VERSION ""

NS_ :

BS_:

BU_: MCTM_LS TIM_LS EOCM2cp_K2_LS EOCM2cp_K1_LS ADIMa_LS BCM_LS SAM_SR_LS SAM_SL_LS SAM_PR_LS SAM_PL_LS CGM3a_LS Dummy_LS VICM_LS ECC_LS PEPS_LS AOS_LS SDM_PR_LS AOS2_LS DLM_LS SCCM_2_LS SCCM_1_LS UPA_LS ADIMb_LS

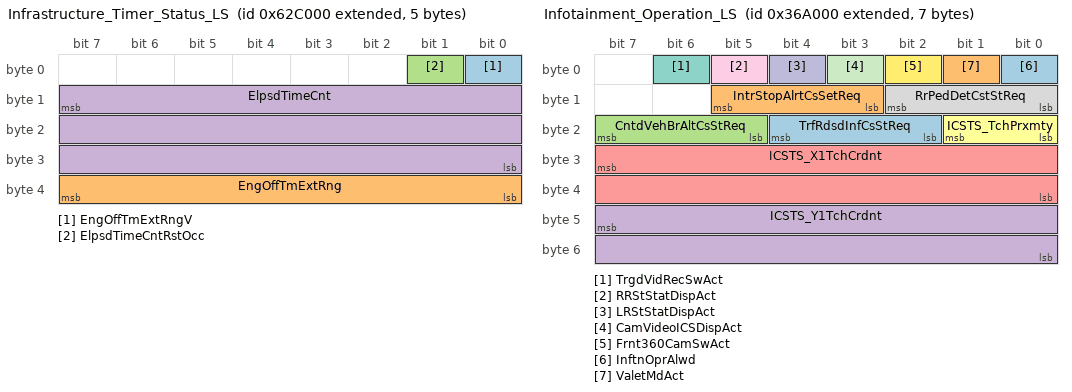
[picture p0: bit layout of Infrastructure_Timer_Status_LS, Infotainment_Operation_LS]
BO_ 2153955328 Infrastructure_Timer_Status_LS: 5 BCM_LS
 SG_ EngOffTmExtRngV : 0|1@0+ (1,0) [0|1] ""  CGM3a_LS,ECC_LS
 SG_ EngOffTmExtRng : 39|8@0+ (4,0) [0|1020] "min"  CGM3a_LS,ECC_LS
 SG_ ElpsdTimeCntRstOcc : 1|1@0+ (1,0) [0|1] ""  CGM3a_LS
 SG_ ElpsdTimeCnt : 15|24@0+ (1,0) [0|16777215] "min"  CGM3a_LS

BO_ 2151063552 Infotainment_Operation_LS: 7 CGM3a_LS
 SG_ TrfRdsdInfCsStReq : 20|3@0+ (1,0) [0|7] "" Vector__XXX
 SG_ IntrStopAlrtCsSetReq : 13|3@0+ (1,0) [0|7] "" Vector__XXX
 SG_ CntdVehBrAltCsStReq : 23|3@0+ (1,0) [0|7] "" Vector__XXX
 SG_ ICSTS_Y1TchCrdnt : 47|16@0+ (0.001526,0) [0|100] "" Vector__XXX
 SG_ ICSTS_X1TchCrdnt : 31|16@0+ (0.001526,0) [0|100] "" Vector__XXX
 SG_ ICSTS_TchPrxmty : 17|2@0+ (1,0) [0|3] "" Vector__XXX
 SG_ TrgdVidRecSwAct : 6|1@0+ (1,0) [0|1] "" Vector__XXX
 SG_ RrPedDetCstStReq : 10|3@0+ (1,0) [0|7] "" Vector__XXX
 SG_ RRStStatDispAct : 5|1@0+ (1,0) [0|1] "" Vector__XXX
 SG_ LRStStatDispAct : 4|1@0+ (1,0) [0|1] "" Vector__XXX
 SG_ CamVideoICSDispAct : 3|1@0+ (1,0) [0|1] "" Vector__XXX
 SG_ Frnt360CamSwAct : 2|1@0+ (1,0) [0|1] "" Vector__XXX
 SG_ InftnOprAlwd : 0|1@0+ (1,0) [0|1] ""  BCM_LS,MCTM_LS
 SG_ ValetMdAct : 1|1@0+ (1,0) [0|1] ""  BCM_LS

BO_ 2157985792 Fob_Programming_Request_LS: 1 CGM3a_LS
 SG_ FobProgEvntRqd : 0|1@0+ (1,0) [0|1] ""  BCM_LS

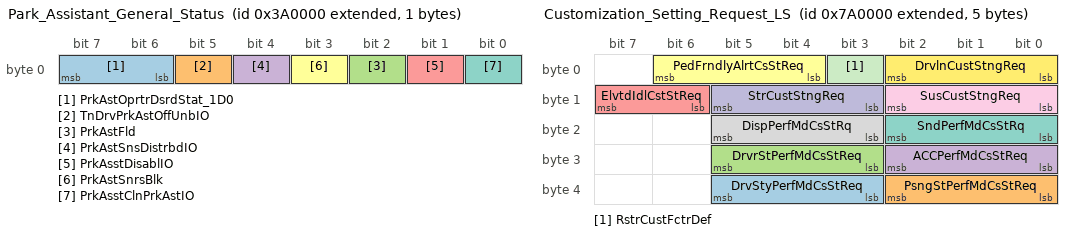
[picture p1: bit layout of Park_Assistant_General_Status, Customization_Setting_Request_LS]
BO_ 2151284736 Park_Assistant_General_Status: 1 UPA_LS
 SG_ PrkAstOprtrDsrdStat_1D0 : 7|2@0+ (1,0) [0|3] ""  CGM3a_LS
 SG_ TnDrvPrkAstOffUnbIO : 5|1@0+ (1,0) [0|1] ""  CGM3a_LS
 SG_ PrkAstFld : 2|1@0+ (1,0) [0|1] ""  CGM3a_LS
 SG_ PrkAstSnsDistrbdIO : 4|1@0+ (1,0) [0|1] ""  CGM3a_LS
 SG_ PrkAsstDisablIO : 1|1@0+ (1,0) [0|1] ""  CGM3a_LS
 SG_ PrkAstSnrsBlk : 3|1@0+ (1,0) [0|1] ""  CGM3a_LS
 SG_ PrkAsstClnPrkAstIO : 0|1@0+ (1,0) [0|1] ""  CGM3a_LS

BO_ 2151718912 Chime_Active: 1 CGM3a_LS
 SG_ ChmVolSt : 2|2@0+ (1,0) [0|3] ""  SAM_SR_LS,SAM_SL_LS,SAM_PR_LS,SAM_PL_LS,EOCM2cp_K2_LS
 SG_ ChmAct : 0|1@0+ (1,0) [0|1] ""  SAM_SR_LS,SAM_SL_LS,SAM_PR_LS,SAM_PL_LS,EOCM2cp_K2_LS,VICM_LS,UPA_LS,TIM_LS,SDM_PR_LS,MCTM_LS,BCM_LS

BO_ 2155479040 Customization_Setting_Request_LS: 5 CGM3a_LS
 SG_ DrvStyPerfMdCsStReq : 37|3@0+ (1,0) [0|7] ""  BCM_LS
 SG_ PsngStPerfMdCsStReq : 34|3@0+ (1,0) [0|7] ""  BCM_LS
 SG_ DrvrStPerfMdCsStReq : 29|3@0+ (1,0) [0|7] ""  BCM_LS
 SG_ ACCPerfMdCsStReq : 26|3@0+ (1,0) [0|7] ""  BCM_LS
 SG_ ElvtdIdlCstStReq : 15|2@0+ (1,0) [0|3] ""  BCM_LS
 SG_ PedFrndlyAlrtCsStReq : 6|3@0+ (1,0) [0|7] ""  BCM_LS
 SG_ SndPerfMdCsStRq : 18|3@0+ (1,0) [0|7] ""  BCM_LS
 SG_ DispPerfMdCsStRq : 21|3@0+ (1,0) [0|7] ""  BCM_LS
 SG_ SusCustStngReq : 10|3@0+ (1,0) [0|7] ""  BCM_LS
 SG_ StrCustStngReq : 13|3@0+ (1,0) [0|7] ""  BCM_LS
 SG_ RstrCustFctrDef : 3|1@0+ (1,0) [0|1] ""  VICM_LS,BCM_LS
 SG_ DrvlnCustStngReq : 2|3@0+ (1,0) [0|7] ""  BCM_LS

BO_ 2151383040 Reset_TP_request_LS: 1 CGM3a_LS
 SG_ TreInfMonSysRstReq : 0|1@0+ (1,0) [0|1] ""  BCM_LS

BO_ 1355 UUDT_Resp_From_EOCM2cp_K2_LS: 8 EOCM2cp_K2_LS
 SG_ DgnInf_LS54B : 7|64@0+ (1,0) [0|1.84467440737096E+019] ""  CGM3a_LS

BO_ 1611 USDT_Resp_From_EOCM2cp_K2_LS: 8 EOCM2cp_K2_LS
 SG_ DgnInf : 7|64@0+ (1,0) [0|1.84467440737096E+019] ""  CGM3a_LS

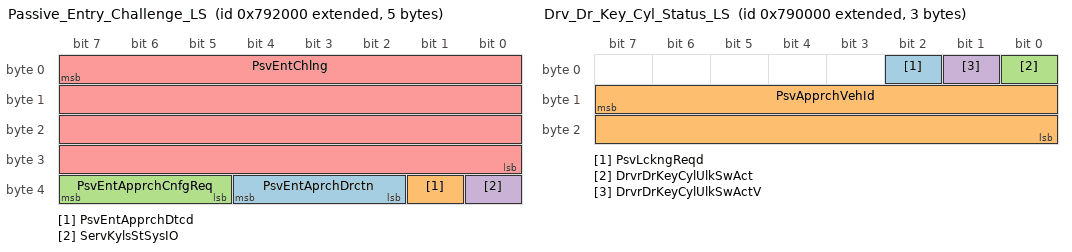
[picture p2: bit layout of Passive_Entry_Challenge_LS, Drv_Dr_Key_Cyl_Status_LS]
BO_ 2155421696 Passive_Entry_Challenge_LS: 5 PEPS_LS
 SG_ PsvEntAprchDrctn : 36|3@0+ (1,0) [0|7] ""  CGM3a_LS,BCM_LS
 SG_ PsvEntApprchDtcd : 33|1@0+ (1,0) [0|1] ""  CGM3a_LS,BCM_LS
 SG_ PsvEntApprchCnfgReq : 39|3@0+ (1,0) [0|7] ""  CGM3a_LS,BCM_LS
 SG_ ServKylsStSysIO : 32|1@0+ (1,0) [0|1] ""  CGM3a_LS
 SG_ PsvEntChlng : 7|32@0+ (1,0) [0|4294967295] "passwrd"  CGM3a_LS,BCM_LS

BO_ 2155413504 Drv_Dr_Key_Cyl_Status_LS: 3 BCM_LS
 SG_ PsvLckngReqd : 2|1@0+ (1,0) [0|1] ""  PEPS_LS,CGM3a_LS
 SG_ PsvApprchVehId : 15|16@0+ (1,0) [0|65535] ""  CGM3a_LS,PEPS_LS
 SG_ DrvrDrKeyCylUlkSwAct : 0|1@0+ (1,0) [0|1] ""  CGM3a_LS,PEPS_LS
 SG_ DrvrDrKeyCylUlkSwActV : 1|1@0+ (1,0) [0|1] ""  CGM3a_LS,PEPS_LS

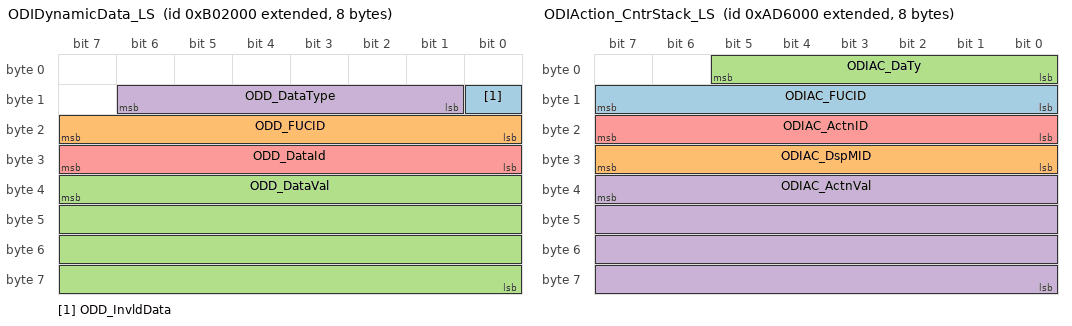
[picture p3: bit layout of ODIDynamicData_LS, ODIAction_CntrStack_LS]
BO_ 2159026176 ODIDynamicData_LS: 8 ECC_LS
 SG_ ODD_InvldData : 8|1@0+ (1,0) [0|1] ""  CGM3a_LS,MCTM_LS
 SG_ ODD_FUCID : 23|8@0+ (1,0) [0|255] ""  CGM3a_LS,MCTM_LS
 SG_ ODD_DataVal : 39|32@0+ (1,0) [0|4294967295] ""  CGM3a_LS,MCTM_LS
 SG_ ODD_DataType : 14|6@0+ (1,0) [0|63] ""  CGM3a_LS,MCTM_LS
 SG_ ODD_DataId : 31|8@0+ (1,0) [0|255] ""  CGM3a_LS,MCTM_LS

BO_ 2158936064 ODIEnumDynamicData_LS: 8 ECC_LS
 SG_ ODIEDD_Data18Value : 50|3@0+ (1,0) [0|7] ""  CGM3a_LS,MCTM_LS
 SG_ ODIEDD_Data17Value : 53|3@0+ (1,0) [0|7] ""  CGM3a_LS,MCTM_LS
 SG_ ODIEDD_Data16Value : 40|3@0+ (1,0) [0|7] ""  CGM3a_LS,MCTM_LS
 SG_ ODIEDD_Data15Value : 43|3@0+ (1,0) [0|7] ""  CGM3a_LS,MCTM_LS
 SG_ ODIEDD_Data14Value : 46|3@0+ (1,0) [0|7] ""  CGM3a_LS,MCTM_LS
 SG_ ODIEDD_Data13Value : 33|3@0+ (1,0) [0|7] ""  CGM3a_LS,MCTM_LS
 SG_ ODIEDD_Data12Value : 36|3@0+ (1,0) [0|7] ""  CGM3a_LS,MCTM_LS
 SG_ ODIEDD_Data11Value : 39|3@0+ (1,0) [0|7] ""  CGM3a_LS,MCTM_LS
 SG_ ODIEDD_Data10Value : 26|3@0+ (1,0) [0|7] ""  CGM3a_LS,MCTM_LS
 SG_ ODIEDD_Data9Value : 29|3@0+ (1,0) [0|7] ""  CGM3a_LS,MCTM_LS
 SG_ ODIEDD_Data8Value : 16|3@0+ (1,0) [0|7] ""  CGM3a_LS,MCTM_LS
 SG_ ODIEDD_Data7Value : 19|3@0+ (1,0) [0|7] ""  CGM3a_LS,MCTM_LS
 SG_ ODIEDD_Data6Value : 22|3@0+ (1,0) [0|7] ""  CGM3a_LS,MCTM_LS
 SG_ ODIEDD_Data5Value : 9|3@0+ (1,0) [0|7] ""  CGM3a_LS,MCTM_LS
 SG_ ODIEDD_Data4Value : 12|3@0+ (1,0) [0|7] ""  CGM3a_LS,MCTM_LS
 SG_ ODIEDD_Data3Value : 15|3@0+ (1,0) [0|7] ""  CGM3a_LS,MCTM_LS
 SG_ ODIEDD_Data2Value : 2|3@0+ (1,0) [0|7] ""  CGM3a_LS,MCTM_LS
 SG_ ODIEDD_Data1Value : 5|3@0+ (1,0) [0|7] ""  CGM3a_LS,MCTM_LS
 SG_ ODIEDD_FUCID : 63|8@0+ (1,0) [0|255] ""  CGM3a_LS,MCTM_LS

BO_ 2158845952 ODIAction_CntrStack_LS: 8 MCTM_LS
 SG_ ODIAC_FUCID : 15|8@0+ (1,0) [0|255] ""  CGM3a_LS,EOCM2cp_K2_LS,UPA_LS,BCM_LS,ECC_LS
 SG_ ODIAC_DspMID : 31|8@0+ (1,0) [0|255] ""  CGM3a_LS,EOCM2cp_K2_LS,UPA_LS,BCM_LS,ECC_LS
 SG_ ODIAC_DaTy : 5|6@0+ (1,0) [0|63] ""  CGM3a_LS,EOCM2cp_K2_LS,UPA_LS,BCM_LS,ECC_LS
 SG_ ODIAC_ActnVal : 39|32@0+ (1,0) [0|4294967295] ""  CGM3a_LS,EOCM2cp_K2_LS,UPA_LS,BCM_LS,ECC_LS
 SG_ ODIAC_ActnID : 23|8@0+ (1,0) [0|255] ""  CGM3a_LS,EOCM2cp_K2_LS,UPA_LS,BCM_LS,ECC_LS

BO_ 1596 VNMF_LS_63C: 8 CGM3a_LS
 SG_ VectraSpcNWMgtD : 7|64@0+ (1,0) [0|1.84467440737096E+019] ""  SAM_PL_LS,SAM_SL_LS,SAM_SR_LS,SAM_PR_LS,AOS2_LS,SCCM_2_LS,SCCM_1_LS,DLM_LS,TIM_LS,BCM_LS,AOS_LS,UPA_LS,VICM_LS,MCTM_LS,ADIMb_LS,CGM3a_LS,SDM_PR_LS,PEPS_LS,ECC_LS,EOCM2cp_K2_LS,ADIMa_LS

BO_ 2151366656 Man_Prk_Brk_LS: 1 BCM_LS
 SG_ PrkBrkSwAtv : 2|1@0+ (1,0) [0|1] ""  CGM3a_LS,UPA_LS

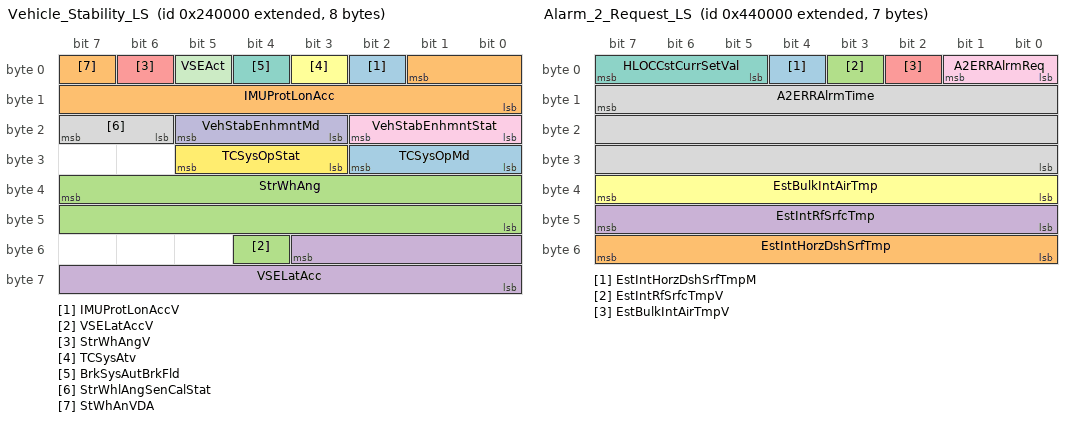
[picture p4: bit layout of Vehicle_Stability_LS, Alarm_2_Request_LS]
BO_ 2149842944 Vehicle_Stability_LS: 8 BCM_LS
 SG_ IMUProtLonAccV : 2|1@0+ (1,0) [0|1] ""  SAM_SR_LS,SAM_SL_LS,SAM_PR_LS,SAM_PL_LS,UPA_LS,CGM3a_LS
 SG_ IMUProtLonAcc : 1|10@0- (0.03,0) [-15.36|15.33] "m/s^2"  SAM_SR_LS,SAM_SL_LS,SAM_PR_LS,SAM_PL_LS,UPA_LS,CGM3a_LS
 SG_ VSELatAccV : 52|1@0+ (1,0) [0|1] ""  SAM_SR_LS,SAM_SL_LS,SAM_PR_LS,SAM_PL_LS,CGM3a_LS
 SG_ VSELatAcc : 51|12@0- (0.015625,0) [-32|31.984375] "m/s^2"  SAM_SR_LS,SAM_SL_LS,SAM_PR_LS,SAM_PL_LS,CGM3a_LS
 SG_ StrWhAngV : 6|1@0+ (1,0) [0|1] ""  SAM_SR_LS,SAM_SL_LS,SAM_PR_LS,SAM_PL_LS,SDM_PR_LS,CGM3a_LS,UPA_LS
 SG_ TCSysAtv : 3|1@0+ (1,0) [0|1] ""  SAM_SR_LS,SAM_SL_LS,SAM_PR_LS,SAM_PL_LS,CGM3a_LS
 SG_ BrkSysAutBrkFld : 4|1@0+ (1,0) [0|1] ""  SAM_SR_LS,SAM_SL_LS,SAM_PR_LS,SAM_PL_LS,CGM3a_LS
 SG_ StrWhlAngSenCalStat : 23|2@0+ (1,0) [0|3] ""  SAM_SR_LS,SAM_SL_LS,SAM_PR_LS,SAM_PL_LS,CGM3a_LS,UPA_LS
 SG_ VehStabEnhmntStat : 18|3@0+ (1,0) [0|7] ""  SAM_SR_LS,SAM_SL_LS,SAM_PR_LS,SAM_PL_LS,SDM_PR_LS,CGM3a_LS
 SG_ VehStabEnhmntMd : 21|3@0+ (1,0) [0|7] ""  SAM_SR_LS,SAM_SL_LS,SAM_PR_LS,SAM_PL_LS,CGM3a_LS
 SG_ VSEAct : 5|1@0+ (1,0) [0|1] ""  SAM_SR_LS,SAM_SL_LS,SAM_PR_LS,SAM_PL_LS,CGM3a_LS
 SG_ TCSysOpStat : 29|3@0+ (1,0) [0|7] ""  SAM_SR_LS,SAM_SL_LS,SAM_PR_LS,SAM_PL_LS,CGM3a_LS
 SG_ TCSysOpMd : 26|3@0+ (1,0) [0|7] ""  SAM_SR_LS,SAM_SL_LS,SAM_PR_LS,SAM_PL_LS,CGM3a_LS
 SG_ StWhAnVDA : 7|1@0+ (1,0) [0|1] ""  SAM_SR_LS,SAM_SL_LS,SAM_PR_LS,SAM_PL_LS,SDM_PR_LS,CGM3a_LS,UPA_LS
 SG_ StrWhAng : 39|16@0- (0.0625,0) [-2048|2047.9375] "deg"  SAM_SR_LS,SAM_SL_LS,SAM_PR_LS,SAM_PL_LS,SDM_PR_LS,CGM3a_LS,UPA_LS

BO_ 2151940096 Alarm_2_Request_LS: 7 ECC_LS
 SG_ EstIntHorzDshSrfTmpM : 4|1@0+ (1,0) [0|1] ""  CGM3a_LS,BCM_LS
 SG_ EstIntHorzDshSrfTmp : 55|8@0+ (1,-40) [-40|215] "deg C"  CGM3a_LS,BCM_LS
 SG_ EstIntRfSrfcTmpV : 3|1@0+ (1,0) [0|1] ""  CGM3a_LS
 SG_ EstIntRfSrfcTmp : 47|8@0+ (0.5,-40) [-40|87.5] "deg C"  CGM3a_LS
 SG_ EstBulkIntAirTmpV : 2|1@0+ (1,0) [0|1] ""  CGM3a_LS
 SG_ EstBulkIntAirTmp : 39|8@0+ (0.5,-40) [-40|87.5] "deg C"  CGM3a_LS
 SG_ HLOCCstCurrSetVal : 7|3@0+ (1,0) [0|7] "" Vector__XXX
 SG_ A2ERRAlrmTime : 15|24@0+ (1,0) [0|16777215] "min"  CGM3a_LS,BCM_LS
 SG_ A2ERRAlrmReq : 1|2@0+ (1,0) [0|3] ""  CGM3a_LS,BCM_LS

BO_ 2150645760 Environment_Id_Resp_1_LS: 3 SDM_PR_LS
 SG_ EnvIdRspSt1 : 17|2@0+ (1,0) [0|3] ""  CGM3a_LS,BCM_LS
 SG_ EnvIdRsp1 : 7|16@0+ (1,0) [0|65535] ""  CGM3a_LS,BCM_LS

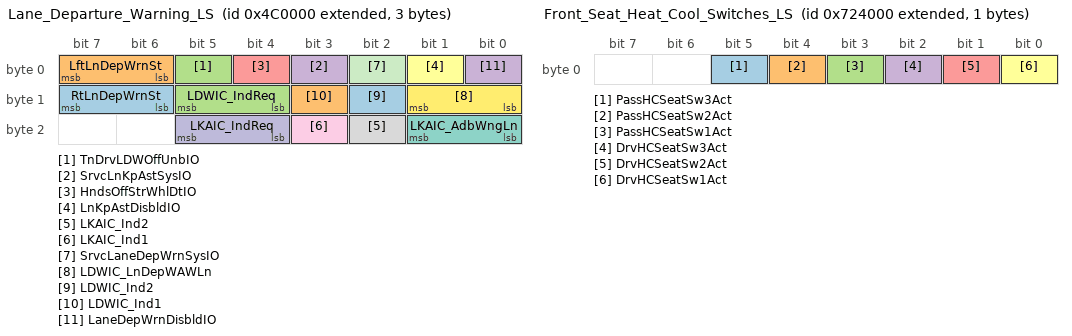
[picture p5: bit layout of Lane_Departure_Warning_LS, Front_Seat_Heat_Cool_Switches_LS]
BO_ 2152464384 Lane_Departure_Warning_LS: 3 EOCM2cp_K2_LS
 SG_ RtLnDepWrnSt : 15|2@0+ (1,0) [0|3] ""  CGM3a_LS
 SG_ LftLnDepWrnSt : 7|2@0+ (1,0) [0|3] ""  CGM3a_LS
 SG_ TnDrvLDWOffUnbIO : 5|1@0+ (1,0) [0|1] ""  CGM3a_LS
 SG_ SrvcLnKpAstSysIO : 3|1@0+ (1,0) [0|1] ""  CGM3a_LS,BCM_LS
 SG_ HndsOffStrWhlDtIO : 4|1@0+ (1,0) [0|1] ""  CGM3a_LS
 SG_ LnKpAstDisbldIO : 1|1@0+ (1,0) [0|1] ""  CGM3a_LS
 SG_ LKAIC_AdbWngLn : 17|2@0+ (1,0) [0|3] ""  CGM3a_LS,BCM_LS
 SG_ LKAIC_Ind2 : 18|1@0+ (1,0) [0|1] ""  CGM3a_LS,BCM_LS
 SG_ LKAIC_Ind1 : 19|1@0+ (1,0) [0|1] ""  CGM3a_LS,BCM_LS
 SG_ LKAIC_IndReq : 21|2@0+ (1,0) [0|3] ""  CGM3a_LS,BCM_LS
 SG_ SrvcLaneDepWrnSysIO : 2|1@0+ (1,0) [0|1] ""  CGM3a_LS,BCM_LS
 SG_ LDWIC_LnDepWAWLn : 9|2@0+ (1,0) [0|3] ""  CGM3a_LS,BCM_LS
 SG_ LDWIC_Ind2 : 10|1@0+ (1,0) [0|1] ""  CGM3a_LS,BCM_LS
 SG_ LDWIC_Ind1 : 11|1@0+ (1,0) [0|1] ""  CGM3a_LS,BCM_LS
 SG_ LDWIC_IndReq : 13|2@0+ (1,0) [0|3] ""  CGM3a_LS,BCM_LS
 SG_ LaneDepWrnDisbldIO : 0|1@0+ (1,0) [0|1] ""  CGM3a_LS

BO_ 2154971136 Front_Seat_Heat_Cool_Switches_LS: 1 ECC_LS
 SG_ PassHCSeatSw3Act : 5|1@0+ (1,0) [0|1] ""  CGM3a_LS,BCM_LS
 SG_ PassHCSeatSw2Act : 4|1@0+ (1,0) [0|1] ""  CGM3a_LS,BCM_LS
 SG_ PassHCSeatSw1Act : 3|1@0+ (1,0) [0|1] ""  CGM3a_LS,BCM_LS
 SG_ DrvHCSeatSw3Act : 2|1@0+ (1,0) [0|1] ""  CGM3a_LS,BCM_LS
 SG_ DrvHCSeatSw2Act : 1|1@0+ (1,0) [0|1] ""  CGM3a_LS,BCM_LS
 SG_ DrvHCSeatSw1Act : 0|1@0+ (1,0) [0|1] ""  CGM3a_LS,BCM_LS

BO_ 2154962944 Front_Seat_Heat_Cool_Control_LS: 4 BCM_LS
 SG_ PassHCSMInd3 : 8|1@0+ (1,0) [0|1] ""  CGM3a_LS,ECC_LS
 SG_ PassHCSMInd2 : 9|1@0+ (1,0) [0|1] ""  CGM3a_LS,ECC_LS
 SG_ PassHCSMInd1 : 10|1@0+ (1,0) [0|1] ""  CGM3a_LS,ECC_LS
 SG_ PassHCSMIndReq : 12|2@0+ (1,0) [0|3] ""  CGM3a_LS,ECC_LS
 SG_ PassHCSLSeatLev5 : 24|1@0+ (1,0) [0|1] ""  CGM3a_LS,ECC_LS
 SG_ PassHCSLSeatLev4 : 25|1@0+ (1,0) [0|1] ""  CGM3a_LS,ECC_LS
 SG_ PassHCSLSeatLev3 : 26|1@0+ (1,0) [0|1] ""  CGM3a_LS,ECC_LS
 SG_ PassHCSLSeatLev2 : 27|1@0+ (1,0) [0|1] ""  CGM3a_LS,ECC_LS
 SG_ PassHCSLSeatLev1 : 28|1@0+ (1,0) [0|1] ""  CGM3a_LS,ECC_LS
 SG_ PassHCSLIndReq : 30|2@0+ (1,0) [0|3] ""  CGM3a_LS,ECC_LS
 SG_ DrvHCSMInd1 : 2|1@0+ (1,0) [0|1] ""  CGM3a_LS,ECC_LS
 SG_ DrvHCSMIndReq : 4|2@0+ (1,0) [0|3] ""  CGM3a_LS,ECC_LS
 SG_ DrvHCSMInd3 : 0|1@0+ (1,0) [0|1] ""  CGM3a_LS,ECC_LS
 SG_ DrvHCSMInd2 : 1|1@0+ (1,0) [0|1] ""  CGM3a_LS,ECC_LS
 SG_ DrvHCSLSeatLev5 : 16|1@0+ (1,0) [0|1] ""  CGM3a_LS,ECC_LS
 SG_ DrvHCSLSeatLev4 : 17|1@0+ (1,0) [0|1] ""  CGM3a_LS,ECC_LS
 SG_ DrvHCSLSeatLev3 : 18|1@0+ (1,0) [0|1] ""  CGM3a_LS,ECC_LS
 SG_ DrvHCSLSeatLev2 : 19|1@0+ (1,0) [0|1] ""  CGM3a_LS,ECC_LS
 SG_ DrvHCSLSeatLev1 : 20|1@0+ (1,0) [0|1] ""  CGM3a_LS,ECC_LS
 SG_ DrvHCSLIndReq : 22|2@0+ (1,0) [0|3] ""  CGM3a_LS,ECC_LS

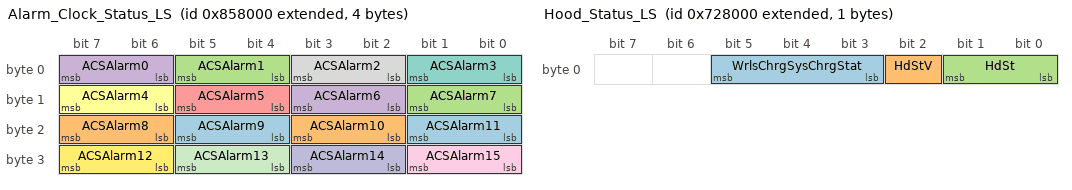
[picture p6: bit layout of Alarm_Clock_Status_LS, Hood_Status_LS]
BO_ 2156232704 Alarm_Clock_Status_LS: 4 BCM_LS
 SG_ ACSAlarm9 : 21|2@0+ (1,0) [0|3] ""  CGM3a_LS,ECC_LS
 SG_ ACSAlarm8 : 23|2@0+ (1,0) [0|3] ""  CGM3a_LS,ECC_LS
 SG_ ACSAlarm7 : 9|2@0+ (1,0) [0|3] ""  CGM3a_LS,ECC_LS
 SG_ ACSAlarm6 : 11|2@0+ (1,0) [0|3] ""  CGM3a_LS,ECC_LS
 SG_ ACSAlarm5 : 13|2@0+ (1,0) [0|3] ""  CGM3a_LS,ECC_LS
 SG_ ACSAlarm4 : 15|2@0+ (1,0) [0|3] ""  CGM3a_LS,ECC_LS
 SG_ ACSAlarm3 : 1|2@0+ (1,0) [0|3] ""  CGM3a_LS,ECC_LS
 SG_ ACSAlarm2 : 3|2@0+ (1,0) [0|3] ""  CGM3a_LS,ECC_LS
 SG_ ACSAlarm15 : 25|2@0+ (1,0) [0|3] ""  CGM3a_LS,ECC_LS
 SG_ ACSAlarm14 : 27|2@0+ (1,0) [0|3] ""  CGM3a_LS,ECC_LS
 SG_ ACSAlarm13 : 29|2@0+ (1,0) [0|3] ""  CGM3a_LS,ECC_LS
 SG_ ACSAlarm12 : 31|2@0+ (1,0) [0|3] ""  CGM3a_LS,ECC_LS
 SG_ ACSAlarm11 : 17|2@0+ (1,0) [0|3] ""  CGM3a_LS,ECC_LS
 SG_ ACSAlarm10 : 19|2@0+ (1,0) [0|3] ""  CGM3a_LS,ECC_LS
 SG_ ACSAlarm1 : 5|2@0+ (1,0) [0|3] ""  CGM3a_LS,ECC_LS
 SG_ ACSAlarm0 : 7|2@0+ (1,0) [0|3] ""  CGM3a_LS,ECC_LS

BO_ 2154987520 Hood_Status_LS: 1 BCM_LS
 SG_ WrlsChrgSysChrgStat : 5|3@0+ (1,0) [0|7] ""  ADIMa_LS,ADIMb_LS,CGM3a_LS
 SG_ HdStV : 2|1@0+ (1,0) [0|1] ""  ADIMa_LS,ADIMb_LS,CGM3a_LS
 SG_ HdSt : 1|2@0+ (1,0) [0|3] ""  ADIMa_LS,ADIMb_LS,CGM3a_LS

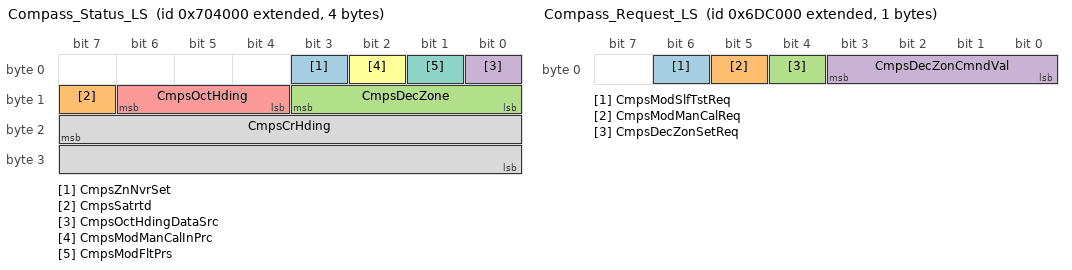
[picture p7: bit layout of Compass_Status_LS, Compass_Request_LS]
BO_ 2154840064 Compass_Status_LS: 4 BCM_LS
 SG_ CmpsZnNvrSet : 3|1@0+ (1,0) [0|1] ""  CGM3a_LS
 SG_ CmpsSatrtd : 15|1@0+ (1,0) [0|1] ""  CGM3a_LS
 SG_ CmpsDecZone : 11|4@0+ (1,0) [0|15] ""  CGM3a_LS
 SG_ CmpsOctHdingDataSrc : 0|1@0+ (1,0) [0|1] ""  CGM3a_LS
 SG_ CmpsOctHding : 14|3@0+ (1,0) [0|7] ""  CGM3a_LS
 SG_ CmpsModManCalInPrc : 2|1@0+ (1,0) [0|1] ""  CGM3a_LS
 SG_ CmpsModFltPrs : 1|1@0+ (1,0) [0|1] ""  CGM3a_LS
 SG_ CmpsCrHding : 23|16@0+ (0.0054932,0) [0|359.996862] "deg"  CGM3a_LS

BO_ 2154676224 Compass_Request_LS: 1 CGM3a_LS
 SG_ CmpsModSlfTstReq : 6|1@0+ (1,0) [0|1] ""  BCM_LS
 SG_ CmpsModManCalReq : 5|1@0+ (1,0) [0|1] ""  BCM_LS
 SG_ CmpsDecZonSetReq : 4|1@0+ (1,0) [0|1] ""  BCM_LS
 SG_ CmpsDecZonCmndVal : 3|4@0+ (1,0) [0|15] ""  BCM_LS

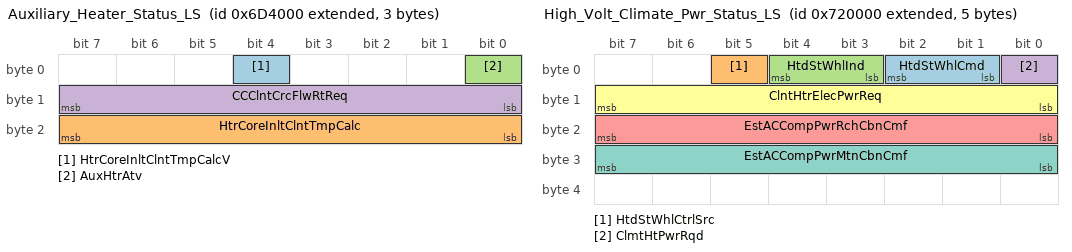
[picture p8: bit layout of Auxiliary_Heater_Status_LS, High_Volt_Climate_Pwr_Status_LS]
BO_ 2154643456 Auxiliary_Heater_Status_LS: 3 ECC_LS
 SG_ HtrCoreInltClntTmpCalcV : 4|1@0+ (1,0) [0|1] ""  CGM3a_LS,VICM_LS
 SG_ HtrCoreInltClntTmpCalc : 23|8@0+ (1,-40) [-40|215] "deg C"  CGM3a_LS,VICM_LS
 SG_ AuxHtrAtv : 0|1@0+ (1,0) [0|1] ""  CGM3a_LS,BCM_LS,ECC_LS
 SG_ CCClntCrcFlwRtReq : 15|8@0+ (0.392157,0) [0|100.000035] "%"  CGM3a_LS,VICM_LS,BCM_LS

BO_ 2154905600 Driver_Identifier_LS: 1 BCM_LS
 SG_ DrvSeatPrsMemID : 5|3@0+ (1,0) [0|7] ""  CGM3a_LS,EOCM2cp_K2_LS
 SG_ DrId : 2|3@0+ (1,0) [0|7] ""  CGM3a_LS,EOCM2cp_K2_LS,ECC_LS

BO_ 2154954752 High_Volt_Climate_Pwr_Status_LS: 5 ECC_LS
 SG_ HtdStWhlCmd : 2|2@0+ (1,0) [0|3] ""  CGM3a_LS,EOCM2cp_K2_LS
 SG_ HtdStWhlCtrlSrc : 5|1@0+ (1,0) [0|1] ""  CGM3a_LS,EOCM2cp_K2_LS
 SG_ HtdStWhlInd : 4|2@0+ (1,0) [0|3] ""  CGM3a_LS,EOCM2cp_K2_LS
 SG_ ClmtHtPwrRqd : 0|1@0+ (1,0) [0|1] ""  CGM3a_LS,VICM_LS
 SG_ EstACCompPwrRchCbnCmf : 23|8@0+ (0.04,0) [0|10.2] "kw"  CGM3a_LS,VICM_LS
 SG_ ClntHtrElecPwrReq : 15|8@0+ (0.04,0) [0|10.2] "kW"  CGM3a_LS
 SG_ EstACCompPwrMtnCbnCmf : 31|8@0+ (0.04,0) [0|10.2] "kW"  CGM3a_LS,VICM_LS

BO_ 2149752832 Chassis_Information_LS: 8 BCM_LS
 SG_ HlStrAssActIO : 41|1@0+ (1,0) [0|1] ""  CGM3a_LS
 SG_ GNCustSetngAvlbl : 44|1@0+ (1,0) [0|1] ""  CGM3a_LS
 SG_ GNCustCrntStngVal : 47|3@0+ (1,0) [0|7] ""  CGM3a_LS
 SG_ ColPrSysStngAvl : 42|1@0+ (1,0) [0|1] ""  CGM3a_LS
 SG_ ColPrSysCrntStng : 52|3@0+ (1,0) [0|7] ""  CGM3a_LS
 SG_ ElecPrkBrkStat : 39|2@0+ (1,0) [0|3] ""  CGM3a_LS,UPA_LS
 SG_ EBDFailed : 31|1@0+ (1,0) [0|1] ""  CGM3a_LS
 SG_ ABSAtv : 5|1@0+ (1,0) [0|1] ""  CGM3a_LS,SDM_PR_LS,UPA_LS
 SG_ PowStVDA : 13|1@0+ (1,0) [0|1] ""  CGM3a_LS
 SG_ RrDrCntVDA : 14|1@0+ (1,0) [0|1] ""  CGM3a_LS
 SG_ SprTireSt : 18|3@0+ (1,0) [0|7] ""  CGM3a_LS,UPA_LS
 SG_ BrkSysVDA : 15|1@0+ (1,0) [0|1] ""  CGM3a_LS,SDM_PR_LS,UPA_LS
 SG_ IntBrkAssPreFilReq : 1|1@0+ (1,0) [0|1] "N/A"  CGM3a_LS
 SG_ EPBSysDspMsgReq : 23|3@0+ (1,0) [0|7] ""  CGM3a_LS
 SG_ EPBSysAudWarnReq : 20|2@0+ (1,0) [0|3] ""  CGM3a_LS
 SG_ BksOvht : 2|1@0+ (1,0) [0|1] ""  CGM3a_LS
 SG_ BrkSysRedBrkTlltlReq : 4|1@0+ (1,0) [0|1] ""  CGM3a_LS
 SG_ HalfSysFail : 3|1@0+ (1,0) [0|1] ""  CGM3a_LS
 SG_ PrkBrkVDA : 12|1@0+ (1,0) [0|1] ""  CGM3a_LS,UPA_LS

BO_ 2151514112 Reset_OilLife_Request_LS: 1 CGM3a_LS
 SG_ EngOilLfRstRq : 0|1@0+ (1,0) [0|1] ""  BCM_LS

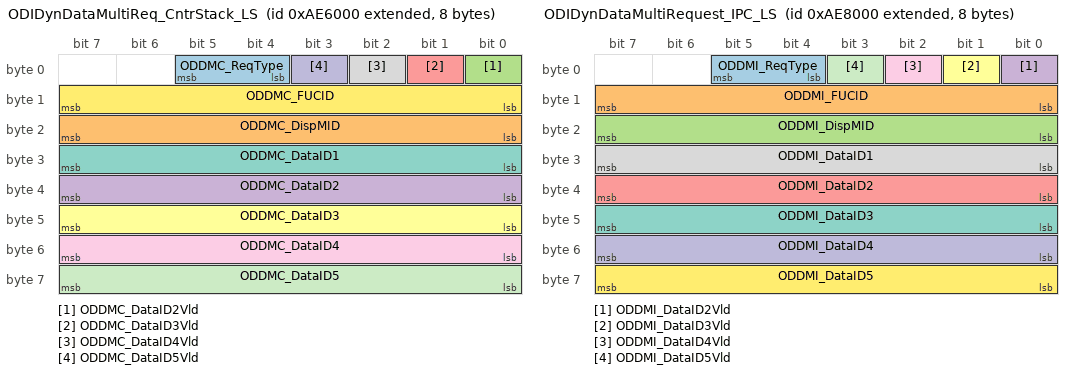
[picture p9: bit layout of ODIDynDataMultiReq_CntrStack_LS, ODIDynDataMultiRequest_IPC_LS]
BO_ 2158911488 ODIDynDataMultiReq_CntrStack_LS: 8 MCTM_LS
 SG_ ODDMC_ReqType : 5|2@0+ (1,0) [0|3] ""  CGM3a_LS,EOCM2cp_K2_LS,UPA_LS,BCM_LS,ECC_LS
 SG_ ODDMC_DispMID : 23|8@0+ (1,0) [0|255] ""  CGM3a_LS,EOCM2cp_K2_LS,UPA_LS,BCM_LS,ECC_LS
 SG_ ODDMC_DataID2Vld : 0|1@0+ (1,0) [0|1] ""  CGM3a_LS,EOCM2cp_K2_LS,UPA_LS,BCM_LS,ECC_LS
 SG_ ODDMC_DataID2 : 39|8@0+ (1,0) [0|255] ""  CGM3a_LS,EOCM2cp_K2_LS,UPA_LS,BCM_LS,ECC_LS
 SG_ ODDMC_DataID3Vld : 1|1@0+ (1,0) [0|1] ""  CGM3a_LS,EOCM2cp_K2_LS,UPA_LS,BCM_LS,ECC_LS
 SG_ ODDMC_DataID3 : 47|8@0+ (1,0) [0|255] ""  CGM3a_LS,EOCM2cp_K2_LS,UPA_LS,BCM_LS,ECC_LS
 SG_ ODDMC_DataID1 : 31|8@0+ (1,0) [0|255] ""  CGM3a_LS,EOCM2cp_K2_LS,UPA_LS,BCM_LS,ECC_LS
 SG_ ODDMC_DataID4Vld : 2|1@0+ (1,0) [0|1] ""  CGM3a_LS,EOCM2cp_K2_LS,UPA_LS,BCM_LS,ECC_LS
 SG_ ODDMC_DataID4 : 55|8@0+ (1,0) [0|255] ""  CGM3a_LS,EOCM2cp_K2_LS,UPA_LS,BCM_LS,ECC_LS
 SG_ ODDMC_DataID5Vld : 3|1@0+ (1,0) [0|1] ""  CGM3a_LS,EOCM2cp_K2_LS,UPA_LS,BCM_LS,ECC_LS
 SG_ ODDMC_DataID5 : 63|8@0+ (1,0) [0|255] ""  CGM3a_LS,EOCM2cp_K2_LS,UPA_LS,BCM_LS,ECC_LS
 SG_ ODDMC_FUCID : 15|8@0+ (1,0) [0|255] ""  CGM3a_LS,EOCM2cp_K2_LS,UPA_LS,BCM_LS,ECC_LS

BO_ 2158919680 ODIDynDataMultiRequest_IPC_LS: 8 CGM3a_LS
 SG_ ODDMI_ReqType : 5|2@0+ (1,0) [0|3] ""  EOCM2cp_K2_LS,UPA_LS,BCM_LS,ECC_LS
 SG_ ODDMI_FUCID : 15|8@0+ (1,0) [0|255] ""  EOCM2cp_K2_LS,UPA_LS,BCM_LS,ECC_LS
 SG_ ODDMI_DispMID : 23|8@0+ (1,0) [0|255] ""  EOCM2cp_K2_LS,UPA_LS,BCM_LS,ECC_LS
 SG_ ODDMI_DataID2Vld : 0|1@0+ (1,0) [0|1] ""  EOCM2cp_K2_LS,UPA_LS,BCM_LS,ECC_LS
 SG_ ODDMI_DataID2 : 39|8@0+ (1,0) [0|255] ""  EOCM2cp_K2_LS,UPA_LS,BCM_LS,ECC_LS
 SG_ ODDMI_DataID3Vld : 1|1@0+ (1,0) [0|1] ""  EOCM2cp_K2_LS,UPA_LS,BCM_LS,ECC_LS
 SG_ ODDMI_DataID3 : 47|8@0+ (1,0) [0|255] ""  EOCM2cp_K2_LS,UPA_LS,BCM_LS,ECC_LS
 SG_ ODDMI_DataID1 : 31|8@0+ (1,0) [0|255] ""  EOCM2cp_K2_LS,UPA_LS,BCM_LS,ECC_LS
 SG_ ODDMI_DataID4Vld : 2|1@0+ (1,0) [0|1] ""  EOCM2cp_K2_LS,UPA_LS,BCM_LS,ECC_LS
 SG_ ODDMI_DataID4 : 55|8@0+ (1,0) [0|255] ""  EOCM2cp_K2_LS,UPA_LS,BCM_LS,ECC_LS
 SG_ ODDMI_DataID5Vld : 3|1@0+ (1,0) [0|1] ""  EOCM2cp_K2_LS,UPA_LS,BCM_LS,ECC_LS
 SG_ ODDMI_DataID5 : 63|8@0+ (1,0) [0|255] ""  EOCM2cp_K2_LS,UPA_LS,BCM_LS,ECC_LS

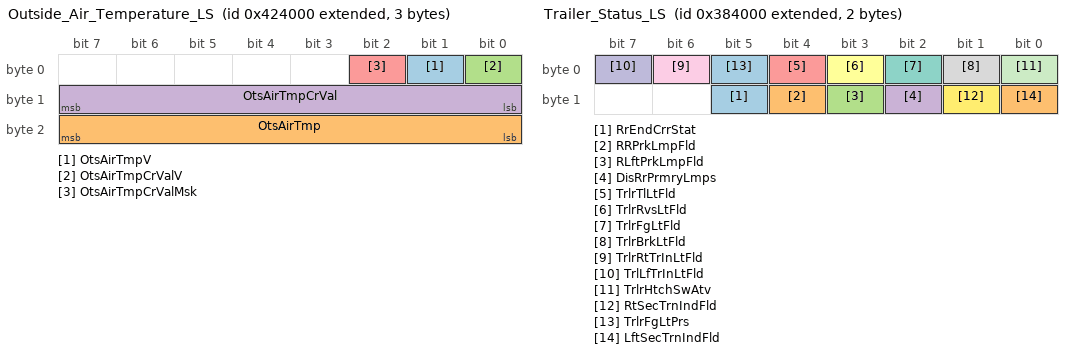
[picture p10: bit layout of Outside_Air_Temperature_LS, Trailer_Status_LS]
BO_ 2151825408 Outside_Air_Temperature_LS: 3 CGM3a_LS
 SG_ OtsAirTmpV : 1|1@0+ (1,0) [0|1] ""  SAM_SR_LS,SAM_SL_LS,SAM_PR_LS,SAM_PL_LS,EOCM2cp_K2_LS,CGM3a_LS,EOCM2cp_K1_LS,UPA_LS,BCM_LS,ECC_LS
 SG_ OtsAirTmp : 23|8@0+ (0.5,-40) [-40|87.5] "deg C"  SAM_SR_LS,SAM_SL_LS,SAM_PR_LS,SAM_PL_LS,MCTM_LS,CGM3a_LS,EOCM2cp_K2_LS,EOCM2cp_K1_LS,UPA_LS,BCM_LS,ECC_LS
 SG_ OtsAirTmpCrValV : 0|1@0+ (1,0) [0|1] ""  SAM_SR_LS,SAM_SL_LS,SAM_PR_LS,SAM_PL_LS,MCTM_LS,EOCM2cp_K2_LS,CGM3a_LS,EOCM2cp_K1_LS,SDM_PR_LS,UPA_LS,BCM_LS,ECC_LS
 SG_ OtsAirTmpCrVal : 15|8@0+ (0.5,-40) [-40|87.5] "deg C"  SAM_SR_LS,SAM_SL_LS,SAM_PR_LS,SAM_PL_LS,MCTM_LS,CGM3a_LS,EOCM2cp_K2_LS,EOCM2cp_K1_LS,SDM_PR_LS,BCM_LS,UPA_LS,ECC_LS
 SG_ OtsAirTmpCrValMsk : 2|1@0+ (1,0) [0|1] ""  SAM_SR_LS,SAM_SL_LS,SAM_PR_LS,SAM_PL_LS,MCTM_LS,CGM3a_LS,EOCM2cp_K2_LS,EOCM2cp_K1_LS,SDM_PR_LS,UPA_LS,BCM_LS,ECC_LS

BO_ 2151153664 Rear_Window_Defog_Status_LS: 1 ECC_LS
 SG_ RrWndDfgOn : 0|1@0+ (1,0) [0|1] ""  CGM3a_LS,BCM_LS

BO_ 2151170048 Trailer_Status_LS: 2 TIM_LS
 SG_ RrEndCrrStat : 13|1@0+ (1,0) [0|1] ""  CGM3a_LS,UPA_LS,BCM_LS
 SG_ RRPrkLmpFld : 12|1@0+ (1,0) [0|1] ""  CGM3a_LS
 SG_ RLftPrkLmpFld : 11|1@0+ (1,0) [0|1] ""  CGM3a_LS
 SG_ DisRrPrmryLmps : 10|1@0+ (1,0) [0|1] ""  CGM3a_LS,BCM_LS
 SG_ TrlrTlLtFld : 4|1@0+ (1,0) [0|1] ""  CGM3a_LS
 SG_ TrlrRvsLtFld : 3|1@0+ (1,0) [0|1] ""  CGM3a_LS
 SG_ TrlrFgLtFld : 2|1@0+ (1,0) [0|1] ""  CGM3a_LS
 SG_ TrlrBrkLtFld : 1|1@0+ (1,0) [0|1] ""  CGM3a_LS
 SG_ TrlrRtTrInLtFld : 6|1@0+ (1,0) [0|1] ""  CGM3a_LS,BCM_LS
 SG_ TrlLfTrInLtFld : 7|1@0+ (1,0) [0|1] ""  CGM3a_LS,BCM_LS
 SG_ TrlrHtchSwAtv : 0|1@0+ (1,0) [0|1] ""  CGM3a_LS,UPA_LS,BCM_LS
 SG_ RtSecTrnIndFld : 9|1@0+ (1,0) [0|1] ""  CGM3a_LS,BCM_LS
 SG_ TrlrFgLtPrs : 5|1@0+ (1,0) [0|1] ""  CGM3a_LS,BCM_LS
 SG_ LftSecTrnIndFld : 8|1@0+ (1,0) [0|1] ""  CGM3a_LS,BCM_LS

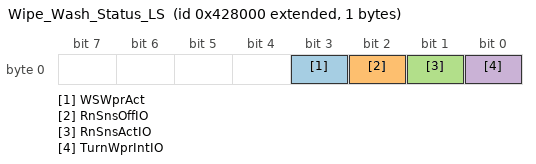
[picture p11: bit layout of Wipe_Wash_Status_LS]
BO_ 2151841792 Wipe_Wash_Status_LS: 1 BCM_LS
 SG_ WSWprAct : 3|1@0+ (1,0) [0|1] ""  CGM3a_LS,EOCM2cp_K2_LS
 SG_ RnSnsOffIO : 2|1@0+ (1,0) [0|1] ""  CGM3a_LS,EOCM2cp_K2_LS
 SG_ RnSnsActIO : 1|1@0+ (1,0) [0|1] ""  CGM3a_LS,EOCM2cp_K2_LS
 SG_ TurnWprIntIO : 0|1@0+ (1,0) [0|1] ""  CGM3a_LS,EOCM2cp_K2_LS

BO_ 2154995712 Air_Conditioning_Comp_Type_LS: 1 ECC_LS
 SG_ HVHtrFldIO : 4|1@0+ (1,0) [0|1] ""  CGM3a_LS
 SG_ HVHtrOvrTmpIndOn : 3|1@0+ (1,0) [0|1] ""  CGM3a_LS

BO_ 2154094592 Adjustable_Pedal_Motion_Inh_LS: 8 BCM_LS
 SG_ IntDimSeldClrTypStVal : 12|5@0+ (1,0) [0|31] ""  CGM3a_LS
 SG_ IntDimSeldAnmTypStVal : 4|4@0+ (1,0) [0|15] ""  CGM3a_LS
 SG_ IDCTA_ClrTyp30Avl : 56|1@0+ (1,0) [0|1] ""  CGM3a_LS
 SG_ IDCTA_ClrTyp29Avl : 57|1@0+ (1,0) [0|1] ""  CGM3a_LS
 SG_ IDCTA_ClrTyp28Avl : 58|1@0+ (1,0) [0|1] ""  CGM3a_LS
 SG_ IDCTA_ClrTyp27Avl : 59|1@0+ (1,0) [0|1] ""  CGM3a_LS
 SG_ IDCTA_ClrTyp26Avl : 60|1@0+ (1,0) [0|1] ""  CGM3a_LS
 SG_ IDCTA_ClrTyp25Avl : 61|1@0+ (1,0) [0|1] ""  CGM3a_LS
 SG_ IDCTA_ClrTyp24Avl : 62|1@0+ (1,0) [0|1] ""  CGM3a_LS
 SG_ IDCTA_ClrTyp23Avl : 63|1@0+ (1,0) [0|1] ""  CGM3a_LS
 SG_ IDCTA_ClrTyp22Avl : 48|1@0+ (1,0) [0|1] ""  CGM3a_LS
 SG_ IDCTA_ClrTyp21Avl : 49|1@0+ (1,0) [0|1] ""  CGM3a_LS
 SG_ IDCTA_ClrTyp20Avl : 50|1@0+ (1,0) [0|1] ""  CGM3a_LS
 SG_ IDCTA_ClrTyp19Avl : 51|1@0+ (1,0) [0|1] ""  CGM3a_LS
 SG_ IDCTA_ClrTyp18Avl : 52|1@0+ (1,0) [0|1] ""  CGM3a_LS
 SG_ IDCTA_ClrTyp17Avl : 53|1@0+ (1,0) [0|1] ""  CGM3a_LS
 SG_ IDCTA_ClrTyp16Avl : 54|1@0+ (1,0) [0|1] ""  CGM3a_LS
 SG_ IDCTA_ClrTyp15Avl : 55|1@0+ (1,0) [0|1] ""  CGM3a_LS
 SG_ IDCTA_ClrTyp14Avl : 40|1@0+ (1,0) [0|1] ""  CGM3a_LS
 SG_ IDCTA_ClrTyp13Avl : 41|1@0+ (1,0) [0|1] ""  CGM3a_LS
 SG_ IDCTA_ClrTyp12Avl : 42|1@0+ (1,0) [0|1] ""  CGM3a_LS
 SG_ IDCTA_ClrTyp11Avl : 43|1@0+ (1,0) [0|1] ""  CGM3a_LS
 SG_ IDCTA_ClrTyp10Avl : 44|1@0+ (1,0) [0|1] ""  CGM3a_LS
 SG_ IDCTA_ClrTyp9Avl : 45|1@0+ (1,0) [0|1] ""  CGM3a_LS
 SG_ IDCTA_ClrTyp8Avl : 46|1@0+ (1,0) [0|1] ""  CGM3a_LS
 SG_ IDCTA_ClrTyp7Avl : 47|1@0+ (1,0) [0|1] ""  CGM3a_LS
 SG_ IDCTA_ClrTyp6Avl : 32|1@0+ (1,0) [0|1] ""  CGM3a_LS
 SG_ IDCTA_ClrTyp5Avl : 33|1@0+ (1,0) [0|1] ""  CGM3a_LS
 SG_ IDCTA_ClrTyp4Avl : 34|1@0+ (1,0) [0|1] ""  CGM3a_LS
 SG_ IDCTA_ClrTyp3Avl : 35|1@0+ (1,0) [0|1] ""  CGM3a_LS
 SG_ IDCTA_ClrTyp2Avl : 36|1@0+ (1,0) [0|1] ""  CGM3a_LS
 SG_ IDCTA_ClrTyp1Avl : 37|1@0+ (1,0) [0|1] ""  CGM3a_LS
 SG_ IDCTA_OffAvl : 38|1@0+ (1,0) [0|1] ""  CGM3a_LS
 SG_ IDATA_AnmTyp14Avl : 24|1@0+ (1,0) [0|1] ""  CGM3a_LS
 SG_ IDATA_AnmTyp13Avl : 25|1@0+ (1,0) [0|1] ""  CGM3a_LS
 SG_ IDATA_AnmTyp12Avl : 26|1@0+ (1,0) [0|1] ""  CGM3a_LS
 SG_ IDATA_AnmTyp11Avl : 27|1@0+ (1,0) [0|1] ""  CGM3a_LS
 SG_ IDATA_AnmTyp10Avl : 28|1@0+ (1,0) [0|1] ""  CGM3a_LS
 SG_ IDATA_AnmTyp9Avl : 29|1@0+ (1,0) [0|1] ""  CGM3a_LS
 SG_ IDATA_AnmTyp8Avl : 30|1@0+ (1,0) [0|1] ""  CGM3a_LS
 SG_ IDATA_AnmTyp7Avl : 31|1@0+ (1,0) [0|1] ""  CGM3a_LS
 SG_ IDATA_AnmTyp6Avl : 16|1@0+ (1,0) [0|1] ""  CGM3a_LS
 SG_ IDATA_AnmTyp5Avl : 17|1@0+ (1,0) [0|1] ""  CGM3a_LS
 SG_ IDATA_AnmTyp4Avl : 18|1@0+ (1,0) [0|1] ""  CGM3a_LS
 SG_ IDATA_AnmTyp3Avl : 19|1@0+ (1,0) [0|1] ""  CGM3a_LS
 SG_ IDATA_AnmTyp2Avl : 20|1@0+ (1,0) [0|1] ""  CGM3a_LS
 SG_ IDATA_AnmTyp1Avl : 21|1@0+ (1,0) [0|1] ""  CGM3a_LS
 SG_ IDATA_OffAvl : 22|1@0+ (1,0) [0|1] ""  CGM3a_LS
 SG_ AdjPdlMotInhbtd : 0|1@0+ (1,0) [0|1] ""  CGM3a_LS

BO_TX_BU_ 2151284736 : EOCM2cp_K2_LS,UPA_LS;
BO_TX_BU_ 2159026176 : BCM_LS,CGM3a_LS,ECC_LS;
BO_TX_BU_ 2158936064 : EOCM2cp_K2_LS,UPA_LS,BCM_LS,ECC_LS;
BO_TX_BU_ 2158845952 : CGM3a_LS,MCTM_LS;
BO_TX_BU_ 2154840064 : CGM3a_LS,BCM_LS;
BO_TX_BU_ 2158911488 : MCTM_LS,CGM3a_LS;
BO_TX_BU_ 2151825408 : BCM_LS,CGM3a_LS;
CM_ SG_ 2151284736 PrkAstSnsDistrbdIO "This signal turns on a warning that tells the driver that the Parking Assist is receiving ultrasonic input that essentially makes it blind.  The system is still enabled, there is no failure in the system, but it can't perform the function.";
CM_ SG_ 2159026176 ODD_InvldData "ODI";
CM_ SG_ 2159026176 ODD_FUCID "ODI - Primary ID of Functional Unit in FU Database";
CM_ SG_ 2159026176 ODD_DataVal "ODI";
CM_ SG_ 2159026176 ODD_DataType "ODI";
CM_ SG_ 2159026176 ODD_DataId "ODI-Data Id for the dynamic list";
CM_ SG_ 2158936064 ODIEDD_Data18Value "ODI";
CM_ SG_ 2158936064 ODIEDD_Data17Value "ODI";
CM_ SG_ 2158936064 ODIEDD_Data16Value "ODI";
CM_ SG_ 2158936064 ODIEDD_Data15Value "ODI";
CM_ SG_ 2158936064 ODIEDD_Data14Value "ODI";
CM_ SG_ 2158936064 ODIEDD_Data13Value "ODI";
CM_ SG_ 2158936064 ODIEDD_Data12Value "ODI";
CM_ SG_ 2158936064 ODIEDD_Data11Value "ODI";
CM_ SG_ 2158936064 ODIEDD_Data10Value "ODI";
CM_ SG_ 2158936064 ODIEDD_Data9Value "ODI";
CM_ SG_ 2158936064 ODIEDD_Data8Value "ODI";
CM_ SG_ 2158936064 ODIEDD_Data7Value "ODI";
CM_ SG_ 2158936064 ODIEDD_Data6Value "ODI";
CM_ SG_ 2158936064 ODIEDD_Data5Value "ODI";
CM_ SG_ 2158936064 ODIEDD_Data4Value "ODI";
CM_ SG_ 2158936064 ODIEDD_Data3Value "ODI";
CM_ SG_ 2158936064 ODIEDD_Data2Value "ODI";
CM_ SG_ 2158936064 ODIEDD_Data1Value "ODI";
CM_ SG_ 2158936064 ODIEDD_FUCID "ODI - Primary ID of Functional Unit in FU Database";
CM_ SG_ 2158845952 ODIAC_FUCID "ODI - Primary ID of Functional Unit in FU Database";
CM_ SG_ 2158845952 ODIAC_DspMID "ODI - ID that identifies the display requesting the data.  See detailed requirements in ODI GMLAN Protocol.";
CM_ SG_ 2158845952 ODIAC_ActnVal "ODI-Integer value for Actions with values.
FUDatabase definition of Action includes ActionDataType that defines whether or not Action has a value. 
For Actions without a value, this field is always sent as 0.";
CM_ SG_ 2158845952 ODIAC_ActnID "ODI-ActionId within the FUClass";
CM_ SG_ 2149842944 BrkSysAutBrkFld "BrakeSystemAutomaticBrakingFailed";
CM_ BO_ 2154987520 "LAP: Är det rätt Tx??? passar i frame0x130??";
CM_ SG_ 2154840064 CmpsCrHding "i.e., adjusted for declination zone, hysterisis, and filtering)";
CM_ SG_ 2154643456 AuxHtrAtv "Auxiliary Heater shall be used to denote a heater function that uses some kind of power, electrical or mechanical,  that was generated by the engine.";
CM_ SG_ 2154905600 DrId "Driver 8 changed to Unknown on 3/30/99";
CM_ SG_ 2149752832 IntBrkAssPreFilReq "IntelligentBrakeAssistPreFillRequest";
CM_ SG_ 2149752832 BrkSysRedBrkTlltlReq "Added acc to Björn 0410";
CM_ SG_ 2158911488 ODDMC_ReqType "ODI - Type of Request";
CM_ SG_ 2158911488 ODDMC_DispMID "ODI - ID that identifies the display requesting the data.  See detailed requirements in ODI GMLAN Protocol.";
CM_ SG_ 2158911488 ODDMC_DataID2Vld "ODI -DataIDTwo is being requested as a valid ID.";
CM_ SG_ 2158911488 ODDMC_DataID2 "ODI - ID for the second requested data parameter as defined in the FUDatabase";
CM_ SG_ 2158911488 ODDMC_DataID3Vld "ODI -DataIDThree is being requested as a valid ID.";
CM_ SG_ 2158911488 ODDMC_DataID3 "ODI - ID for the third requested data parameter as defined in the FUDatabase";
CM_ SG_ 2158911488 ODDMC_DataID1 "ODI - ID for the first requested data parameter as defined in the FUDatabase";
CM_ SG_ 2158911488 ODDMC_DataID4Vld "ODI -DataIDFour is being requested as a valid ID.";
CM_ SG_ 2158911488 ODDMC_DataID4 "ODI - ID for the fourth requested data parameter as defined in the FUDatabase";
CM_ SG_ 2158911488 ODDMC_DataID5Vld "ODI -DataIDFive is being requested as a valid ID.";
CM_ SG_ 2158911488 ODDMC_DataID5 "ODI - ID for the fifth requested data parameter as defined in the FUDatabase";
CM_ SG_ 2158911488 ODDMC_FUCID "ODI - Primary ID of Functional Unit in FU Database";
CM_ SG_ 2158919680 ODDMI_ReqType "ODI - Type of Request";
CM_ SG_ 2158919680 ODDMI_FUCID "ODI - Primary ID of Functional Unit in FU Database";
CM_ SG_ 2158919680 ODDMI_DispMID "ODI - ID that identifies the display requesting the data.  See detailed requirements in ODI GMLAN Protocol.";
CM_ SG_ 2158919680 ODDMI_DataID2Vld "ODI -DataIDTwo is being requested as a valid ID.";
CM_ SG_ 2158919680 ODDMI_DataID2 "ODI - ID for the second requested data parameter as defined in the FUDatabase";
CM_ SG_ 2158919680 ODDMI_DataID3Vld "ODI -DataIDThree is being requested as a valid ID.";
CM_ SG_ 2158919680 ODDMI_DataID3 "ODI - ID for the third requested data parameter as defined in the FUDatabase";
CM_ SG_ 2158919680 ODDMI_DataID1 "ODI - ID for the first requested data parameter as defined in the FUDatabase";
CM_ SG_ 2158919680 ODDMI_DataID4Vld "ODI -DataIDFour is being requested as a valid ID.";
CM_ SG_ 2158919680 ODDMI_DataID4 "ODI - ID for the fourth requested data parameter as defined in the FUDatabase";
CM_ SG_ 2158919680 ODDMI_DataID5Vld "ODI -DataIDFive is being requested as a valid ID.";
CM_ SG_ 2158919680 ODDMI_DataID5 "ODI - ID for the fifth requested data parameter as defined in the FUDatabase";
BA_DEF_ SG_  "VNSigPrimaryTriggering" ENUM  "No","Yes";
BA_DEF_ SG_  "VNSigRemoteDiagnostics" ENUM  "No","Yes";
BA_DEF_ SG_  "VNSigInfotainment" ENUM  "No","Yes";
BA_DEF_ SG_  "VNSigParkedVehicle" ENUM  "No","Yes";
BA_DEF_ SG_  "VNSigIntermediate" ENUM  "No","Yes";
BA_DEF_ SG_  "VNSigUnused_4" ENUM  "No","Yes";
BA_DEF_ SG_  "SignalType" STRING ;
BA_DEF_ SG_  "PacketOrder" INT 0 65535;
BA_DEF_ SG_  "SignalLongName" STRING ;
BA_DEF_ SG_  "GenSigStartValue" INT 0 65535;
BA_DEF_ SG_  "VNSigDiagnostic" ENUM  "No","Yes";
BA_DEF_ SG_  "VNSigAllNodes" ENUM  "No","Yes";
BA_DEF_ SG_  "GenSigDeltaValue" INT 0 0;
BA_DEF_ SG_  "GenSigSendType" ENUM  "not used","not used","not used","not used","not used","not used","not used","NoSigSendType","not used","not used","OnAnyChange","OnChangeIfActive","OnDelta";
BA_DEF_ SG_  "GenSigSendOnInit" ENUM  "Not Initialized","Application","Handler";
BA_DEF_ BO_  "AppGenMsgCycleTime" INT 0 0;
BA_DEF_ BO_  "TpTxIndex" INT 0 99;
BA_DEF_ BO_  "GenMsgILSupport" ENUM  "No","Yes";
BA_DEF_ BO_  "TpApplType" STRING ;
BA_DEF_ BO_  "Prio" INT 0 7;
BA_DEF_ BO_  "MessageSubnet" ENUM  "LS","HS","CE","PE","HV","FO","LE","HE2","PHS","PCE","DLCLS","DLCHS","DLCCE","DLCFO";
BA_DEF_ BO_  "GenMsgMandatoryToSupervision" ENUM  "No","Yes";
BA_DEF_ BO_  "DiagState" ENUM  "No","Yes";
BA_DEF_ BO_  "GenMsgStartDelayTime" INT 0 100000;
BA_DEF_ BO_  "GenMsgDelayTime" INT 0 100000;
BA_DEF_ BO_  "GenMsgCycleTime" INT 0 100000;
BA_DEF_ BO_  "GenMsgCycleTimeFast" INT 0 100000;
BA_DEF_ BO_  "GenMsgSendType" ENUM  "cyclicX","spontanX","cyclicIfActiveX","spontanWithDelay","cyclicAndSpontanX","cyclicAndSpontanWithDelay","spontanWithRepitition","cyclicIfActiveAndSpontanWD";
BA_DEF_ BO_  "DiagResponse" ENUM  "No","Yes";
BA_DEF_ BO_  "DiagRequest" ENUM  "No","Yes";
BA_DEF_ BO_  "NmMessage" ENUM  "No","Yes";
BA_DEF_REL_ BU_SG_REL_  "GenSigSuprvRespComment" STRING ;
BA_DEF_REL_ BU_SG_REL_  "GenSigVBitResp" ENUM  "No","Yes";
BA_DEF_REL_ BU_SG_REL_  "GenSigVBitRespComment" STRING ;
BA_DEF_REL_ BU_SG_REL_  "GenSigVDAFailComment" STRING ;
BA_DEF_REL_ BU_SG_REL_  "GenSigVDAFailResp" ENUM  "No","Yes";
BA_DEF_REL_ BU_SG_REL_  "GenSigRxStartValue" STRING ;
BA_DEF_REL_ BU_SG_REL_  "GenSigSuprvRespSubValue" INT 0 65535;
BA_DEF_REL_ BU_SG_REL_  "GenSigSuprvResp" ENUM  "None","Notify App","Substitute Default";
BA_DEF_REL_ BU_SG_REL_  "GenSigTimeoutMsg" HEX 0 268435455;
BA_DEF_REL_ BU_SG_REL_  "GenSigTimeoutTime" INT 0 15000;
BA_DEF_DEF_  "VNSigPrimaryTriggering" "No";
BA_DEF_DEF_  "VNSigRemoteDiagnostics" "No";
BA_DEF_DEF_  "VNSigInfotainment" "No";
BA_DEF_DEF_  "VNSigParkedVehicle" "No";
BA_DEF_DEF_  "VNSigIntermediate" "No";
BA_DEF_DEF_  "VNSigUnused_4" "No";
BA_DEF_DEF_  "SignalType" "";
BA_DEF_DEF_  "PacketOrder" 0;
BA_DEF_DEF_  "SignalLongName" "";
BA_DEF_DEF_  "GenSigStartValue" 0;
BA_DEF_DEF_  "VNSigDiagnostic" "No";
BA_DEF_DEF_  "VNSigAllNodes" "No";
BA_DEF_DEF_  "GenSigDeltaValue" 0;
BA_DEF_DEF_  "GenSigSendType" "NoSigSendType";
BA_DEF_DEF_  "GenSigSendOnInit" "Not Initialized";
BA_DEF_DEF_  "AppGenMsgCycleTime" 0;
BA_DEF_DEF_  "TpTxIndex" 0;
BA_DEF_DEF_  "GenMsgILSupport" "Yes";
BA_DEF_DEF_  "TpApplType" "";
BA_DEF_DEF_  "Prio" 4;
BA_DEF_DEF_  "MessageSubnet" "LS";
BA_DEF_DEF_  "GenMsgMandatoryToSupervision" "No";
BA_DEF_DEF_  "DiagState" "No";
BA_DEF_DEF_  "GenMsgStartDelayTime" 0;
BA_DEF_DEF_  "GenMsgDelayTime" 0;
BA_DEF_DEF_  "GenMsgCycleTime" 0;
BA_DEF_DEF_  "GenMsgCycleTimeFast" 0;
BA_DEF_DEF_  "GenMsgSendType" "spontanX";
BA_DEF_DEF_  "DiagResponse" "No";
BA_DEF_DEF_  "DiagRequest" "No";
BA_DEF_DEF_  "NmMessage" "No";
BA_DEF_DEF_REL_ "GenSigSuprvRespComment" "";
BA_DEF_DEF_REL_ "GenSigVBitResp" "No";
BA_DEF_DEF_REL_ "GenSigVBitRespComment" "";
BA_DEF_DEF_REL_ "GenSigVDAFailComment" "";
BA_DEF_DEF_REL_ "GenSigVDAFailResp" "No";
BA_DEF_DEF_REL_ "GenSigRxStartValue" "";
BA_DEF_DEF_REL_ "GenSigSuprvRespSubValue" 0;
BA_DEF_DEF_REL_ "GenSigSuprvResp" "None";
BA_DEF_DEF_REL_ "GenSigTimeoutMsg" 0;
BA_DEF_DEF_REL_ "GenSigTimeoutTime" 0;
BA_ "GenMsgDelayTime" BO_ 2153955328 100;
BA_ "GenMsgDelayTime" BO_ 2151063552 100;
BA_ "GenMsgDelayTime" BO_ 2157985792 100;
BA_ "GenMsgDelayTime" BO_ 2151284736 100;
BA_ "GenMsgDelayTime" BO_ 2151718912 10;
BA_ "GenMsgDelayTime" BO_ 2155479040 100;
BA_ "GenMsgDelayTime" BO_ 2151383040 100;
BA_ "GenMsgILSupport" BO_ 1355 0;
BA_ "TpApplType" BO_ 1355 "DiagUUDTResponse";
BA_ "Prio" BO_ 1355 0;
BA_ "GenMsgILSupport" BO_ 1611 0;
BA_ "Prio" BO_ 1611 0;
BA_ "DiagResponse" BO_ 1611 1;
BA_ "Prio" BO_ 2155421696 3;
BA_ "GenMsgDelayTime" BO_ 2155421696 100;
BA_ "GenMsgDelayTime" BO_ 2155413504 100;
BA_ "GenMsgDelayTime" BO_ 2159026176 10;
BA_ "GenMsgDelayTime" BO_ 2158936064 100;
BA_ "GenMsgDelayTime" BO_ 2158845952 20;
BA_ "Prio" BO_ 1596 0;
BA_ "GenMsgCycleTime" BO_ 1596 3000;
BA_ "GenMsgSendType" BO_ 1596 0;
BA_ "NmMessage" BO_ 1596 1;
BA_ "GenMsgDelayTime" BO_ 2151366656 100;
BA_ "GenMsgStartDelayTime" BO_ 2149842944 160;
BA_ "GenMsgCycleTime" BO_ 2149842944 100;
BA_ "GenMsgSendType" BO_ 2149842944 0;
BA_ "GenMsgDelayTime" BO_ 2151940096 100;
BA_ "GenMsgDelayTime" BO_ 2150645760 100;
BA_ "GenMsgDelayTime" BO_ 2152464384 100;
BA_ "GenMsgDelayTime" BO_ 2154971136 100;
BA_ "GenMsgDelayTime" BO_ 2154962944 100;
BA_ "GenMsgDelayTime" BO_ 2156232704 100;
BA_ "GenMsgDelayTime" BO_ 2154987520 100;
BA_ "GenMsgDelayTime" BO_ 2154840064 100;
BA_ "GenMsgDelayTime" BO_ 2154676224 100;
BA_ "GenMsgDelayTime" BO_ 2154643456 100;
BA_ "Prio" BO_ 2154905600 3;
BA_ "GenMsgDelayTime" BO_ 2154905600 100;
BA_ "GenMsgDelayTime" BO_ 2154954752 100;
BA_ "GenMsgStartDelayTime" BO_ 2149752832 110;
BA_ "GenMsgCycleTime" BO_ 2149752832 250;
BA_ "GenMsgSendType" BO_ 2149752832 0;
BA_ "GenMsgDelayTime" BO_ 2151514112 100;
BA_ "GenMsgDelayTime" BO_ 2158911488 20;
BA_ "GenMsgDelayTime" BO_ 2158919680 20;
BA_ "GenMsgDelayTime" BO_ 2151825408 100;
BA_ "GenMsgDelayTime" BO_ 2151153664 100;
BA_ "GenMsgDelayTime" BO_ 2151170048 100;
BA_ "GenMsgDelayTime" BO_ 2151841792 100;
BA_ "GenMsgDelayTime" BO_ 2154995712 100;
BA_ "GenMsgDelayTime" BO_ 2154094592 100;
BA_ "GenSigSendType" SG_ 2153955328 EngOffTmExtRngV 10;
BA_ "VNSigInfotainment" SG_ 2153955328 EngOffTmExtRngV 1;
BA_ "SignalType" SG_ 2153955328 EngOffTmExtRngV "ENM";
BA_ "SignalLongName" SG_ 2153955328 EngOffTmExtRngV "Engine Off Time Extended Range Validity";
BA_ "VNSigAllNodes" SG_ 2153955328 EngOffTmExtRngV 1;
BA_ "GenSigDeltaValue" SG_ 2153955328 EngOffTmExtRng 1;
BA_ "GenSigSendType" SG_ 2153955328 EngOffTmExtRng 12;
BA_ "GenSigSendOnInit" SG_ 2153955328 EngOffTmExtRng 2;
BA_ "VNSigInfotainment" SG_ 2153955328 EngOffTmExtRng 1;
BA_ "SignalType" SG_ 2153955328 EngOffTmExtRng "UNM";
BA_ "SignalLongName" SG_ 2153955328 EngOffTmExtRng "Engine Off Time Extended Range";
BA_ "VNSigAllNodes" SG_ 2153955328 EngOffTmExtRng 1;
BA_ "GenSigSendType" SG_ 2153955328 ElpsdTimeCntRstOcc 10;
BA_ "SignalType" SG_ 2153955328 ElpsdTimeCntRstOcc "BLN";
BA_ "SignalLongName" SG_ 2153955328 ElpsdTimeCntRstOcc "Elapsed Time Count Reset Occurred";
BA_ "VNSigAllNodes" SG_ 2153955328 ElpsdTimeCntRstOcc 1;
BA_ "GenSigDeltaValue" SG_ 2153955328 ElpsdTimeCnt 1;
BA_ "GenSigSendType" SG_ 2153955328 ElpsdTimeCnt 12;
BA_ "SignalType" SG_ 2153955328 ElpsdTimeCnt "UNM";
BA_ "SignalLongName" SG_ 2153955328 ElpsdTimeCnt "Elapsed Time Count";
BA_ "VNSigAllNodes" SG_ 2153955328 ElpsdTimeCnt 1;
BA_ "GenSigSendType" SG_ 2151063552 TrfRdsdInfCsStReq 10;
BA_ "SignalType" SG_ 2151063552 TrfRdsdInfCsStReq "ENM";
BA_ "SignalLongName" SG_ 2151063552 TrfRdsdInfCsStReq "Traffic and Roadside Information Customization Setting Request";
BA_ "VNSigAllNodes" SG_ 2151063552 TrfRdsdInfCsStReq 1;
BA_ "GenSigSendType" SG_ 2151063552 IntrStopAlrtCsSetReq 10;
BA_ "SignalType" SG_ 2151063552 IntrStopAlrtCsSetReq "ENM";
BA_ "SignalLongName" SG_ 2151063552 IntrStopAlrtCsSetReq "Intersection Stop Alert Customization Setting Request";
BA_ "VNSigAllNodes" SG_ 2151063552 IntrStopAlrtCsSetReq 1;
BA_ "GenSigSendType" SG_ 2151063552 CntdVehBrAltCsStReq 10;
BA_ "SignalType" SG_ 2151063552 CntdVehBrAltCsStReq "ENM";
BA_ "SignalLongName" SG_ 2151063552 CntdVehBrAltCsStReq "Connected Vehicle Braking Alerts Customization Setting Request";
BA_ "VNSigAllNodes" SG_ 2151063552 CntdVehBrAltCsStReq 1;
BA_ "GenSigDeltaValue" SG_ 2151063552 ICSTS_Y1TchCrdnt 1;
BA_ "GenSigSendType" SG_ 2151063552 ICSTS_Y1TchCrdnt 12;
BA_ "PacketOrder" SG_ 2151063552 ICSTS_Y1TchCrdnt 3;
BA_ "SignalType" SG_ 2151063552 ICSTS_Y1TchCrdnt "UNM";
BA_ "SignalLongName" SG_ 2151063552 ICSTS_Y1TchCrdnt "Integrated Center Stack Touch Status : Y1 Touch Coordinate";
BA_ "VNSigAllNodes" SG_ 2151063552 ICSTS_Y1TchCrdnt 1;
BA_ "GenSigDeltaValue" SG_ 2151063552 ICSTS_X1TchCrdnt 1;
BA_ "GenSigSendType" SG_ 2151063552 ICSTS_X1TchCrdnt 12;
BA_ "PacketOrder" SG_ 2151063552 ICSTS_X1TchCrdnt 2;
BA_ "SignalType" SG_ 2151063552 ICSTS_X1TchCrdnt "UNM";
BA_ "SignalLongName" SG_ 2151063552 ICSTS_X1TchCrdnt "Integrated Center Stack Touch Status : X1 Touch Coordinate";
BA_ "VNSigAllNodes" SG_ 2151063552 ICSTS_X1TchCrdnt 1;
BA_ "GenSigSendType" SG_ 2151063552 ICSTS_TchPrxmty 10;
BA_ "PacketOrder" SG_ 2151063552 ICSTS_TchPrxmty 1;
BA_ "SignalType" SG_ 2151063552 ICSTS_TchPrxmty "ENM";
BA_ "SignalLongName" SG_ 2151063552 ICSTS_TchPrxmty "Integrated Center Stack Touch Status : Touch Proximity";
BA_ "VNSigAllNodes" SG_ 2151063552 ICSTS_TchPrxmty 1;
BA_ "GenSigSendType" SG_ 2151063552 TrgdVidRecSwAct 10;
BA_ "SignalType" SG_ 2151063552 TrgdVidRecSwAct "BLN";
BA_ "SignalLongName" SG_ 2151063552 TrgdVidRecSwAct "Triggered Video Recorder Switch Active";
BA_ "VNSigAllNodes" SG_ 2151063552 TrgdVidRecSwAct 1;
BA_ "GenSigSendType" SG_ 2151063552 RrPedDetCstStReq 10;
BA_ "SignalType" SG_ 2151063552 RrPedDetCstStReq "ENM";
BA_ "SignalLongName" SG_ 2151063552 RrPedDetCstStReq "Rear Pedestrian Detection Customization Setting Request";
BA_ "VNSigAllNodes" SG_ 2151063552 RrPedDetCstStReq 1;
BA_ "GenSigSendType" SG_ 2151063552 RRStStatDispAct 10;
BA_ "GenSigSendOnInit" SG_ 2151063552 RRStStatDispAct 2;
BA_ "SignalType" SG_ 2151063552 RRStStatDispAct "BLN";
BA_ "SignalLongName" SG_ 2151063552 RRStStatDispAct "Right Rear Seat Status Display Active";
BA_ "VNSigAllNodes" SG_ 2151063552 RRStStatDispAct 1;
BA_ "GenSigSendType" SG_ 2151063552 LRStStatDispAct 10;
BA_ "GenSigSendOnInit" SG_ 2151063552 LRStStatDispAct 2;
BA_ "SignalType" SG_ 2151063552 LRStStatDispAct "BLN";
BA_ "SignalLongName" SG_ 2151063552 LRStStatDispAct "Left Rear Seat Status Display Active";
BA_ "VNSigAllNodes" SG_ 2151063552 LRStStatDispAct 1;
BA_ "GenSigSendType" SG_ 2151063552 CamVideoICSDispAct 10;
BA_ "SignalType" SG_ 2151063552 CamVideoICSDispAct "BLN";
BA_ "SignalLongName" SG_ 2151063552 CamVideoICSDispAct "Camera Video ICS Display Active";
BA_ "VNSigAllNodes" SG_ 2151063552 CamVideoICSDispAct 1;
BA_ "GenSigSendType" SG_ 2151063552 Frnt360CamSwAct 10;
BA_ "SignalType" SG_ 2151063552 Frnt360CamSwAct "BLN";
BA_ "SignalLongName" SG_ 2151063552 Frnt360CamSwAct "Front 360 Camera Switch Active";
BA_ "VNSigAllNodes" SG_ 2151063552 Frnt360CamSwAct 1;
BA_ "GenSigSendType" SG_ 2151063552 InftnOprAlwd 10;
BA_ "GenSigSendOnInit" SG_ 2151063552 InftnOprAlwd 1;
BA_ "VNSigInfotainment" SG_ 2151063552 InftnOprAlwd 1;
BA_ "SignalType" SG_ 2151063552 InftnOprAlwd "BLN";
BA_ "SignalLongName" SG_ 2151063552 InftnOprAlwd "Infotainment Operation Allowed";
BA_ "VNSigAllNodes" SG_ 2151063552 InftnOprAlwd 1;
BA_ "GenSigSendType" SG_ 2151063552 ValetMdAct 10;
BA_ "VNSigInfotainment" SG_ 2151063552 ValetMdAct 1;
BA_ "SignalType" SG_ 2151063552 ValetMdAct "BLN";
BA_ "SignalLongName" SG_ 2151063552 ValetMdAct "Valet Mode Active";
BA_ "VNSigAllNodes" SG_ 2151063552 ValetMdAct 1;
BA_ "GenSigSendType" SG_ 2157985792 FobProgEvntRqd 10;
BA_ "GenSigSendOnInit" SG_ 2157985792 FobProgEvntRqd 2;
BA_ "SignalType" SG_ 2157985792 FobProgEvntRqd "BLN";
BA_ "SignalLongName" SG_ 2157985792 FobProgEvntRqd "Fob Programming Event Requested";
BA_ "VNSigAllNodes" SG_ 2157985792 FobProgEvntRqd 1;
BA_ "GenSigSendType" SG_ 2151284736 PrkAstOprtrDsrdStat_1D0 10;
BA_ "GenSigSendOnInit" SG_ 2151284736 PrkAstOprtrDsrdStat_1D0 2;
BA_ "SignalType" SG_ 2151284736 PrkAstOprtrDsrdStat_1D0 "ENM";
BA_ "SignalLongName" SG_ 2151284736 PrkAstOprtrDsrdStat_1D0 "Park Assistance Operator Desired Status";
BA_ "VNSigAllNodes" SG_ 2151284736 PrkAstOprtrDsrdStat_1D0 1;
BA_ "GenSigSendType" SG_ 2151284736 TnDrvPrkAstOffUnbIO 10;
BA_ "SignalType" SG_ 2151284736 TnDrvPrkAstOffUnbIO "BLN";
BA_ "SignalLongName" SG_ 2151284736 TnDrvPrkAstOffUnbIO "Teen Driver Park Assist Off Unavailable Indication On";
BA_ "VNSigAllNodes" SG_ 2151284736 TnDrvPrkAstOffUnbIO 1;
BA_ "GenSigSendType" SG_ 2151284736 PrkAstFld 10;
BA_ "SignalType" SG_ 2151284736 PrkAstFld "BLN";
BA_ "SignalLongName" SG_ 2151284736 PrkAstFld "Parking Assistance Failed";
BA_ "VNSigAllNodes" SG_ 2151284736 PrkAstFld 1;
BA_ "GenSigSendType" SG_ 2151284736 PrkAstSnsDistrbdIO 10;
BA_ "SignalType" SG_ 2151284736 PrkAstSnsDistrbdIO "BLN";
BA_ "SignalLongName" SG_ 2151284736 PrkAstSnsDistrbdIO "Parking Assistance Sensors Disturbed Indication On";
BA_ "VNSigAllNodes" SG_ 2151284736 PrkAstSnsDistrbdIO 1;
BA_ "GenSigSendType" SG_ 2151284736 PrkAsstDisablIO 10;
BA_ "GenSigSendOnInit" SG_ 2151284736 PrkAsstDisablIO 2;
BA_ "SignalType" SG_ 2151284736 PrkAsstDisablIO "BLN";
BA_ "SignalLongName" SG_ 2151284736 PrkAsstDisablIO "Parking Assistance Disabled Indication On";
BA_ "VNSigAllNodes" SG_ 2151284736 PrkAsstDisablIO 1;
BA_ "GenSigSendType" SG_ 2151284736 PrkAstSnrsBlk 10;
BA_ "SignalType" SG_ 2151284736 PrkAstSnrsBlk "BLN";
BA_ "SignalLongName" SG_ 2151284736 PrkAstSnrsBlk "Parking Assistance Sensors Blocked";
BA_ "VNSigAllNodes" SG_ 2151284736 PrkAstSnrsBlk 1;
BA_ "GenSigSendType" SG_ 2151284736 PrkAsstClnPrkAstIO 10;
BA_ "SignalType" SG_ 2151284736 PrkAsstClnPrkAstIO "BLN";
BA_ "SignalLongName" SG_ 2151284736 PrkAsstClnPrkAstIO "Parking Assistance Clean Parking Assist Indication On";
BA_ "VNSigAllNodes" SG_ 2151284736 PrkAsstClnPrkAstIO 1;
BA_ "GenSigSendType" SG_ 2151718912 ChmVolSt 10;
BA_ "SignalType" SG_ 2151718912 ChmVolSt "ENM";
BA_ "SignalLongName" SG_ 2151718912 ChmVolSt "Chime Volume Status";
BA_ "VNSigAllNodes" SG_ 2151718912 ChmVolSt 1;
BA_ "GenSigSendType" SG_ 2151718912 ChmAct 10;
BA_ "GenSigSendOnInit" SG_ 2151718912 ChmAct 1;
BA_ "VNSigInfotainment" SG_ 2151718912 ChmAct 1;
BA_ "VNSigIntermediate" SG_ 2151718912 ChmAct 1;
BA_ "SignalType" SG_ 2151718912 ChmAct "BLN";
BA_ "SignalLongName" SG_ 2151718912 ChmAct "Chime Active";
BA_ "VNSigAllNodes" SG_ 2151718912 ChmAct 1;
BA_ "GenSigSendType" SG_ 2155479040 DrvStyPerfMdCsStReq 10;
BA_ "SignalType" SG_ 2155479040 DrvStyPerfMdCsStReq "ENM";
BA_ "SignalLongName" SG_ 2155479040 DrvStyPerfMdCsStReq "Driving Style Performance Mode Customization Setting Request";
BA_ "VNSigAllNodes" SG_ 2155479040 DrvStyPerfMdCsStReq 1;
BA_ "GenSigSendType" SG_ 2155479040 PsngStPerfMdCsStReq 10;
BA_ "SignalType" SG_ 2155479040 PsngStPerfMdCsStReq "ENM";
BA_ "SignalLongName" SG_ 2155479040 PsngStPerfMdCsStReq "Passenger Seat Performance Mode Customization Setting Request";
BA_ "VNSigAllNodes" SG_ 2155479040 PsngStPerfMdCsStReq 1;
BA_ "GenSigSendType" SG_ 2155479040 DrvrStPerfMdCsStReq 10;
BA_ "SignalType" SG_ 2155479040 DrvrStPerfMdCsStReq "ENM";
BA_ "SignalLongName" SG_ 2155479040 DrvrStPerfMdCsStReq "Driver Seat Performance Mode Customization Setting Request";
BA_ "VNSigAllNodes" SG_ 2155479040 DrvrStPerfMdCsStReq 1;
BA_ "GenSigSendType" SG_ 2155479040 ACCPerfMdCsStReq 10;
BA_ "SignalType" SG_ 2155479040 ACCPerfMdCsStReq "ENM";
BA_ "SignalLongName" SG_ 2155479040 ACCPerfMdCsStReq "Adaptive Cruise Control Performance Mode Customization Setting Request";
BA_ "VNSigAllNodes" SG_ 2155479040 ACCPerfMdCsStReq 1;
BA_ "GenSigSendType" SG_ 2155479040 ElvtdIdlCstStReq 10;
BA_ "SignalType" SG_ 2155479040 ElvtdIdlCstStReq "ENM";
BA_ "SignalLongName" SG_ 2155479040 ElvtdIdlCstStReq "Elevated Idle Customization Setting Request";
BA_ "VNSigAllNodes" SG_ 2155479040 ElvtdIdlCstStReq 1;
BA_ "GenSigSendType" SG_ 2155479040 PedFrndlyAlrtCsStReq 10;
BA_ "SignalType" SG_ 2155479040 PedFrndlyAlrtCsStReq "ENM";
BA_ "SignalLongName" SG_ 2155479040 PedFrndlyAlrtCsStReq "Pedestrian Friendly Alert Customization Setting Request";
BA_ "VNSigAllNodes" SG_ 2155479040 PedFrndlyAlrtCsStReq 1;
BA_ "GenSigSendType" SG_ 2155479040 SndPerfMdCsStRq 10;
BA_ "SignalType" SG_ 2155479040 SndPerfMdCsStRq "ENM";
BA_ "SignalLongName" SG_ 2155479040 SndPerfMdCsStRq "Sound Performance Mode Customization Setting Request";
BA_ "VNSigAllNodes" SG_ 2155479040 SndPerfMdCsStRq 1;
BA_ "GenSigSendType" SG_ 2155479040 DispPerfMdCsStRq 10;
BA_ "SignalType" SG_ 2155479040 DispPerfMdCsStRq "ENM";
BA_ "SignalLongName" SG_ 2155479040 DispPerfMdCsStRq "Display Performance Mode Customization Setting Request";
BA_ "VNSigAllNodes" SG_ 2155479040 DispPerfMdCsStRq 1;
BA_ "GenSigSendType" SG_ 2155479040 SusCustStngReq 10;
BA_ "GenSigSendOnInit" SG_ 2155479040 SusCustStngReq 1;
BA_ "SignalType" SG_ 2155479040 SusCustStngReq "ENM";
BA_ "SignalLongName" SG_ 2155479040 SusCustStngReq "Suspension Customization Setting Request";
BA_ "VNSigAllNodes" SG_ 2155479040 SusCustStngReq 1;
BA_ "GenSigSendType" SG_ 2155479040 StrCustStngReq 10;
BA_ "GenSigSendOnInit" SG_ 2155479040 StrCustStngReq 1;
BA_ "SignalType" SG_ 2155479040 StrCustStngReq "ENM";
BA_ "SignalLongName" SG_ 2155479040 StrCustStngReq "Steering Customization Setting Request";
BA_ "VNSigAllNodes" SG_ 2155479040 StrCustStngReq 1;
BA_ "GenSigSendType" SG_ 2155479040 RstrCustFctrDef 10;
BA_ "GenSigSendOnInit" SG_ 2155479040 RstrCustFctrDef 1;
BA_ "VNSigInfotainment" SG_ 2155479040 RstrCustFctrDef 1;
BA_ "SignalType" SG_ 2155479040 RstrCustFctrDef "ENM";
BA_ "SignalLongName" SG_ 2155479040 RstrCustFctrDef "Restore Customization Factory Defaults";
BA_ "VNSigAllNodes" SG_ 2155479040 RstrCustFctrDef 1;
BA_ "GenSigSendType" SG_ 2155479040 DrvlnCustStngReq 10;
BA_ "GenSigSendOnInit" SG_ 2155479040 DrvlnCustStngReq 1;
BA_ "SignalType" SG_ 2155479040 DrvlnCustStngReq "ENM";
BA_ "SignalLongName" SG_ 2155479040 DrvlnCustStngReq "Driveline Customization Setting Request";
BA_ "VNSigAllNodes" SG_ 2155479040 DrvlnCustStngReq 1;
BA_ "GenSigSendType" SG_ 2151383040 TreInfMonSysRstReq 10;
BA_ "SignalType" SG_ 2151383040 TreInfMonSysRstReq "BLN";
BA_ "SignalLongName" SG_ 2151383040 TreInfMonSysRstReq "Tire Inflation Monitoring System Reset Requested";
BA_ "VNSigAllNodes" SG_ 2151383040 TreInfMonSysRstReq 1;
BA_ "SignalType" SG_ 1355 DgnInf_LS54B "UNM";
BA_ "SignalLongName" SG_ 1355 DgnInf_LS54B "Diagnostic Information LS54B";
BA_ "VNSigDiagnostic" SG_ 1355 DgnInf_LS54B 1;
BA_ "VNSigAllNodes" SG_ 1355 DgnInf_LS54B 1;
BA_ "SignalType" SG_ 1611 DgnInf "UNM";
BA_ "SignalLongName" SG_ 1611 DgnInf "Diagnostic Information";
BA_ "VNSigDiagnostic" SG_ 1611 DgnInf 1;
BA_ "VNSigAllNodes" SG_ 1611 DgnInf 1;
BA_ "GenSigSendType" SG_ 2155421696 PsvEntAprchDrctn 10;
BA_ "GenSigSendOnInit" SG_ 2155421696 PsvEntAprchDrctn 2;
BA_ "SignalType" SG_ 2155421696 PsvEntAprchDrctn "ENM";
BA_ "SignalLongName" SG_ 2155421696 PsvEntAprchDrctn "Passive Entry Approach Direction";
BA_ "VNSigAllNodes" SG_ 2155421696 PsvEntAprchDrctn 1;
BA_ "GenSigSendType" SG_ 2155421696 PsvEntApprchDtcd 10;
BA_ "GenSigSendOnInit" SG_ 2155421696 PsvEntApprchDtcd 2;
BA_ "SignalType" SG_ 2155421696 PsvEntApprchDtcd "BLN";
BA_ "SignalLongName" SG_ 2155421696 PsvEntApprchDtcd "Passive Entry Approach Detected";
BA_ "VNSigAllNodes" SG_ 2155421696 PsvEntApprchDtcd 1;
BA_ "GenSigSendType" SG_ 2155421696 PsvEntApprchCnfgReq 10;
BA_ "GenSigSendOnInit" SG_ 2155421696 PsvEntApprchCnfgReq 2;
BA_ "SignalType" SG_ 2155421696 PsvEntApprchCnfgReq "ENM";
BA_ "SignalLongName" SG_ 2155421696 PsvEntApprchCnfgReq "Passive Entry Approach Configuration Request";
BA_ "VNSigAllNodes" SG_ 2155421696 PsvEntApprchCnfgReq 1;
BA_ "GenSigSendType" SG_ 2155421696 ServKylsStSysIO 10;
BA_ "GenSigSendOnInit" SG_ 2155421696 ServKylsStSysIO 2;
BA_ "SignalType" SG_ 2155421696 ServKylsStSysIO "BLN";
BA_ "SignalLongName" SG_ 2155421696 ServKylsStSysIO "Service Keyless Start System Indication On";
BA_ "VNSigAllNodes" SG_ 2155421696 ServKylsStSysIO 1;
BA_ "GenSigDeltaValue" SG_ 2155421696 PsvEntChlng 1;
BA_ "GenSigSendType" SG_ 2155421696 PsvEntChlng 12;
BA_ "GenSigSendOnInit" SG_ 2155421696 PsvEntChlng 2;
BA_ "SignalType" SG_ 2155421696 PsvEntChlng "UNM";
BA_ "SignalLongName" SG_ 2155421696 PsvEntChlng "Passive Entry Challenge";
BA_ "VNSigAllNodes" SG_ 2155421696 PsvEntChlng 1;
BA_ "GenSigSendType" SG_ 2155413504 PsvLckngReqd 10;
BA_ "SignalType" SG_ 2155413504 PsvLckngReqd "BLN";
BA_ "SignalLongName" SG_ 2155413504 PsvLckngReqd "Passive Locking Requested";
BA_ "VNSigAllNodes" SG_ 2155413504 PsvLckngReqd 1;
BA_ "GenSigDeltaValue" SG_ 2155413504 PsvApprchVehId 1;
BA_ "GenSigSendType" SG_ 2155413504 PsvApprchVehId 12;
BA_ "SignalType" SG_ 2155413504 PsvApprchVehId "UNM";
BA_ "SignalLongName" SG_ 2155413504 PsvApprchVehId "Passive Approach Vehicle Identifier";
BA_ "VNSigAllNodes" SG_ 2155413504 PsvApprchVehId 1;
BA_ "GenSigSendType" SG_ 2155413504 DrvrDrKeyCylUlkSwAct 10;
BA_ "SignalType" SG_ 2155413504 DrvrDrKeyCylUlkSwAct "BLN";
BA_ "SignalLongName" SG_ 2155413504 DrvrDrKeyCylUlkSwAct "Driver Door Key Cylinder Unlock Switch Active";
BA_ "VNSigAllNodes" SG_ 2155413504 DrvrDrKeyCylUlkSwAct 1;
BA_ "GenSigSendType" SG_ 2155413504 DrvrDrKeyCylUlkSwActV 10;
BA_ "SignalType" SG_ 2155413504 DrvrDrKeyCylUlkSwActV "ENM";
BA_ "SignalLongName" SG_ 2155413504 DrvrDrKeyCylUlkSwActV "Driver Door Key Cylinder Unlock Switch Active Validity";
BA_ "VNSigAllNodes" SG_ 2155413504 DrvrDrKeyCylUlkSwActV 1;
BA_ "GenSigSendType" SG_ 2159026176 ODD_InvldData 10;
BA_ "VNSigInfotainment" SG_ 2159026176 ODD_InvldData 1;
BA_ "SignalType" SG_ 2159026176 ODD_InvldData "BLN";
BA_ "PacketOrder" SG_ 2159026176 ODD_InvldData 2;
BA_ "SignalLongName" SG_ 2159026176 ODD_InvldData "Open Display Interface Dynamic Data : Invalid Data";
BA_ "VNSigAllNodes" SG_ 2159026176 ODD_InvldData 1;
BA_ "GenSigDeltaValue" SG_ 2159026176 ODD_FUCID 1;
BA_ "GenSigSendType" SG_ 2159026176 ODD_FUCID 12;
BA_ "VNSigInfotainment" SG_ 2159026176 ODD_FUCID 1;
BA_ "SignalType" SG_ 2159026176 ODD_FUCID "UNM";
BA_ "PacketOrder" SG_ 2159026176 ODD_FUCID 3;
BA_ "SignalLongName" SG_ 2159026176 ODD_FUCID "Open Display Interface Dynamic Data : Functional Unit Class ID";
BA_ "VNSigAllNodes" SG_ 2159026176 ODD_FUCID 1;
BA_ "GenSigDeltaValue" SG_ 2159026176 ODD_DataVal 1;
BA_ "GenSigSendType" SG_ 2159026176 ODD_DataVal 12;
BA_ "VNSigInfotainment" SG_ 2159026176 ODD_DataVal 1;
BA_ "SignalType" SG_ 2159026176 ODD_DataVal "UNM";
BA_ "PacketOrder" SG_ 2159026176 ODD_DataVal 5;
BA_ "SignalLongName" SG_ 2159026176 ODD_DataVal "Open Display Interface Dynamic Data : Data Value";
BA_ "VNSigAllNodes" SG_ 2159026176 ODD_DataVal 1;
BA_ "GenSigDeltaValue" SG_ 2159026176 ODD_DataType 1;
BA_ "GenSigSendType" SG_ 2159026176 ODD_DataType 10;
BA_ "VNSigInfotainment" SG_ 2159026176 ODD_DataType 1;
BA_ "SignalType" SG_ 2159026176 ODD_DataType "ENM";
BA_ "PacketOrder" SG_ 2159026176 ODD_DataType 1;
BA_ "SignalLongName" SG_ 2159026176 ODD_DataType "Open Display Interface Dynamic Data : Data Type";
BA_ "VNSigAllNodes" SG_ 2159026176 ODD_DataType 1;
BA_ "GenSigDeltaValue" SG_ 2159026176 ODD_DataId 1;
BA_ "GenSigSendType" SG_ 2159026176 ODD_DataId 12;
BA_ "VNSigInfotainment" SG_ 2159026176 ODD_DataId 1;
BA_ "SignalType" SG_ 2159026176 ODD_DataId "UNM";
BA_ "PacketOrder" SG_ 2159026176 ODD_DataId 4;
BA_ "SignalLongName" SG_ 2159026176 ODD_DataId "Open Display Interface Dynamic Data : Data ID";
BA_ "VNSigAllNodes" SG_ 2159026176 ODD_DataId 1;
BA_ "GenSigDeltaValue" SG_ 2158936064 ODIEDD_Data18Value 1;
BA_ "GenSigSendType" SG_ 2158936064 ODIEDD_Data18Value 12;
BA_ "GenSigSendOnInit" SG_ 2158936064 ODIEDD_Data18Value 1;
BA_ "VNSigInfotainment" SG_ 2158936064 ODIEDD_Data18Value 1;
BA_ "SignalType" SG_ 2158936064 ODIEDD_Data18Value "UNM";
BA_ "PacketOrder" SG_ 2158936064 ODIEDD_Data18Value 18;
BA_ "SignalLongName" SG_ 2158936064 ODIEDD_Data18Value "Open Display Interface Enum Dynamic Data : Data ID 18";
BA_ "VNSigAllNodes" SG_ 2158936064 ODIEDD_Data18Value 1;
BA_ "GenSigDeltaValue" SG_ 2158936064 ODIEDD_Data17Value 1;
BA_ "GenSigSendType" SG_ 2158936064 ODIEDD_Data17Value 12;
BA_ "GenSigSendOnInit" SG_ 2158936064 ODIEDD_Data17Value 1;
BA_ "VNSigInfotainment" SG_ 2158936064 ODIEDD_Data17Value 1;
BA_ "SignalType" SG_ 2158936064 ODIEDD_Data17Value "UNM";
BA_ "PacketOrder" SG_ 2158936064 ODIEDD_Data17Value 17;
BA_ "SignalLongName" SG_ 2158936064 ODIEDD_Data17Value "Open Display Interface Enum Dynamic Data : Data ID 17";
BA_ "VNSigAllNodes" SG_ 2158936064 ODIEDD_Data17Value 1;
BA_ "GenSigDeltaValue" SG_ 2158936064 ODIEDD_Data16Value 1;
BA_ "GenSigSendType" SG_ 2158936064 ODIEDD_Data16Value 12;
BA_ "GenSigSendOnInit" SG_ 2158936064 ODIEDD_Data16Value 1;
BA_ "VNSigInfotainment" SG_ 2158936064 ODIEDD_Data16Value 1;
BA_ "SignalType" SG_ 2158936064 ODIEDD_Data16Value "UNM";
BA_ "PacketOrder" SG_ 2158936064 ODIEDD_Data16Value 16;
BA_ "SignalLongName" SG_ 2158936064 ODIEDD_Data16Value "Open Display Interface Enum Dynamic Data : Data ID 16";
BA_ "VNSigAllNodes" SG_ 2158936064 ODIEDD_Data16Value 1;
BA_ "GenSigDeltaValue" SG_ 2158936064 ODIEDD_Data15Value 1;
BA_ "GenSigSendType" SG_ 2158936064 ODIEDD_Data15Value 12;
BA_ "GenSigSendOnInit" SG_ 2158936064 ODIEDD_Data15Value 1;
BA_ "VNSigInfotainment" SG_ 2158936064 ODIEDD_Data15Value 1;
BA_ "SignalType" SG_ 2158936064 ODIEDD_Data15Value "UNM";
BA_ "PacketOrder" SG_ 2158936064 ODIEDD_Data15Value 15;
BA_ "SignalLongName" SG_ 2158936064 ODIEDD_Data15Value "Open Display Interface Enum Dynamic Data : Data ID 15";
BA_ "VNSigAllNodes" SG_ 2158936064 ODIEDD_Data15Value 1;
BA_ "GenSigDeltaValue" SG_ 2158936064 ODIEDD_Data14Value 1;
BA_ "GenSigSendType" SG_ 2158936064 ODIEDD_Data14Value 12;
BA_ "GenSigSendOnInit" SG_ 2158936064 ODIEDD_Data14Value 1;
BA_ "VNSigInfotainment" SG_ 2158936064 ODIEDD_Data14Value 1;
BA_ "SignalType" SG_ 2158936064 ODIEDD_Data14Value "UNM";
BA_ "PacketOrder" SG_ 2158936064 ODIEDD_Data14Value 14;
BA_ "SignalLongName" SG_ 2158936064 ODIEDD_Data14Value "Open Display Interface Enum Dynamic Data : Data ID 14";
BA_ "VNSigAllNodes" SG_ 2158936064 ODIEDD_Data14Value 1;
BA_ "GenSigDeltaValue" SG_ 2158936064 ODIEDD_Data13Value 1;
BA_ "GenSigSendType" SG_ 2158936064 ODIEDD_Data13Value 12;
BA_ "GenSigSendOnInit" SG_ 2158936064 ODIEDD_Data13Value 1;
BA_ "VNSigInfotainment" SG_ 2158936064 ODIEDD_Data13Value 1;
BA_ "SignalType" SG_ 2158936064 ODIEDD_Data13Value "UNM";
BA_ "PacketOrder" SG_ 2158936064 ODIEDD_Data13Value 13;
BA_ "SignalLongName" SG_ 2158936064 ODIEDD_Data13Value "Open Display Interface Enum Dynamic Data : Data ID 13";
BA_ "VNSigAllNodes" SG_ 2158936064 ODIEDD_Data13Value 1;
BA_ "GenSigDeltaValue" SG_ 2158936064 ODIEDD_Data12Value 1;
BA_ "GenSigSendType" SG_ 2158936064 ODIEDD_Data12Value 12;
BA_ "GenSigSendOnInit" SG_ 2158936064 ODIEDD_Data12Value 1;
BA_ "VNSigInfotainment" SG_ 2158936064 ODIEDD_Data12Value 1;
BA_ "SignalType" SG_ 2158936064 ODIEDD_Data12Value "UNM";
BA_ "PacketOrder" SG_ 2158936064 ODIEDD_Data12Value 12;
BA_ "SignalLongName" SG_ 2158936064 ODIEDD_Data12Value "Open Display Interface Enum Dynamic Data : Data ID 12";
BA_ "VNSigAllNodes" SG_ 2158936064 ODIEDD_Data12Value 1;
BA_ "GenSigDeltaValue" SG_ 2158936064 ODIEDD_Data11Value 1;
BA_ "GenSigSendType" SG_ 2158936064 ODIEDD_Data11Value 12;
BA_ "GenSigSendOnInit" SG_ 2158936064 ODIEDD_Data11Value 1;
BA_ "VNSigInfotainment" SG_ 2158936064 ODIEDD_Data11Value 1;
BA_ "SignalType" SG_ 2158936064 ODIEDD_Data11Value "UNM";
BA_ "PacketOrder" SG_ 2158936064 ODIEDD_Data11Value 11;
BA_ "SignalLongName" SG_ 2158936064 ODIEDD_Data11Value "Open Display Interface Enum Dynamic Data : Data ID 11";
BA_ "VNSigAllNodes" SG_ 2158936064 ODIEDD_Data11Value 1;
BA_ "GenSigDeltaValue" SG_ 2158936064 ODIEDD_Data10Value 1;
BA_ "GenSigSendType" SG_ 2158936064 ODIEDD_Data10Value 12;
BA_ "GenSigSendOnInit" SG_ 2158936064 ODIEDD_Data10Value 1;
BA_ "VNSigInfotainment" SG_ 2158936064 ODIEDD_Data10Value 1;
BA_ "SignalType" SG_ 2158936064 ODIEDD_Data10Value "UNM";
BA_ "PacketOrder" SG_ 2158936064 ODIEDD_Data10Value 10;
BA_ "SignalLongName" SG_ 2158936064 ODIEDD_Data10Value "Open Display Interface Enum Dynamic Data : Data ID 10";
BA_ "VNSigAllNodes" SG_ 2158936064 ODIEDD_Data10Value 1;
BA_ "GenSigDeltaValue" SG_ 2158936064 ODIEDD_Data9Value 1;
BA_ "GenSigSendType" SG_ 2158936064 ODIEDD_Data9Value 12;
BA_ "GenSigSendOnInit" SG_ 2158936064 ODIEDD_Data9Value 1;
BA_ "VNSigInfotainment" SG_ 2158936064 ODIEDD_Data9Value 1;
BA_ "SignalType" SG_ 2158936064 ODIEDD_Data9Value "UNM";
BA_ "PacketOrder" SG_ 2158936064 ODIEDD_Data9Value 9;
BA_ "SignalLongName" SG_ 2158936064 ODIEDD_Data9Value "Open Display Interface Enum Dynamic Data : Data ID 9";
BA_ "VNSigAllNodes" SG_ 2158936064 ODIEDD_Data9Value 1;
BA_ "GenSigDeltaValue" SG_ 2158936064 ODIEDD_Data8Value 1;
BA_ "GenSigSendType" SG_ 2158936064 ODIEDD_Data8Value 12;
BA_ "GenSigSendOnInit" SG_ 2158936064 ODIEDD_Data8Value 1;
BA_ "VNSigInfotainment" SG_ 2158936064 ODIEDD_Data8Value 1;
BA_ "SignalType" SG_ 2158936064 ODIEDD_Data8Value "UNM";
BA_ "PacketOrder" SG_ 2158936064 ODIEDD_Data8Value 8;
BA_ "SignalLongName" SG_ 2158936064 ODIEDD_Data8Value "Open Display Interface Enum Dynamic Data : Data ID 8";
BA_ "VNSigAllNodes" SG_ 2158936064 ODIEDD_Data8Value 1;
BA_ "GenSigDeltaValue" SG_ 2158936064 ODIEDD_Data7Value 1;
BA_ "GenSigSendType" SG_ 2158936064 ODIEDD_Data7Value 12;
BA_ "GenSigSendOnInit" SG_ 2158936064 ODIEDD_Data7Value 1;
BA_ "VNSigInfotainment" SG_ 2158936064 ODIEDD_Data7Value 1;
BA_ "SignalType" SG_ 2158936064 ODIEDD_Data7Value "UNM";
BA_ "PacketOrder" SG_ 2158936064 ODIEDD_Data7Value 7;
BA_ "SignalLongName" SG_ 2158936064 ODIEDD_Data7Value "Open Display Interface Enum Dynamic Data : Data ID 7";
BA_ "VNSigAllNodes" SG_ 2158936064 ODIEDD_Data7Value 1;
BA_ "GenSigDeltaValue" SG_ 2158936064 ODIEDD_Data6Value 1;
BA_ "GenSigSendType" SG_ 2158936064 ODIEDD_Data6Value 12;
BA_ "GenSigSendOnInit" SG_ 2158936064 ODIEDD_Data6Value 1;
BA_ "VNSigInfotainment" SG_ 2158936064 ODIEDD_Data6Value 1;
BA_ "SignalType" SG_ 2158936064 ODIEDD_Data6Value "UNM";
BA_ "PacketOrder" SG_ 2158936064 ODIEDD_Data6Value 6;
BA_ "SignalLongName" SG_ 2158936064 ODIEDD_Data6Value "Open Display Interface Enum Dynamic Data : Data ID 6";
BA_ "VNSigAllNodes" SG_ 2158936064 ODIEDD_Data6Value 1;
BA_ "GenSigDeltaValue" SG_ 2158936064 ODIEDD_Data5Value 1;
BA_ "GenSigSendType" SG_ 2158936064 ODIEDD_Data5Value 12;
BA_ "GenSigSendOnInit" SG_ 2158936064 ODIEDD_Data5Value 1;
BA_ "VNSigInfotainment" SG_ 2158936064 ODIEDD_Data5Value 1;
BA_ "SignalType" SG_ 2158936064 ODIEDD_Data5Value "UNM";
BA_ "PacketOrder" SG_ 2158936064 ODIEDD_Data5Value 5;
BA_ "SignalLongName" SG_ 2158936064 ODIEDD_Data5Value "Open Display Interface Enum Dynamic Data : Data ID 5";
BA_ "VNSigAllNodes" SG_ 2158936064 ODIEDD_Data5Value 1;
BA_ "GenSigDeltaValue" SG_ 2158936064 ODIEDD_Data4Value 1;
BA_ "GenSigSendType" SG_ 2158936064 ODIEDD_Data4Value 12;
BA_ "GenSigSendOnInit" SG_ 2158936064 ODIEDD_Data4Value 1;
BA_ "VNSigInfotainment" SG_ 2158936064 ODIEDD_Data4Value 1;
BA_ "SignalType" SG_ 2158936064 ODIEDD_Data4Value "UNM";
BA_ "PacketOrder" SG_ 2158936064 ODIEDD_Data4Value 4;
BA_ "SignalLongName" SG_ 2158936064 ODIEDD_Data4Value "Open Display Interface Enum Dynamic Data : Data ID 4";
BA_ "VNSigAllNodes" SG_ 2158936064 ODIEDD_Data4Value 1;
BA_ "GenSigDeltaValue" SG_ 2158936064 ODIEDD_Data3Value 1;
BA_ "GenSigSendType" SG_ 2158936064 ODIEDD_Data3Value 12;
BA_ "GenSigSendOnInit" SG_ 2158936064 ODIEDD_Data3Value 1;
BA_ "VNSigInfotainment" SG_ 2158936064 ODIEDD_Data3Value 1;
BA_ "SignalType" SG_ 2158936064 ODIEDD_Data3Value "UNM";
BA_ "PacketOrder" SG_ 2158936064 ODIEDD_Data3Value 3;
BA_ "SignalLongName" SG_ 2158936064 ODIEDD_Data3Value "Open Display Interface Enum Dynamic Data : Data ID 3";
BA_ "VNSigAllNodes" SG_ 2158936064 ODIEDD_Data3Value 1;
BA_ "GenSigDeltaValue" SG_ 2158936064 ODIEDD_Data2Value 1;
BA_ "GenSigSendType" SG_ 2158936064 ODIEDD_Data2Value 12;
BA_ "GenSigSendOnInit" SG_ 2158936064 ODIEDD_Data2Value 1;
BA_ "VNSigInfotainment" SG_ 2158936064 ODIEDD_Data2Value 1;
BA_ "SignalType" SG_ 2158936064 ODIEDD_Data2Value "UNM";
BA_ "PacketOrder" SG_ 2158936064 ODIEDD_Data2Value 2;
BA_ "SignalLongName" SG_ 2158936064 ODIEDD_Data2Value "Open Display Interface Enum Dynamic Data : Data ID 2";
BA_ "VNSigAllNodes" SG_ 2158936064 ODIEDD_Data2Value 1;
BA_ "GenSigDeltaValue" SG_ 2158936064 ODIEDD_Data1Value 1;
BA_ "GenSigSendType" SG_ 2158936064 ODIEDD_Data1Value 12;
BA_ "GenSigSendOnInit" SG_ 2158936064 ODIEDD_Data1Value 1;
BA_ "VNSigInfotainment" SG_ 2158936064 ODIEDD_Data1Value 1;
BA_ "SignalType" SG_ 2158936064 ODIEDD_Data1Value "UNM";
BA_ "PacketOrder" SG_ 2158936064 ODIEDD_Data1Value 1;
BA_ "SignalLongName" SG_ 2158936064 ODIEDD_Data1Value "Open Display Interface Enum Dynamic Data : Data ID 1";
BA_ "VNSigAllNodes" SG_ 2158936064 ODIEDD_Data1Value 1;
BA_ "GenSigDeltaValue" SG_ 2158936064 ODIEDD_FUCID 1;
BA_ "GenSigSendType" SG_ 2158936064 ODIEDD_FUCID 12;
BA_ "GenSigSendOnInit" SG_ 2158936064 ODIEDD_FUCID 1;
BA_ "VNSigInfotainment" SG_ 2158936064 ODIEDD_FUCID 1;
BA_ "SignalType" SG_ 2158936064 ODIEDD_FUCID "UNM";
BA_ "PacketOrder" SG_ 2158936064 ODIEDD_FUCID 19;
BA_ "SignalLongName" SG_ 2158936064 ODIEDD_FUCID "Open Display Interface Enum Dynamic Data : Functional Unit Class ID";
BA_ "VNSigAllNodes" SG_ 2158936064 ODIEDD_FUCID 1;
BA_ "GenSigDeltaValue" SG_ 2158845952 ODIAC_FUCID 1;
BA_ "GenSigSendType" SG_ 2158845952 ODIAC_FUCID 12;
BA_ "VNSigInfotainment" SG_ 2158845952 ODIAC_FUCID 1;
BA_ "SignalType" SG_ 2158845952 ODIAC_FUCID "UNM";
BA_ "PacketOrder" SG_ 2158845952 ODIAC_FUCID 2;
BA_ "SignalLongName" SG_ 2158845952 ODIAC_FUCID "Open Display Interface Action CenterStack : FU Class ID";
BA_ "VNSigAllNodes" SG_ 2158845952 ODIAC_FUCID 1;
BA_ "GenSigSendType" SG_ 2158845952 ODIAC_DspMID 10;
BA_ "VNSigInfotainment" SG_ 2158845952 ODIAC_DspMID 1;
BA_ "SignalType" SG_ 2158845952 ODIAC_DspMID "ENM";
BA_ "PacketOrder" SG_ 2158845952 ODIAC_DspMID 4;
BA_ "SignalLongName" SG_ 2158845952 ODIAC_DspMID "Open Display Interface Action CenterStack : Display Mask ID";
BA_ "VNSigAllNodes" SG_ 2158845952 ODIAC_DspMID 1;
BA_ "GenSigDeltaValue" SG_ 2158845952 ODIAC_DaTy 1;
BA_ "GenSigSendType" SG_ 2158845952 ODIAC_DaTy 10;
BA_ "VNSigInfotainment" SG_ 2158845952 ODIAC_DaTy 1;
BA_ "SignalType" SG_ 2158845952 ODIAC_DaTy "ENM";
BA_ "PacketOrder" SG_ 2158845952 ODIAC_DaTy 1;
BA_ "SignalLongName" SG_ 2158845952 ODIAC_DaTy "Open Display Interface Action CenterStack : DataType";
BA_ "VNSigAllNodes" SG_ 2158845952 ODIAC_DaTy 1;
BA_ "GenSigDeltaValue" SG_ 2158845952 ODIAC_ActnVal 1;
BA_ "GenSigSendType" SG_ 2158845952 ODIAC_ActnVal 12;
BA_ "VNSigInfotainment" SG_ 2158845952 ODIAC_ActnVal 1;
BA_ "SignalType" SG_ 2158845952 ODIAC_ActnVal "UNM";
BA_ "PacketOrder" SG_ 2158845952 ODIAC_ActnVal 5;
BA_ "SignalLongName" SG_ 2158845952 ODIAC_ActnVal "Open Display Interface Action CenterStack : Action Value";
BA_ "VNSigAllNodes" SG_ 2158845952 ODIAC_ActnVal 1;
BA_ "GenSigDeltaValue" SG_ 2158845952 ODIAC_ActnID 1;
BA_ "GenSigSendType" SG_ 2158845952 ODIAC_ActnID 12;
BA_ "VNSigInfotainment" SG_ 2158845952 ODIAC_ActnID 1;
BA_ "SignalType" SG_ 2158845952 ODIAC_ActnID "UNM";
BA_ "PacketOrder" SG_ 2158845952 ODIAC_ActnID 3;
BA_ "SignalLongName" SG_ 2158845952 ODIAC_ActnID "Open Display Interface Action CenterStack : Action ID";
BA_ "VNSigAllNodes" SG_ 2158845952 ODIAC_ActnID 1;
BA_ "VNSigPrimaryTriggering" SG_ 1596 VectraSpcNWMgtD 1;
BA_ "VNSigRemoteDiagnostics" SG_ 1596 VectraSpcNWMgtD 1;
BA_ "VNSigInfotainment" SG_ 1596 VectraSpcNWMgtD 1;
BA_ "VNSigParkedVehicle" SG_ 1596 VectraSpcNWMgtD 1;
BA_ "VNSigIntermediate" SG_ 1596 VectraSpcNWMgtD 1;
BA_ "VNSigUnused_4" SG_ 1596 VectraSpcNWMgtD 1;
BA_ "SignalType" SG_ 1596 VectraSpcNWMgtD "UNM";
BA_ "SignalLongName" SG_ 1596 VectraSpcNWMgtD "Vectra Specific Network Management Data";
BA_ "VNSigDiagnostic" SG_ 1596 VectraSpcNWMgtD 1;
BA_ "VNSigAllNodes" SG_ 1596 VectraSpcNWMgtD 1;
BA_ "GenSigSendType" SG_ 2151366656 PrkBrkSwAtv 10;
BA_ "GenSigSendOnInit" SG_ 2151366656 PrkBrkSwAtv 1;
BA_ "SignalType" SG_ 2151366656 PrkBrkSwAtv "BLN";
BA_ "SignalLongName" SG_ 2151366656 PrkBrkSwAtv "Park Brake Switch Active";
BA_ "VNSigAllNodes" SG_ 2151366656 PrkBrkSwAtv 1;
BA_ "SignalType" SG_ 2149842944 IMUProtLonAccV "ENM";
BA_ "SignalLongName" SG_ 2149842944 IMUProtLonAccV "Inertial Measurement Unit Protected Longitudinal Acceleration Validity";
BA_ "VNSigAllNodes" SG_ 2149842944 IMUProtLonAccV 1;
BA_ "SignalType" SG_ 2149842944 IMUProtLonAcc "SNM";
BA_ "SignalLongName" SG_ 2149842944 IMUProtLonAcc "Inertial Measurement Unit Protected Longitudinal Acceleration";
BA_ "VNSigAllNodes" SG_ 2149842944 IMUProtLonAcc 1;
BA_ "SignalType" SG_ 2149842944 VSELatAccV "ENM";
BA_ "SignalLongName" SG_ 2149842944 VSELatAccV "Vehicle Stability Enhancement Lateral Acceleration Validity";
BA_ "VNSigAllNodes" SG_ 2149842944 VSELatAccV 1;
BA_ "SignalType" SG_ 2149842944 VSELatAcc "SNM";
BA_ "SignalLongName" SG_ 2149842944 VSELatAcc "Vehicle Stability Enhancement Lateral Acceleration";
BA_ "VNSigAllNodes" SG_ 2149842944 VSELatAcc 1;
BA_ "SignalType" SG_ 2149842944 StrWhAngV "ENM";
BA_ "SignalLongName" SG_ 2149842944 StrWhAngV "Steering Wheel Angle Validity";
BA_ "VNSigAllNodes" SG_ 2149842944 StrWhAngV 1;
BA_ "SignalType" SG_ 2149842944 TCSysAtv "BLN";
BA_ "SignalLongName" SG_ 2149842944 TCSysAtv "Traction Control System Active";
BA_ "VNSigAllNodes" SG_ 2149842944 TCSysAtv 1;
BA_ "SignalType" SG_ 2149842944 BrkSysAutBrkFld "BLN";
BA_ "SignalLongName" SG_ 2149842944 BrkSysAutBrkFld "Brake System Automatic Braking Failed";
BA_ "VNSigAllNodes" SG_ 2149842944 BrkSysAutBrkFld 1;
BA_ "SignalType" SG_ 2149842944 StrWhlAngSenCalStat "ENM";
BA_ "SignalLongName" SG_ 2149842944 StrWhlAngSenCalStat "Steering Wheel Angle Sensor Calibration Status";
BA_ "VNSigAllNodes" SG_ 2149842944 StrWhlAngSenCalStat 1;
BA_ "SignalType" SG_ 2149842944 VehStabEnhmntStat "ENM";
BA_ "SignalLongName" SG_ 2149842944 VehStabEnhmntStat "Vehicle Stability Enhancement Status";
BA_ "VNSigAllNodes" SG_ 2149842944 VehStabEnhmntStat 1;
BA_ "SignalType" SG_ 2149842944 VehStabEnhmntMd "ENM";
BA_ "SignalLongName" SG_ 2149842944 VehStabEnhmntMd "Vehicle Stability Enhancement Mode";
BA_ "VNSigAllNodes" SG_ 2149842944 VehStabEnhmntMd 1;
BA_ "SignalType" SG_ 2149842944 VSEAct "BLN";
BA_ "SignalLongName" SG_ 2149842944 VSEAct "Vehicle Stability Enhancement System Active";
BA_ "VNSigAllNodes" SG_ 2149842944 VSEAct 1;
BA_ "SignalType" SG_ 2149842944 TCSysOpStat "ENM";
BA_ "SignalLongName" SG_ 2149842944 TCSysOpStat "Traction Control System Operating Status";
BA_ "VNSigAllNodes" SG_ 2149842944 TCSysOpStat 1;
BA_ "SignalType" SG_ 2149842944 TCSysOpMd "ENM";
BA_ "SignalLongName" SG_ 2149842944 TCSysOpMd "Traction Control System Operating Mode";
BA_ "VNSigAllNodes" SG_ 2149842944 TCSysOpMd 1;
BA_ "SignalType" SG_ 2149842944 StWhAnVDA "ENM";
BA_ "SignalLongName" SG_ 2149842944 StWhAnVDA "Steering Wheel Angle Virtual Device Availability";
BA_ "GenSigStartValue" SG_ 2149842944 StWhAnVDA 1;
BA_ "VNSigAllNodes" SG_ 2149842944 StWhAnVDA 1;
BA_ "SignalType" SG_ 2149842944 StrWhAng "SNM";
BA_ "SignalLongName" SG_ 2149842944 StrWhAng "Steering Wheel Angle";
BA_ "VNSigAllNodes" SG_ 2149842944 StrWhAng 1;
BA_ "GenSigSendType" SG_ 2151940096 EstIntHorzDshSrfTmpM 10;
BA_ "SignalType" SG_ 2151940096 EstIntHorzDshSrfTmpM "ENM";
BA_ "SignalLongName" SG_ 2151940096 EstIntHorzDshSrfTmpM "Estimated Interior Horizontal Dash Surface Temperature Mask";
BA_ "VNSigAllNodes" SG_ 2151940096 EstIntHorzDshSrfTmpM 1;
BA_ "GenSigDeltaValue" SG_ 2151940096 EstIntHorzDshSrfTmp 1;
BA_ "GenSigSendType" SG_ 2151940096 EstIntHorzDshSrfTmp 12;
BA_ "SignalType" SG_ 2151940096 EstIntHorzDshSrfTmp "UNM";
BA_ "SignalLongName" SG_ 2151940096 EstIntHorzDshSrfTmp "Estimated Interior Horizontal Dash Surface Temperature";
BA_ "VNSigAllNodes" SG_ 2151940096 EstIntHorzDshSrfTmp 1;
BA_ "GenSigSendType" SG_ 2151940096 EstIntRfSrfcTmpV 10;
BA_ "SignalType" SG_ 2151940096 EstIntRfSrfcTmpV "ENM";
BA_ "SignalLongName" SG_ 2151940096 EstIntRfSrfcTmpV "Estimated Interior Roof Surface Temperature Validity";
BA_ "VNSigAllNodes" SG_ 2151940096 EstIntRfSrfcTmpV 1;
BA_ "GenSigDeltaValue" SG_ 2151940096 EstIntRfSrfcTmp 1;
BA_ "GenSigSendType" SG_ 2151940096 EstIntRfSrfcTmp 12;
BA_ "SignalType" SG_ 2151940096 EstIntRfSrfcTmp "UNM";
BA_ "SignalLongName" SG_ 2151940096 EstIntRfSrfcTmp "Estimated Interior Roof Surface Temperature";
BA_ "VNSigAllNodes" SG_ 2151940096 EstIntRfSrfcTmp 1;
BA_ "GenSigSendType" SG_ 2151940096 EstBulkIntAirTmpV 10;
BA_ "SignalType" SG_ 2151940096 EstBulkIntAirTmpV "ENM";
BA_ "SignalLongName" SG_ 2151940096 EstBulkIntAirTmpV "Estimated Bulk Interior Air Temperature Validity";
BA_ "VNSigAllNodes" SG_ 2151940096 EstBulkIntAirTmpV 1;
BA_ "GenSigDeltaValue" SG_ 2151940096 EstBulkIntAirTmp 1;
BA_ "GenSigSendType" SG_ 2151940096 EstBulkIntAirTmp 12;
BA_ "SignalType" SG_ 2151940096 EstBulkIntAirTmp "UNM";
BA_ "SignalLongName" SG_ 2151940096 EstBulkIntAirTmp "Estimated Bulk Interior Air Temperature";
BA_ "VNSigAllNodes" SG_ 2151940096 EstBulkIntAirTmp 1;
BA_ "VNSigInfotainment" SG_ 2151940096 HLOCCstCurrSetVal 1;
BA_ "SignalType" SG_ 2151940096 HLOCCstCurrSetVal "ENM";
BA_ "SignalLongName" SG_ 2151940096 HLOCCstCurrSetVal "Handfree Liftgate Open Close Customization Current Setting Value";
BA_ "GenSigDeltaValue" SG_ 2151940096 A2ERRAlrmTime 1;
BA_ "GenSigSendType" SG_ 2151940096 A2ERRAlrmTime 12;
BA_ "VNSigIntermediate" SG_ 2151940096 A2ERRAlrmTime 1;
BA_ "SignalType" SG_ 2151940096 A2ERRAlrmTime "UNM";
BA_ "PacketOrder" SG_ 2151940096 A2ERRAlrmTime 2;
BA_ "SignalLongName" SG_ 2151940096 A2ERRAlrmTime "Alarm 2 Extended Range Request : Alarm Time";
BA_ "VNSigAllNodes" SG_ 2151940096 A2ERRAlrmTime 1;
BA_ "GenSigSendType" SG_ 2151940096 A2ERRAlrmReq 10;
BA_ "VNSigIntermediate" SG_ 2151940096 A2ERRAlrmReq 1;
BA_ "SignalType" SG_ 2151940096 A2ERRAlrmReq "ENM";
BA_ "PacketOrder" SG_ 2151940096 A2ERRAlrmReq 1;
BA_ "SignalLongName" SG_ 2151940096 A2ERRAlrmReq "Alarm 2 Extended Range Request : Alarm Request";
BA_ "VNSigAllNodes" SG_ 2151940096 A2ERRAlrmReq 1;
BA_ "GenSigSendType" SG_ 2150645760 EnvIdRspSt1 10;
BA_ "SignalType" SG_ 2150645760 EnvIdRspSt1 "ENM";
BA_ "SignalLongName" SG_ 2150645760 EnvIdRspSt1 "Environment Identification Response Status 1";
BA_ "VNSigAllNodes" SG_ 2150645760 EnvIdRspSt1 1;
BA_ "GenSigDeltaValue" SG_ 2150645760 EnvIdRsp1 1;
BA_ "GenSigSendType" SG_ 2150645760 EnvIdRsp1 12;
BA_ "SignalType" SG_ 2150645760 EnvIdRsp1 "UNM";
BA_ "SignalLongName" SG_ 2150645760 EnvIdRsp1 "Environment Identification Response 1";
BA_ "VNSigAllNodes" SG_ 2150645760 EnvIdRsp1 1;
BA_ "GenSigSendType" SG_ 2152464384 RtLnDepWrnSt 10;
BA_ "SignalType" SG_ 2152464384 RtLnDepWrnSt "ENM";
BA_ "SignalLongName" SG_ 2152464384 RtLnDepWrnSt "Right Lane Departure Warning Status";
BA_ "VNSigAllNodes" SG_ 2152464384 RtLnDepWrnSt 1;
BA_ "GenSigSendType" SG_ 2152464384 LftLnDepWrnSt 10;
BA_ "SignalType" SG_ 2152464384 LftLnDepWrnSt "ENM";
BA_ "SignalLongName" SG_ 2152464384 LftLnDepWrnSt "Left Lane Departure Warning Status";
BA_ "VNSigAllNodes" SG_ 2152464384 LftLnDepWrnSt 1;
BA_ "GenSigSendType" SG_ 2152464384 TnDrvLDWOffUnbIO 10;
BA_ "SignalType" SG_ 2152464384 TnDrvLDWOffUnbIO "BLN";
BA_ "SignalLongName" SG_ 2152464384 TnDrvLDWOffUnbIO "Teen Driver Lane Departure Warning Off Unavailable Indication On";
BA_ "VNSigAllNodes" SG_ 2152464384 TnDrvLDWOffUnbIO 1;
BA_ "GenSigSendType" SG_ 2152464384 SrvcLnKpAstSysIO 10;
BA_ "SignalType" SG_ 2152464384 SrvcLnKpAstSysIO "BLN";
BA_ "SignalLongName" SG_ 2152464384 SrvcLnKpAstSysIO "Service Lane Keeping Assist System Indication On";
BA_ "VNSigAllNodes" SG_ 2152464384 SrvcLnKpAstSysIO 1;
BA_ "GenSigSendType" SG_ 2152464384 HndsOffStrWhlDtIO 10;
BA_ "SignalType" SG_ 2152464384 HndsOffStrWhlDtIO "BLN";
BA_ "SignalLongName" SG_ 2152464384 HndsOffStrWhlDtIO "Hands Off Steering Wheel Detection Indication On";
BA_ "VNSigAllNodes" SG_ 2152464384 HndsOffStrWhlDtIO 1;
BA_ "GenSigSendType" SG_ 2152464384 LnKpAstDisbldIO 10;
BA_ "SignalType" SG_ 2152464384 LnKpAstDisbldIO "BLN";
BA_ "SignalLongName" SG_ 2152464384 LnKpAstDisbldIO "Lane Keeping Assist Disabled Indication On";
BA_ "VNSigAllNodes" SG_ 2152464384 LnKpAstDisbldIO 1;
BA_ "GenSigSendType" SG_ 2152464384 LKAIC_AdbWngLn 10;
BA_ "SignalType" SG_ 2152464384 LKAIC_AdbWngLn "ENM";
BA_ "PacketOrder" SG_ 2152464384 LKAIC_AdbWngLn 4;
BA_ "SignalLongName" SG_ 2152464384 LKAIC_AdbWngLn "Lane Keeping Assist Indication Control : Audible Warning Location";
BA_ "VNSigAllNodes" SG_ 2152464384 LKAIC_AdbWngLn 1;
BA_ "GenSigSendType" SG_ 2152464384 LKAIC_Ind2 10;
BA_ "SignalType" SG_ 2152464384 LKAIC_Ind2 "BLN";
BA_ "PacketOrder" SG_ 2152464384 LKAIC_Ind2 3;
BA_ "SignalLongName" SG_ 2152464384 LKAIC_Ind2 "Lane Keeping Assist Indication Control : Indicator 2";
BA_ "VNSigAllNodes" SG_ 2152464384 LKAIC_Ind2 1;
BA_ "GenSigSendType" SG_ 2152464384 LKAIC_Ind1 10;
BA_ "SignalType" SG_ 2152464384 LKAIC_Ind1 "BLN";
BA_ "PacketOrder" SG_ 2152464384 LKAIC_Ind1 2;
BA_ "SignalLongName" SG_ 2152464384 LKAIC_Ind1 "Lane Keeping Assist Indication Control : Indicator 1";
BA_ "VNSigAllNodes" SG_ 2152464384 LKAIC_Ind1 1;
BA_ "GenSigSendType" SG_ 2152464384 LKAIC_IndReq 10;
BA_ "SignalType" SG_ 2152464384 LKAIC_IndReq "ENM";
BA_ "PacketOrder" SG_ 2152464384 LKAIC_IndReq 1;
BA_ "SignalLongName" SG_ 2152464384 LKAIC_IndReq "Lane Keeping Assist Indication Control : Indication Request";
BA_ "VNSigAllNodes" SG_ 2152464384 LKAIC_IndReq 1;
BA_ "GenSigSendType" SG_ 2152464384 SrvcLaneDepWrnSysIO 10;
BA_ "SignalType" SG_ 2152464384 SrvcLaneDepWrnSysIO "BLN";
BA_ "SignalLongName" SG_ 2152464384 SrvcLaneDepWrnSysIO "Service Lane Departure Warning System Indication On";
BA_ "VNSigAllNodes" SG_ 2152464384 SrvcLaneDepWrnSysIO 1;
BA_ "GenSigSendType" SG_ 2152464384 LDWIC_LnDepWAWLn 10;
BA_ "GenSigSendOnInit" SG_ 2152464384 LDWIC_LnDepWAWLn 2;
BA_ "SignalType" SG_ 2152464384 LDWIC_LnDepWAWLn "ENM";
BA_ "PacketOrder" SG_ 2152464384 LDWIC_LnDepWAWLn 4;
BA_ "SignalLongName" SG_ 2152464384 LDWIC_LnDepWAWLn "Lane Departure Warning Indication Control : Lane Deparature Warning Audible Warning Location";
BA_ "VNSigAllNodes" SG_ 2152464384 LDWIC_LnDepWAWLn 1;
BA_ "GenSigSendType" SG_ 2152464384 LDWIC_Ind2 10;
BA_ "GenSigSendOnInit" SG_ 2152464384 LDWIC_Ind2 2;
BA_ "SignalType" SG_ 2152464384 LDWIC_Ind2 "BLN";
BA_ "PacketOrder" SG_ 2152464384 LDWIC_Ind2 3;
BA_ "SignalLongName" SG_ 2152464384 LDWIC_Ind2 "Lane Departure Warning Indication Control : Indicator 2";
BA_ "VNSigAllNodes" SG_ 2152464384 LDWIC_Ind2 1;
BA_ "GenSigSendType" SG_ 2152464384 LDWIC_Ind1 10;
BA_ "GenSigSendOnInit" SG_ 2152464384 LDWIC_Ind1 2;
BA_ "SignalType" SG_ 2152464384 LDWIC_Ind1 "BLN";
BA_ "PacketOrder" SG_ 2152464384 LDWIC_Ind1 2;
BA_ "SignalLongName" SG_ 2152464384 LDWIC_Ind1 "Lane Departure Warning Indication Control : Indicator 1";
BA_ "VNSigAllNodes" SG_ 2152464384 LDWIC_Ind1 1;
BA_ "GenSigSendType" SG_ 2152464384 LDWIC_IndReq 10;
BA_ "GenSigSendOnInit" SG_ 2152464384 LDWIC_IndReq 2;
BA_ "SignalType" SG_ 2152464384 LDWIC_IndReq "ENM";
BA_ "PacketOrder" SG_ 2152464384 LDWIC_IndReq 1;
BA_ "SignalLongName" SG_ 2152464384 LDWIC_IndReq "Lane Departure Warning Indication Control : Indication Request";
BA_ "VNSigAllNodes" SG_ 2152464384 LDWIC_IndReq 1;
BA_ "GenSigSendType" SG_ 2152464384 LaneDepWrnDisbldIO 10;
BA_ "SignalType" SG_ 2152464384 LaneDepWrnDisbldIO "BLN";
BA_ "SignalLongName" SG_ 2152464384 LaneDepWrnDisbldIO "Lane Departure Warning Disabled Indication On";
BA_ "VNSigAllNodes" SG_ 2152464384 LaneDepWrnDisbldIO 1;
BA_ "GenSigSendType" SG_ 2154971136 PassHCSeatSw3Act 10;
BA_ "GenSigSendOnInit" SG_ 2154971136 PassHCSeatSw3Act 2;
BA_ "SignalType" SG_ 2154971136 PassHCSeatSw3Act "BLN";
BA_ "SignalLongName" SG_ 2154971136 PassHCSeatSw3Act "Passenger Heated/Cooled Seat Switch #3 Active";
BA_ "VNSigAllNodes" SG_ 2154971136 PassHCSeatSw3Act 1;
BA_ "GenSigSendType" SG_ 2154971136 PassHCSeatSw2Act 10;
BA_ "GenSigSendOnInit" SG_ 2154971136 PassHCSeatSw2Act 2;
BA_ "SignalType" SG_ 2154971136 PassHCSeatSw2Act "BLN";
BA_ "SignalLongName" SG_ 2154971136 PassHCSeatSw2Act "Passenger Heated/Cooled Seat Switch #2 Active";
BA_ "VNSigAllNodes" SG_ 2154971136 PassHCSeatSw2Act 1;
BA_ "GenSigSendType" SG_ 2154971136 PassHCSeatSw1Act 10;
BA_ "GenSigSendOnInit" SG_ 2154971136 PassHCSeatSw1Act 2;
BA_ "SignalType" SG_ 2154971136 PassHCSeatSw1Act "BLN";
BA_ "SignalLongName" SG_ 2154971136 PassHCSeatSw1Act "Passenger Heated/Cooled Seat Switch #1 Active";
BA_ "VNSigAllNodes" SG_ 2154971136 PassHCSeatSw1Act 1;
BA_ "GenSigSendType" SG_ 2154971136 DrvHCSeatSw3Act 10;
BA_ "GenSigSendOnInit" SG_ 2154971136 DrvHCSeatSw3Act 2;
BA_ "SignalType" SG_ 2154971136 DrvHCSeatSw3Act "BLN";
BA_ "SignalLongName" SG_ 2154971136 DrvHCSeatSw3Act "Driver Heated/Cooled Seat Switch #3 Active";
BA_ "VNSigAllNodes" SG_ 2154971136 DrvHCSeatSw3Act 1;
BA_ "GenSigSendType" SG_ 2154971136 DrvHCSeatSw2Act 10;
BA_ "GenSigSendOnInit" SG_ 2154971136 DrvHCSeatSw2Act 2;
BA_ "SignalType" SG_ 2154971136 DrvHCSeatSw2Act "BLN";
BA_ "SignalLongName" SG_ 2154971136 DrvHCSeatSw2Act "Driver Heated/Cooled Seat Switch #2 Active";
BA_ "VNSigAllNodes" SG_ 2154971136 DrvHCSeatSw2Act 1;
BA_ "GenSigSendType" SG_ 2154971136 DrvHCSeatSw1Act 10;
BA_ "GenSigSendOnInit" SG_ 2154971136 DrvHCSeatSw1Act 2;
BA_ "SignalType" SG_ 2154971136 DrvHCSeatSw1Act "BLN";
BA_ "SignalLongName" SG_ 2154971136 DrvHCSeatSw1Act "Driver Heated/Cooled Seat Switch #1 Active";
BA_ "VNSigAllNodes" SG_ 2154971136 DrvHCSeatSw1Act 1;
BA_ "GenSigSendType" SG_ 2154962944 PassHCSMInd3 10;
BA_ "GenSigSendOnInit" SG_ 2154962944 PassHCSMInd3 1;
BA_ "SignalType" SG_ 2154962944 PassHCSMInd3 "BLN";
BA_ "PacketOrder" SG_ 2154962944 PassHCSMInd3 4;
BA_ "SignalLongName" SG_ 2154962944 PassHCSMInd3 "Passenger Heated/Cooled Seat Mode Indication Control : Seat Mode Indication 3";
BA_ "VNSigAllNodes" SG_ 2154962944 PassHCSMInd3 1;
BA_ "GenSigSendType" SG_ 2154962944 PassHCSMInd2 10;
BA_ "GenSigSendOnInit" SG_ 2154962944 PassHCSMInd2 1;
BA_ "SignalType" SG_ 2154962944 PassHCSMInd2 "BLN";
BA_ "PacketOrder" SG_ 2154962944 PassHCSMInd2 3;
BA_ "SignalLongName" SG_ 2154962944 PassHCSMInd2 "Passenger Heated/Cooled Seat Mode Indication Control : Seat Mode Indication 2";
BA_ "VNSigAllNodes" SG_ 2154962944 PassHCSMInd2 1;
BA_ "GenSigSendType" SG_ 2154962944 PassHCSMInd1 10;
BA_ "GenSigSendOnInit" SG_ 2154962944 PassHCSMInd1 1;
BA_ "SignalType" SG_ 2154962944 PassHCSMInd1 "BLN";
BA_ "PacketOrder" SG_ 2154962944 PassHCSMInd1 2;
BA_ "SignalLongName" SG_ 2154962944 PassHCSMInd1 "Passenger Heated/Cooled Seat Mode Indication Control : Seat Mode Indication 1";
BA_ "VNSigAllNodes" SG_ 2154962944 PassHCSMInd1 1;
BA_ "GenSigSendType" SG_ 2154962944 PassHCSMIndReq 10;
BA_ "GenSigSendOnInit" SG_ 2154962944 PassHCSMIndReq 1;
BA_ "SignalType" SG_ 2154962944 PassHCSMIndReq "ENM";
BA_ "PacketOrder" SG_ 2154962944 PassHCSMIndReq 1;
BA_ "SignalLongName" SG_ 2154962944 PassHCSMIndReq "Passenger Heated/Cooled Seat Mode Indication Control : Indication Request";
BA_ "VNSigAllNodes" SG_ 2154962944 PassHCSMIndReq 1;
BA_ "GenSigSendType" SG_ 2154962944 PassHCSLSeatLev5 10;
BA_ "GenSigSendOnInit" SG_ 2154962944 PassHCSLSeatLev5 1;
BA_ "SignalType" SG_ 2154962944 PassHCSLSeatLev5 "BLN";
BA_ "PacketOrder" SG_ 2154962944 PassHCSLSeatLev5 6;
BA_ "SignalLongName" SG_ 2154962944 PassHCSLSeatLev5 "Passenger Heated/Cooled Seat Level Indication Control : Seat Level 5";
BA_ "VNSigAllNodes" SG_ 2154962944 PassHCSLSeatLev5 1;
BA_ "GenSigSendType" SG_ 2154962944 PassHCSLSeatLev4 10;
BA_ "GenSigSendOnInit" SG_ 2154962944 PassHCSLSeatLev4 1;
BA_ "SignalType" SG_ 2154962944 PassHCSLSeatLev4 "BLN";
BA_ "PacketOrder" SG_ 2154962944 PassHCSLSeatLev4 5;
BA_ "SignalLongName" SG_ 2154962944 PassHCSLSeatLev4 "Passenger Heated/Cooled Seat Level Indication Control : Seat Level 4";
BA_ "VNSigAllNodes" SG_ 2154962944 PassHCSLSeatLev4 1;
BA_ "GenSigSendType" SG_ 2154962944 PassHCSLSeatLev3 10;
BA_ "GenSigSendOnInit" SG_ 2154962944 PassHCSLSeatLev3 1;
BA_ "SignalType" SG_ 2154962944 PassHCSLSeatLev3 "BLN";
BA_ "PacketOrder" SG_ 2154962944 PassHCSLSeatLev3 4;
BA_ "SignalLongName" SG_ 2154962944 PassHCSLSeatLev3 "Passenger Heated/Cooled Seat Level Indication Control : Seat Level 3";
BA_ "VNSigAllNodes" SG_ 2154962944 PassHCSLSeatLev3 1;
BA_ "GenSigSendType" SG_ 2154962944 PassHCSLSeatLev2 10;
BA_ "GenSigSendOnInit" SG_ 2154962944 PassHCSLSeatLev2 1;
BA_ "SignalType" SG_ 2154962944 PassHCSLSeatLev2 "BLN";
BA_ "PacketOrder" SG_ 2154962944 PassHCSLSeatLev2 3;
BA_ "SignalLongName" SG_ 2154962944 PassHCSLSeatLev2 "Passenger Heated/Cooled Seat Level Indication Control : Seat Level 2";
BA_ "VNSigAllNodes" SG_ 2154962944 PassHCSLSeatLev2 1;
BA_ "GenSigSendType" SG_ 2154962944 PassHCSLSeatLev1 10;
BA_ "GenSigSendOnInit" SG_ 2154962944 PassHCSLSeatLev1 1;
BA_ "SignalType" SG_ 2154962944 PassHCSLSeatLev1 "BLN";
BA_ "PacketOrder" SG_ 2154962944 PassHCSLSeatLev1 2;
BA_ "SignalLongName" SG_ 2154962944 PassHCSLSeatLev1 "Passenger Heated/Cooled Seat Level Indication Control : Seat Level 1";
BA_ "VNSigAllNodes" SG_ 2154962944 PassHCSLSeatLev1 1;
BA_ "GenSigSendType" SG_ 2154962944 PassHCSLIndReq 10;
BA_ "GenSigSendOnInit" SG_ 2154962944 PassHCSLIndReq 1;
BA_ "SignalType" SG_ 2154962944 PassHCSLIndReq "ENM";
BA_ "PacketOrder" SG_ 2154962944 PassHCSLIndReq 1;
BA_ "SignalLongName" SG_ 2154962944 PassHCSLIndReq "Passenger Heated/Cooled Seat Level Indication Control : Indication Request";
BA_ "VNSigAllNodes" SG_ 2154962944 PassHCSLIndReq 1;
BA_ "GenSigSendType" SG_ 2154962944 DrvHCSMInd1 10;
BA_ "GenSigSendOnInit" SG_ 2154962944 DrvHCSMInd1 1;
BA_ "SignalType" SG_ 2154962944 DrvHCSMInd1 "BLN";
BA_ "PacketOrder" SG_ 2154962944 DrvHCSMInd1 2;
BA_ "SignalLongName" SG_ 2154962944 DrvHCSMInd1 "Driver Heated/Cooled Seat Mode Indication Control : Seat Mode Indication 1";
BA_ "VNSigAllNodes" SG_ 2154962944 DrvHCSMInd1 1;
BA_ "GenSigSendType" SG_ 2154962944 DrvHCSMIndReq 10;
BA_ "GenSigSendOnInit" SG_ 2154962944 DrvHCSMIndReq 1;
BA_ "SignalType" SG_ 2154962944 DrvHCSMIndReq "ENM";
BA_ "PacketOrder" SG_ 2154962944 DrvHCSMIndReq 1;
BA_ "SignalLongName" SG_ 2154962944 DrvHCSMIndReq "Driver Heated/Cooled Seat Mode Indication Control : Indication Request";
BA_ "VNSigAllNodes" SG_ 2154962944 DrvHCSMIndReq 1;
BA_ "GenSigSendType" SG_ 2154962944 DrvHCSMInd3 10;
BA_ "GenSigSendOnInit" SG_ 2154962944 DrvHCSMInd3 1;
BA_ "SignalType" SG_ 2154962944 DrvHCSMInd3 "BLN";
BA_ "PacketOrder" SG_ 2154962944 DrvHCSMInd3 4;
BA_ "SignalLongName" SG_ 2154962944 DrvHCSMInd3 "Driver Heated/Cooled Seat Mode Indication Control : Seat Mode Indication 3";
BA_ "VNSigAllNodes" SG_ 2154962944 DrvHCSMInd3 1;
BA_ "GenSigSendType" SG_ 2154962944 DrvHCSMInd2 10;
BA_ "GenSigSendOnInit" SG_ 2154962944 DrvHCSMInd2 1;
BA_ "SignalType" SG_ 2154962944 DrvHCSMInd2 "BLN";
BA_ "PacketOrder" SG_ 2154962944 DrvHCSMInd2 3;
BA_ "SignalLongName" SG_ 2154962944 DrvHCSMInd2 "Driver Heated/Cooled Seat Mode Indication Control : Seat Mode Indication 2";
BA_ "VNSigAllNodes" SG_ 2154962944 DrvHCSMInd2 1;
BA_ "GenSigSendType" SG_ 2154962944 DrvHCSLSeatLev5 10;
BA_ "GenSigSendOnInit" SG_ 2154962944 DrvHCSLSeatLev5 1;
BA_ "SignalType" SG_ 2154962944 DrvHCSLSeatLev5 "BLN";
BA_ "PacketOrder" SG_ 2154962944 DrvHCSLSeatLev5 6;
BA_ "SignalLongName" SG_ 2154962944 DrvHCSLSeatLev5 "Driver Heated/Cooled Seat Level Indication Control : Seat Level 5";
BA_ "VNSigAllNodes" SG_ 2154962944 DrvHCSLSeatLev5 1;
BA_ "GenSigSendType" SG_ 2154962944 DrvHCSLSeatLev4 10;
BA_ "GenSigSendOnInit" SG_ 2154962944 DrvHCSLSeatLev4 1;
BA_ "SignalType" SG_ 2154962944 DrvHCSLSeatLev4 "BLN";
BA_ "PacketOrder" SG_ 2154962944 DrvHCSLSeatLev4 5;
BA_ "SignalLongName" SG_ 2154962944 DrvHCSLSeatLev4 "Driver Heated/Cooled Seat Level Indication Control : Seat Level 4";
BA_ "VNSigAllNodes" SG_ 2154962944 DrvHCSLSeatLev4 1;
BA_ "GenSigSendType" SG_ 2154962944 DrvHCSLSeatLev3 10;
BA_ "GenSigSendOnInit" SG_ 2154962944 DrvHCSLSeatLev3 1;
BA_ "SignalType" SG_ 2154962944 DrvHCSLSeatLev3 "BLN";
BA_ "PacketOrder" SG_ 2154962944 DrvHCSLSeatLev3 4;
BA_ "SignalLongName" SG_ 2154962944 DrvHCSLSeatLev3 "Driver Heated/Cooled Seat Level Indication Control : Seat Level 3";
BA_ "VNSigAllNodes" SG_ 2154962944 DrvHCSLSeatLev3 1;
BA_ "GenSigSendType" SG_ 2154962944 DrvHCSLSeatLev2 10;
BA_ "GenSigSendOnInit" SG_ 2154962944 DrvHCSLSeatLev2 1;
BA_ "SignalType" SG_ 2154962944 DrvHCSLSeatLev2 "BLN";
BA_ "PacketOrder" SG_ 2154962944 DrvHCSLSeatLev2 3;
BA_ "SignalLongName" SG_ 2154962944 DrvHCSLSeatLev2 "Driver Heated/Cooled Seat Level Indication Control : Seat Level 2";
BA_ "VNSigAllNodes" SG_ 2154962944 DrvHCSLSeatLev2 1;
BA_ "GenSigSendType" SG_ 2154962944 DrvHCSLSeatLev1 10;
BA_ "GenSigSendOnInit" SG_ 2154962944 DrvHCSLSeatLev1 1;
BA_ "SignalType" SG_ 2154962944 DrvHCSLSeatLev1 "BLN";
BA_ "PacketOrder" SG_ 2154962944 DrvHCSLSeatLev1 2;
BA_ "SignalLongName" SG_ 2154962944 DrvHCSLSeatLev1 "Driver Heated/Cooled Seat Level Indication Control : Seat Level 1";
BA_ "VNSigAllNodes" SG_ 2154962944 DrvHCSLSeatLev1 1;
BA_ "GenSigSendType" SG_ 2154962944 DrvHCSLIndReq 10;
BA_ "GenSigSendOnInit" SG_ 2154962944 DrvHCSLIndReq 1;
BA_ "SignalType" SG_ 2154962944 DrvHCSLIndReq "ENM";
BA_ "PacketOrder" SG_ 2154962944 DrvHCSLIndReq 1;
BA_ "SignalLongName" SG_ 2154962944 DrvHCSLIndReq "Driver Heated/Cooled Seat Level Indication Control : Indication Request";
BA_ "VNSigAllNodes" SG_ 2154962944 DrvHCSLIndReq 1;
BA_ "GenSigSendType" SG_ 2156232704 ACSAlarm9 10;
BA_ "SignalType" SG_ 2156232704 ACSAlarm9 "ENM";
BA_ "PacketOrder" SG_ 2156232704 ACSAlarm9 10;
BA_ "SignalLongName" SG_ 2156232704 ACSAlarm9 "Alarm Clock Status : Alarm 9";
BA_ "VNSigAllNodes" SG_ 2156232704 ACSAlarm9 1;
BA_ "GenSigSendType" SG_ 2156232704 ACSAlarm8 10;
BA_ "SignalType" SG_ 2156232704 ACSAlarm8 "ENM";
BA_ "PacketOrder" SG_ 2156232704 ACSAlarm8 9;
BA_ "SignalLongName" SG_ 2156232704 ACSAlarm8 "Alarm Clock Status : Alarm 8";
BA_ "VNSigAllNodes" SG_ 2156232704 ACSAlarm8 1;
BA_ "GenSigSendType" SG_ 2156232704 ACSAlarm7 10;
BA_ "SignalType" SG_ 2156232704 ACSAlarm7 "ENM";
BA_ "PacketOrder" SG_ 2156232704 ACSAlarm7 8;
BA_ "SignalLongName" SG_ 2156232704 ACSAlarm7 "Alarm Clock Status : Alarm 7";
BA_ "VNSigAllNodes" SG_ 2156232704 ACSAlarm7 1;
BA_ "GenSigSendType" SG_ 2156232704 ACSAlarm6 10;
BA_ "SignalType" SG_ 2156232704 ACSAlarm6 "ENM";
BA_ "PacketOrder" SG_ 2156232704 ACSAlarm6 7;
BA_ "SignalLongName" SG_ 2156232704 ACSAlarm6 "Alarm Clock Status : Alarm 6";
BA_ "VNSigAllNodes" SG_ 2156232704 ACSAlarm6 1;
BA_ "GenSigSendType" SG_ 2156232704 ACSAlarm5 10;
BA_ "SignalType" SG_ 2156232704 ACSAlarm5 "ENM";
BA_ "PacketOrder" SG_ 2156232704 ACSAlarm5 6;
BA_ "SignalLongName" SG_ 2156232704 ACSAlarm5 "Alarm Clock Status : Alarm 5";
BA_ "VNSigAllNodes" SG_ 2156232704 ACSAlarm5 1;
BA_ "GenSigSendType" SG_ 2156232704 ACSAlarm4 10;
BA_ "SignalType" SG_ 2156232704 ACSAlarm4 "ENM";
BA_ "PacketOrder" SG_ 2156232704 ACSAlarm4 5;
BA_ "SignalLongName" SG_ 2156232704 ACSAlarm4 "Alarm Clock Status : Alarm 4";
BA_ "VNSigAllNodes" SG_ 2156232704 ACSAlarm4 1;
BA_ "GenSigSendType" SG_ 2156232704 ACSAlarm3 10;
BA_ "SignalType" SG_ 2156232704 ACSAlarm3 "ENM";
BA_ "PacketOrder" SG_ 2156232704 ACSAlarm3 4;
BA_ "SignalLongName" SG_ 2156232704 ACSAlarm3 "Alarm Clock Status : Alarm 3";
BA_ "VNSigAllNodes" SG_ 2156232704 ACSAlarm3 1;
BA_ "GenSigSendType" SG_ 2156232704 ACSAlarm2 10;
BA_ "SignalType" SG_ 2156232704 ACSAlarm2 "ENM";
BA_ "PacketOrder" SG_ 2156232704 ACSAlarm2 3;
BA_ "SignalLongName" SG_ 2156232704 ACSAlarm2 "Alarm Clock Status : Alarm 2";
BA_ "VNSigAllNodes" SG_ 2156232704 ACSAlarm2 1;
BA_ "GenSigSendType" SG_ 2156232704 ACSAlarm15 10;
BA_ "SignalType" SG_ 2156232704 ACSAlarm15 "ENM";
BA_ "PacketOrder" SG_ 2156232704 ACSAlarm15 16;
BA_ "SignalLongName" SG_ 2156232704 ACSAlarm15 "Alarm Clock Status : Alarm 15";
BA_ "VNSigAllNodes" SG_ 2156232704 ACSAlarm15 1;
BA_ "GenSigSendType" SG_ 2156232704 ACSAlarm14 10;
BA_ "SignalType" SG_ 2156232704 ACSAlarm14 "ENM";
BA_ "PacketOrder" SG_ 2156232704 ACSAlarm14 15;
BA_ "SignalLongName" SG_ 2156232704 ACSAlarm14 "Alarm Clock Status : Alarm 14";
BA_ "VNSigAllNodes" SG_ 2156232704 ACSAlarm14 1;
BA_ "GenSigSendType" SG_ 2156232704 ACSAlarm13 10;
BA_ "SignalType" SG_ 2156232704 ACSAlarm13 "ENM";
BA_ "PacketOrder" SG_ 2156232704 ACSAlarm13 14;
BA_ "SignalLongName" SG_ 2156232704 ACSAlarm13 "Alarm Clock Status : Alarm 13";
BA_ "VNSigAllNodes" SG_ 2156232704 ACSAlarm13 1;
BA_ "GenSigSendType" SG_ 2156232704 ACSAlarm12 10;
BA_ "SignalType" SG_ 2156232704 ACSAlarm12 "ENM";
BA_ "PacketOrder" SG_ 2156232704 ACSAlarm12 13;
BA_ "SignalLongName" SG_ 2156232704 ACSAlarm12 "Alarm Clock Status : Alarm 12";
BA_ "VNSigAllNodes" SG_ 2156232704 ACSAlarm12 1;
BA_ "GenSigSendType" SG_ 2156232704 ACSAlarm11 10;
BA_ "SignalType" SG_ 2156232704 ACSAlarm11 "ENM";
BA_ "PacketOrder" SG_ 2156232704 ACSAlarm11 12;
BA_ "SignalLongName" SG_ 2156232704 ACSAlarm11 "Alarm Clock Status : Alarm 11";
BA_ "VNSigAllNodes" SG_ 2156232704 ACSAlarm11 1;
BA_ "GenSigSendType" SG_ 2156232704 ACSAlarm10 10;
BA_ "SignalType" SG_ 2156232704 ACSAlarm10 "ENM";
BA_ "PacketOrder" SG_ 2156232704 ACSAlarm10 11;
BA_ "SignalLongName" SG_ 2156232704 ACSAlarm10 "Alarm Clock Status : Alarm 10";
BA_ "VNSigAllNodes" SG_ 2156232704 ACSAlarm10 1;
BA_ "GenSigSendType" SG_ 2156232704 ACSAlarm1 10;
BA_ "SignalType" SG_ 2156232704 ACSAlarm1 "ENM";
BA_ "PacketOrder" SG_ 2156232704 ACSAlarm1 2;
BA_ "SignalLongName" SG_ 2156232704 ACSAlarm1 "Alarm Clock Status : Alarm 1";
BA_ "VNSigAllNodes" SG_ 2156232704 ACSAlarm1 1;
BA_ "GenSigSendType" SG_ 2156232704 ACSAlarm0 10;
BA_ "SignalType" SG_ 2156232704 ACSAlarm0 "ENM";
BA_ "PacketOrder" SG_ 2156232704 ACSAlarm0 1;
BA_ "SignalLongName" SG_ 2156232704 ACSAlarm0 "Alarm Clock Status : Alarm 0";
BA_ "VNSigAllNodes" SG_ 2156232704 ACSAlarm0 1;
BA_ "GenSigSendType" SG_ 2154987520 WrlsChrgSysChrgStat 10;
BA_ "GenSigSendOnInit" SG_ 2154987520 WrlsChrgSysChrgStat 2;
BA_ "SignalType" SG_ 2154987520 WrlsChrgSysChrgStat "ENM";
BA_ "SignalLongName" SG_ 2154987520 WrlsChrgSysChrgStat "Wireless Charging System Charging Status";
BA_ "VNSigAllNodes" SG_ 2154987520 WrlsChrgSysChrgStat 1;
BA_ "GenSigSendType" SG_ 2154987520 HdStV 10;
BA_ "SignalType" SG_ 2154987520 HdStV "ENM";
BA_ "SignalLongName" SG_ 2154987520 HdStV "Hood Status Validity";
BA_ "VNSigAllNodes" SG_ 2154987520 HdStV 1;
BA_ "GenSigSendType" SG_ 2154987520 HdSt 10;
BA_ "GenSigSendOnInit" SG_ 2154987520 HdSt 2;
BA_ "SignalType" SG_ 2154987520 HdSt "ENM";
BA_ "SignalLongName" SG_ 2154987520 HdSt "Hood Status";
BA_ "VNSigAllNodes" SG_ 2154987520 HdSt 1;
BA_ "GenSigSendType" SG_ 2154840064 CmpsZnNvrSet 10;
BA_ "GenSigSendOnInit" SG_ 2154840064 CmpsZnNvrSet 1;
BA_ "SignalType" SG_ 2154840064 CmpsZnNvrSet "BLN";
BA_ "SignalLongName" SG_ 2154840064 CmpsZnNvrSet "Compass Zone Never Set";
BA_ "VNSigAllNodes" SG_ 2154840064 CmpsZnNvrSet 1;
BA_ "GenSigSendType" SG_ 2154840064 CmpsSatrtd 10;
BA_ "GenSigSendOnInit" SG_ 2154840064 CmpsSatrtd 1;
BA_ "SignalType" SG_ 2154840064 CmpsSatrtd "BLN";
BA_ "SignalLongName" SG_ 2154840064 CmpsSatrtd "Compass Saturated";
BA_ "VNSigAllNodes" SG_ 2154840064 CmpsSatrtd 1;
BA_ "GenSigSendType" SG_ 2154840064 CmpsDecZone 10;
BA_ "GenSigSendOnInit" SG_ 2154840064 CmpsDecZone 1;
BA_ "SignalType" SG_ 2154840064 CmpsDecZone "ENM";
BA_ "SignalLongName" SG_ 2154840064 CmpsDecZone "Compass Declination Zone";
BA_ "VNSigAllNodes" SG_ 2154840064 CmpsDecZone 1;
BA_ "GenSigSendType" SG_ 2154840064 CmpsOctHdingDataSrc 10;
BA_ "GenSigSendOnInit" SG_ 2154840064 CmpsOctHdingDataSrc 1;
BA_ "SignalType" SG_ 2154840064 CmpsOctHdingDataSrc "ENM";
BA_ "SignalLongName" SG_ 2154840064 CmpsOctHdingDataSrc "Compass Octant Heading Data Source";
BA_ "VNSigAllNodes" SG_ 2154840064 CmpsOctHdingDataSrc 1;
BA_ "GenSigSendType" SG_ 2154840064 CmpsOctHding 10;
BA_ "GenSigSendOnInit" SG_ 2154840064 CmpsOctHding 1;
BA_ "SignalType" SG_ 2154840064 CmpsOctHding "ENM";
BA_ "SignalLongName" SG_ 2154840064 CmpsOctHding "Compass Octant Heading";
BA_ "VNSigAllNodes" SG_ 2154840064 CmpsOctHding 1;
BA_ "GenSigSendType" SG_ 2154840064 CmpsModManCalInPrc 10;
BA_ "GenSigSendOnInit" SG_ 2154840064 CmpsModManCalInPrc 1;
BA_ "SignalType" SG_ 2154840064 CmpsModManCalInPrc "BLN";
BA_ "SignalLongName" SG_ 2154840064 CmpsModManCalInPrc "Compass Module Manual Calibration In Process";
BA_ "VNSigAllNodes" SG_ 2154840064 CmpsModManCalInPrc 1;
BA_ "GenSigSendType" SG_ 2154840064 CmpsModFltPrs 10;
BA_ "GenSigSendOnInit" SG_ 2154840064 CmpsModFltPrs 1;
BA_ "SignalType" SG_ 2154840064 CmpsModFltPrs "BLN";
BA_ "SignalLongName" SG_ 2154840064 CmpsModFltPrs "Compass Module Fault Present";
BA_ "VNSigAllNodes" SG_ 2154840064 CmpsModFltPrs 1;
BA_ "GenSigDeltaValue" SG_ 2154840064 CmpsCrHding 1;
BA_ "GenSigSendType" SG_ 2154840064 CmpsCrHding 12;
BA_ "GenSigSendOnInit" SG_ 2154840064 CmpsCrHding 1;
BA_ "SignalType" SG_ 2154840064 CmpsCrHding "UNM";
BA_ "SignalLongName" SG_ 2154840064 CmpsCrHding "Compass Corrected Heading";
BA_ "VNSigAllNodes" SG_ 2154840064 CmpsCrHding 1;
BA_ "GenSigSendType" SG_ 2154676224 CmpsModSlfTstReq 10;
BA_ "SignalType" SG_ 2154676224 CmpsModSlfTstReq "ENM";
BA_ "SignalLongName" SG_ 2154676224 CmpsModSlfTstReq "Compass Module Self Test Request";
BA_ "VNSigAllNodes" SG_ 2154676224 CmpsModSlfTstReq 1;
BA_ "GenSigSendType" SG_ 2154676224 CmpsModManCalReq 10;
BA_ "SignalType" SG_ 2154676224 CmpsModManCalReq "ENM";
BA_ "SignalLongName" SG_ 2154676224 CmpsModManCalReq "Compass Module Manual Calibration Request";
BA_ "VNSigAllNodes" SG_ 2154676224 CmpsModManCalReq 1;
BA_ "GenSigSendType" SG_ 2154676224 CmpsDecZonSetReq 10;
BA_ "SignalType" SG_ 2154676224 CmpsDecZonSetReq "ENM";
BA_ "SignalLongName" SG_ 2154676224 CmpsDecZonSetReq "Compass Declination Zone Set Request";
BA_ "VNSigAllNodes" SG_ 2154676224 CmpsDecZonSetReq 1;
BA_ "GenSigSendType" SG_ 2154676224 CmpsDecZonCmndVal 10;
BA_ "SignalType" SG_ 2154676224 CmpsDecZonCmndVal "ENM";
BA_ "SignalLongName" SG_ 2154676224 CmpsDecZonCmndVal "Compass Declination Zone Commanded Value";
BA_ "VNSigAllNodes" SG_ 2154676224 CmpsDecZonCmndVal 1;
BA_ "GenSigSendType" SG_ 2154643456 HtrCoreInltClntTmpCalcV 10;
BA_ "SignalType" SG_ 2154643456 HtrCoreInltClntTmpCalcV "ENM";
BA_ "SignalLongName" SG_ 2154643456 HtrCoreInltClntTmpCalcV "Heater Core Inlet Coolant Temperature Calculated Validity";
BA_ "VNSigAllNodes" SG_ 2154643456 HtrCoreInltClntTmpCalcV 1;
BA_ "GenSigDeltaValue" SG_ 2154643456 HtrCoreInltClntTmpCalc 1;
BA_ "GenSigSendType" SG_ 2154643456 HtrCoreInltClntTmpCalc 12;
BA_ "SignalType" SG_ 2154643456 HtrCoreInltClntTmpCalc "UNM";
BA_ "SignalLongName" SG_ 2154643456 HtrCoreInltClntTmpCalc "Heater Core Inlet Coolant Temperature Calculated";
BA_ "VNSigAllNodes" SG_ 2154643456 HtrCoreInltClntTmpCalc 1;
BA_ "GenSigSendType" SG_ 2154643456 AuxHtrAtv 10;
BA_ "SignalType" SG_ 2154643456 AuxHtrAtv "BLN";
BA_ "SignalLongName" SG_ 2154643456 AuxHtrAtv "Auxiliary Heater Active";
BA_ "VNSigAllNodes" SG_ 2154643456 AuxHtrAtv 1;
BA_ "GenSigDeltaValue" SG_ 2154643456 CCClntCrcFlwRtReq 1;
BA_ "GenSigSendType" SG_ 2154643456 CCClntCrcFlwRtReq 12;
BA_ "GenSigSendOnInit" SG_ 2154643456 CCClntCrcFlwRtReq 2;
BA_ "SignalType" SG_ 2154643456 CCClntCrcFlwRtReq "UNM";
BA_ "SignalLongName" SG_ 2154643456 CCClntCrcFlwRtReq "Climate Control Coolant Circulation Flow Rate Request";
BA_ "VNSigAllNodes" SG_ 2154643456 CCClntCrcFlwRtReq 1;
BA_ "GenSigSendType" SG_ 2154905600 DrvSeatPrsMemID 10;
BA_ "SignalType" SG_ 2154905600 DrvSeatPrsMemID "ENM";
BA_ "SignalLongName" SG_ 2154905600 DrvSeatPrsMemID "Driver Seat Personalization Memory ID";
BA_ "GenSigStartValue" SG_ 2154905600 DrvSeatPrsMemID 7;
BA_ "VNSigAllNodes" SG_ 2154905600 DrvSeatPrsMemID 1;
BA_ "GenSigSendType" SG_ 2154905600 DrId 10;
BA_ "GenSigSendOnInit" SG_ 2154905600 DrId 1;
BA_ "VNSigInfotainment" SG_ 2154905600 DrId 1;
BA_ "SignalType" SG_ 2154905600 DrId "ENM";
BA_ "SignalLongName" SG_ 2154905600 DrId "Driver Identifier";
BA_ "GenSigStartValue" SG_ 2154905600 DrId 7;
BA_ "VNSigAllNodes" SG_ 2154905600 DrId 1;
BA_ "GenSigSendType" SG_ 2154954752 HtdStWhlCmd 10;
BA_ "SignalType" SG_ 2154954752 HtdStWhlCmd "ENM";
BA_ "SignalLongName" SG_ 2154954752 HtdStWhlCmd "Heated Steering Wheel Command";
BA_ "VNSigAllNodes" SG_ 2154954752 HtdStWhlCmd 1;
BA_ "GenSigSendType" SG_ 2154954752 HtdStWhlCtrlSrc 10;
BA_ "SignalType" SG_ 2154954752 HtdStWhlCtrlSrc "ENM";
BA_ "SignalLongName" SG_ 2154954752 HtdStWhlCtrlSrc "Heated Steering Wheel Control Source";
BA_ "VNSigAllNodes" SG_ 2154954752 HtdStWhlCtrlSrc 1;
BA_ "GenSigSendType" SG_ 2154954752 HtdStWhlInd 10;
BA_ "SignalType" SG_ 2154954752 HtdStWhlInd "ENM";
BA_ "SignalLongName" SG_ 2154954752 HtdStWhlInd "Heated Steering Wheel Indication";
BA_ "VNSigAllNodes" SG_ 2154954752 HtdStWhlInd 1;
BA_ "GenSigSendType" SG_ 2154954752 ClmtHtPwrRqd 10;
BA_ "SignalType" SG_ 2154954752 ClmtHtPwrRqd "BLN";
BA_ "SignalLongName" SG_ 2154954752 ClmtHtPwrRqd "Climate Heating Power Required";
BA_ "VNSigAllNodes" SG_ 2154954752 ClmtHtPwrRqd 1;
BA_ "GenSigDeltaValue" SG_ 2154954752 EstACCompPwrRchCbnCmf 1;
BA_ "GenSigSendType" SG_ 2154954752 EstACCompPwrRchCbnCmf 12;
BA_ "SignalType" SG_ 2154954752 EstACCompPwrRchCbnCmf "UNM";
BA_ "SignalLongName" SG_ 2154954752 EstACCompPwrRchCbnCmf "Estimated Air Conditioning Control Power to Reach Cabin Comfort";
BA_ "VNSigAllNodes" SG_ 2154954752 EstACCompPwrRchCbnCmf 1;
BA_ "GenSigDeltaValue" SG_ 2154954752 ClntHtrElecPwrReq 1;
BA_ "GenSigSendType" SG_ 2154954752 ClntHtrElecPwrReq 12;
BA_ "SignalType" SG_ 2154954752 ClntHtrElecPwrReq "UNM";
BA_ "SignalLongName" SG_ 2154954752 ClntHtrElecPwrReq "Coolant Heater Electrical Power Request";
BA_ "VNSigAllNodes" SG_ 2154954752 ClntHtrElecPwrReq 1;
BA_ "GenSigDeltaValue" SG_ 2154954752 EstACCompPwrMtnCbnCmf 1;
BA_ "GenSigSendType" SG_ 2154954752 EstACCompPwrMtnCbnCmf 12;
BA_ "SignalType" SG_ 2154954752 EstACCompPwrMtnCbnCmf "UNM";
BA_ "SignalLongName" SG_ 2154954752 EstACCompPwrMtnCbnCmf "Estimated Air Conditioning Control Power to Maintain Cabin Comfort";
BA_ "VNSigAllNodes" SG_ 2154954752 EstACCompPwrMtnCbnCmf 1;
BA_ "SignalType" SG_ 2149752832 HlStrAssActIO "BLN";
BA_ "SignalLongName" SG_ 2149752832 HlStrAssActIO "Hill Start Assist Active Indication On";
BA_ "VNSigAllNodes" SG_ 2149752832 HlStrAssActIO 1;
BA_ "SignalType" SG_ 2149752832 GNCustSetngAvlbl "BLN";
BA_ "SignalLongName" SG_ 2149752832 GNCustSetngAvlbl "Go Notifier Customization Setting Available";
BA_ "VNSigAllNodes" SG_ 2149752832 GNCustSetngAvlbl 1;
BA_ "SignalType" SG_ 2149752832 GNCustCrntStngVal "ENM";
BA_ "SignalLongName" SG_ 2149752832 GNCustCrntStngVal "Go Notifier Customization Current Setting Value";
BA_ "VNSigAllNodes" SG_ 2149752832 GNCustCrntStngVal 1;
BA_ "SignalType" SG_ 2149752832 ColPrSysStngAvl "BLN";
BA_ "SignalLongName" SG_ 2149752832 ColPrSysStngAvl "Collision Preparation System Setting Available";
BA_ "VNSigAllNodes" SG_ 2149752832 ColPrSysStngAvl 1;
BA_ "SignalType" SG_ 2149752832 ColPrSysCrntStng "ENM";
BA_ "SignalLongName" SG_ 2149752832 ColPrSysCrntStng "Collision Preparation System Current Setting Value";
BA_ "VNSigAllNodes" SG_ 2149752832 ColPrSysCrntStng 1;
BA_ "SignalType" SG_ 2149752832 ElecPrkBrkStat "ENM";
BA_ "SignalLongName" SG_ 2149752832 ElecPrkBrkStat "Electric Park Brake Status";
BA_ "VNSigAllNodes" SG_ 2149752832 ElecPrkBrkStat 1;
BA_ "SignalType" SG_ 2149752832 EBDFailed "BLN";
BA_ "SignalLongName" SG_ 2149752832 EBDFailed "Electronic Brake Distribution Failed";
BA_ "VNSigAllNodes" SG_ 2149752832 EBDFailed 1;
BA_ "SignalType" SG_ 2149752832 ABSAtv "BLN";
BA_ "SignalLongName" SG_ 2149752832 ABSAtv "Antilock Brake System Active";
BA_ "VNSigAllNodes" SG_ 2149752832 ABSAtv 1;
BA_ "SignalType" SG_ 2149752832 PowStVDA "ENM";
BA_ "SignalLongName" SG_ 2149752832 PowStVDA "Power Steering Virtual Device Availability";
BA_ "GenSigStartValue" SG_ 2149752832 PowStVDA 1;
BA_ "VNSigAllNodes" SG_ 2149752832 PowStVDA 1;
BA_ "SignalType" SG_ 2149752832 RrDrCntVDA "ENM";
BA_ "SignalLongName" SG_ 2149752832 RrDrCntVDA "Rear Drive Control Virtual Device Availability";
BA_ "GenSigStartValue" SG_ 2149752832 RrDrCntVDA 1;
BA_ "VNSigAllNodes" SG_ 2149752832 RrDrCntVDA 1;
BA_ "SignalType" SG_ 2149752832 SprTireSt "ENM";
BA_ "SignalLongName" SG_ 2149752832 SprTireSt "Spare Tire Status";
BA_ "VNSigAllNodes" SG_ 2149752832 SprTireSt 1;
BA_ "SignalType" SG_ 2149752832 BrkSysVDA "ENM";
BA_ "SignalLongName" SG_ 2149752832 BrkSysVDA "Brake System Virtual Device Availability";
BA_ "GenSigStartValue" SG_ 2149752832 BrkSysVDA 1;
BA_ "VNSigAllNodes" SG_ 2149752832 BrkSysVDA 1;
BA_ "SignalType" SG_ 2149752832 IntBrkAssPreFilReq "BLN";
BA_ "SignalLongName" SG_ 2149752832 IntBrkAssPreFilReq "Inteligent Brake Assist Pre-Fil Request";
BA_ "VNSigAllNodes" SG_ 2149752832 IntBrkAssPreFilReq 1;
BA_ "SignalType" SG_ 2149752832 EPBSysDspMsgReq "ENM";
BA_ "SignalLongName" SG_ 2149752832 EPBSysDspMsgReq "Electric Park Brake System Display Message Request";
BA_ "VNSigAllNodes" SG_ 2149752832 EPBSysDspMsgReq 1;
BA_ "SignalType" SG_ 2149752832 EPBSysAudWarnReq "ENM";
BA_ "SignalLongName" SG_ 2149752832 EPBSysAudWarnReq "Electric Park Brake System Audible Warning Request";
BA_ "VNSigAllNodes" SG_ 2149752832 EPBSysAudWarnReq 1;
BA_ "SignalType" SG_ 2149752832 BksOvht "BLN";
BA_ "SignalLongName" SG_ 2149752832 BksOvht "Brakes Overheated";
BA_ "VNSigAllNodes" SG_ 2149752832 BksOvht 1;
BA_ "SignalType" SG_ 2149752832 BrkSysRedBrkTlltlReq "BLN";
BA_ "SignalLongName" SG_ 2149752832 BrkSysRedBrkTlltlReq "Brake System Red Brake Telltale Request";
BA_ "VNSigAllNodes" SG_ 2149752832 BrkSysRedBrkTlltlReq 1;
BA_ "SignalType" SG_ 2149752832 HalfSysFail "BLN";
BA_ "SignalLongName" SG_ 2149752832 HalfSysFail "Half System Failure";
BA_ "VNSigAllNodes" SG_ 2149752832 HalfSysFail 1;
BA_ "SignalType" SG_ 2149752832 PrkBrkVDA "ENM";
BA_ "SignalLongName" SG_ 2149752832 PrkBrkVDA "Park Brake Virtual Device Availability";
BA_ "GenSigStartValue" SG_ 2149752832 PrkBrkVDA 1;
BA_ "VNSigAllNodes" SG_ 2149752832 PrkBrkVDA 1;
BA_ "GenSigSendType" SG_ 2151514112 EngOilLfRstRq 10;
BA_ "SignalType" SG_ 2151514112 EngOilLfRstRq "BLN";
BA_ "SignalLongName" SG_ 2151514112 EngOilLfRstRq "Engine Oil Life Reset Request";
BA_ "VNSigAllNodes" SG_ 2151514112 EngOilLfRstRq 1;
BA_ "GenSigSendType" SG_ 2158911488 ODDMC_ReqType 10;
BA_ "VNSigInfotainment" SG_ 2158911488 ODDMC_ReqType 1;
BA_ "SignalType" SG_ 2158911488 ODDMC_ReqType "ENM";
BA_ "PacketOrder" SG_ 2158911488 ODDMC_ReqType 1;
BA_ "SignalLongName" SG_ 2158911488 ODDMC_ReqType "Open Display Interface Dynamic Data Multi Request CenterStack : Request Type";
BA_ "VNSigAllNodes" SG_ 2158911488 ODDMC_ReqType 1;
BA_ "GenSigSendType" SG_ 2158911488 ODDMC_DispMID 10;
BA_ "VNSigInfotainment" SG_ 2158911488 ODDMC_DispMID 1;
BA_ "SignalType" SG_ 2158911488 ODDMC_DispMID "ENM";
BA_ "PacketOrder" SG_ 2158911488 ODDMC_DispMID 7;
BA_ "SignalLongName" SG_ 2158911488 ODDMC_DispMID "Open Display Interface Dynamic Data Multi Request CenterStack : Display Mask Id";
BA_ "VNSigAllNodes" SG_ 2158911488 ODDMC_DispMID 1;
BA_ "GenSigSendType" SG_ 2158911488 ODDMC_DataID2Vld 10;
BA_ "VNSigInfotainment" SG_ 2158911488 ODDMC_DataID2Vld 1;
BA_ "SignalType" SG_ 2158911488 ODDMC_DataID2Vld "BLN";
BA_ "PacketOrder" SG_ 2158911488 ODDMC_DataID2Vld 5;
BA_ "SignalLongName" SG_ 2158911488 ODDMC_DataID2Vld "Open Display Interface Dynamic Data Multi Request CenterStack : Data ID Two Valid";
BA_ "VNSigAllNodes" SG_ 2158911488 ODDMC_DataID2Vld 1;
BA_ "GenSigDeltaValue" SG_ 2158911488 ODDMC_DataID2 1;
BA_ "GenSigSendType" SG_ 2158911488 ODDMC_DataID2 12;
BA_ "VNSigInfotainment" SG_ 2158911488 ODDMC_DataID2 1;
BA_ "SignalType" SG_ 2158911488 ODDMC_DataID2 "UNM";
BA_ "PacketOrder" SG_ 2158911488 ODDMC_DataID2 9;
BA_ "SignalLongName" SG_ 2158911488 ODDMC_DataID2 "Open Display Interface Dynamic Data Multi Request CenterStack : Data ID Two";
BA_ "VNSigAllNodes" SG_ 2158911488 ODDMC_DataID2 1;
BA_ "GenSigSendType" SG_ 2158911488 ODDMC_DataID3Vld 10;
BA_ "VNSigInfotainment" SG_ 2158911488 ODDMC_DataID3Vld 1;
BA_ "SignalType" SG_ 2158911488 ODDMC_DataID3Vld "BLN";
BA_ "PacketOrder" SG_ 2158911488 ODDMC_DataID3Vld 4;
BA_ "SignalLongName" SG_ 2158911488 ODDMC_DataID3Vld "Open Display Interface Dynamic Data Multi Request CenterStack : Data ID Three Valid";
BA_ "VNSigAllNodes" SG_ 2158911488 ODDMC_DataID3Vld 1;
BA_ "GenSigDeltaValue" SG_ 2158911488 ODDMC_DataID3 1;
BA_ "GenSigSendType" SG_ 2158911488 ODDMC_DataID3 12;
BA_ "VNSigInfotainment" SG_ 2158911488 ODDMC_DataID3 1;
BA_ "SignalType" SG_ 2158911488 ODDMC_DataID3 "UNM";
BA_ "PacketOrder" SG_ 2158911488 ODDMC_DataID3 10;
BA_ "SignalLongName" SG_ 2158911488 ODDMC_DataID3 "Open Display Interface Dynamic Data Multi Request CenterStack : Data ID Three";
BA_ "VNSigAllNodes" SG_ 2158911488 ODDMC_DataID3 1;
BA_ "GenSigDeltaValue" SG_ 2158911488 ODDMC_DataID1 1;
BA_ "GenSigSendType" SG_ 2158911488 ODDMC_DataID1 12;
BA_ "VNSigInfotainment" SG_ 2158911488 ODDMC_DataID1 1;
BA_ "SignalType" SG_ 2158911488 ODDMC_DataID1 "UNM";
BA_ "PacketOrder" SG_ 2158911488 ODDMC_DataID1 8;
BA_ "SignalLongName" SG_ 2158911488 ODDMC_DataID1 "Open Display Interface Dynamic Data Multi Request CenterStack : Data ID One";
BA_ "VNSigAllNodes" SG_ 2158911488 ODDMC_DataID1 1;
BA_ "GenSigSendType" SG_ 2158911488 ODDMC_DataID4Vld 10;
BA_ "VNSigInfotainment" SG_ 2158911488 ODDMC_DataID4Vld 1;
BA_ "SignalType" SG_ 2158911488 ODDMC_DataID4Vld "BLN";
BA_ "PacketOrder" SG_ 2158911488 ODDMC_DataID4Vld 3;
BA_ "SignalLongName" SG_ 2158911488 ODDMC_DataID4Vld "Open Display Interface Dynamic Data Multi Request CenterStack : Data ID Four Valid";
BA_ "VNSigAllNodes" SG_ 2158911488 ODDMC_DataID4Vld 1;
BA_ "GenSigDeltaValue" SG_ 2158911488 ODDMC_DataID4 1;
BA_ "GenSigSendType" SG_ 2158911488 ODDMC_DataID4 12;
BA_ "VNSigInfotainment" SG_ 2158911488 ODDMC_DataID4 1;
BA_ "SignalType" SG_ 2158911488 ODDMC_DataID4 "UNM";
BA_ "PacketOrder" SG_ 2158911488 ODDMC_DataID4 11;
BA_ "SignalLongName" SG_ 2158911488 ODDMC_DataID4 "Open Display Interface Dynamic Data Multi Request CenterStack : Data ID Four";
BA_ "VNSigAllNodes" SG_ 2158911488 ODDMC_DataID4 1;
BA_ "GenSigSendType" SG_ 2158911488 ODDMC_DataID5Vld 10;
BA_ "VNSigInfotainment" SG_ 2158911488 ODDMC_DataID5Vld 1;
BA_ "SignalType" SG_ 2158911488 ODDMC_DataID5Vld "BLN";
BA_ "PacketOrder" SG_ 2158911488 ODDMC_DataID5Vld 2;
BA_ "SignalLongName" SG_ 2158911488 ODDMC_DataID5Vld "Open Display Interface Dynamic Data Multi Request CenterStack : Data ID Five Valid";
BA_ "VNSigAllNodes" SG_ 2158911488 ODDMC_DataID5Vld 1;
BA_ "GenSigDeltaValue" SG_ 2158911488 ODDMC_DataID5 1;
BA_ "GenSigSendType" SG_ 2158911488 ODDMC_DataID5 12;
BA_ "VNSigInfotainment" SG_ 2158911488 ODDMC_DataID5 1;
BA_ "SignalType" SG_ 2158911488 ODDMC_DataID5 "UNM";
BA_ "PacketOrder" SG_ 2158911488 ODDMC_DataID5 12;
BA_ "SignalLongName" SG_ 2158911488 ODDMC_DataID5 "Open Display Interface Dynamic Data Multi Request CenterStack : Data ID Five";
BA_ "VNSigAllNodes" SG_ 2158911488 ODDMC_DataID5 1;
BA_ "GenSigDeltaValue" SG_ 2158911488 ODDMC_FUCID 1;
BA_ "GenSigSendType" SG_ 2158911488 ODDMC_FUCID 12;
BA_ "VNSigInfotainment" SG_ 2158911488 ODDMC_FUCID 1;
BA_ "SignalType" SG_ 2158911488 ODDMC_FUCID "UNM";
BA_ "PacketOrder" SG_ 2158911488 ODDMC_FUCID 6;
BA_ "SignalLongName" SG_ 2158911488 ODDMC_FUCID "Open Display Interface Dynamic Data Multi Request Center Stack : Functional Unit Class ID";
BA_ "VNSigAllNodes" SG_ 2158911488 ODDMC_FUCID 1;
BA_ "GenSigSendType" SG_ 2158919680 ODDMI_ReqType 10;
BA_ "VNSigInfotainment" SG_ 2158919680 ODDMI_ReqType 1;
BA_ "SignalType" SG_ 2158919680 ODDMI_ReqType "ENM";
BA_ "PacketOrder" SG_ 2158919680 ODDMI_ReqType 1;
BA_ "SignalLongName" SG_ 2158919680 ODDMI_ReqType "Open Display Interface Dynamic Data Multi Request IPC : Request Type";
BA_ "VNSigAllNodes" SG_ 2158919680 ODDMI_ReqType 1;
BA_ "GenSigDeltaValue" SG_ 2158919680 ODDMI_FUCID 1;
BA_ "GenSigSendType" SG_ 2158919680 ODDMI_FUCID 12;
BA_ "VNSigInfotainment" SG_ 2158919680 ODDMI_FUCID 1;
BA_ "SignalType" SG_ 2158919680 ODDMI_FUCID "UNM";
BA_ "PacketOrder" SG_ 2158919680 ODDMI_FUCID 6;
BA_ "SignalLongName" SG_ 2158919680 ODDMI_FUCID "Open Display Interface Dynamic Data Multi Request IPC : Functional Unit Class ID";
BA_ "VNSigAllNodes" SG_ 2158919680 ODDMI_FUCID 1;
BA_ "GenSigSendType" SG_ 2158919680 ODDMI_DispMID 10;
BA_ "VNSigInfotainment" SG_ 2158919680 ODDMI_DispMID 1;
BA_ "SignalType" SG_ 2158919680 ODDMI_DispMID "ENM";
BA_ "PacketOrder" SG_ 2158919680 ODDMI_DispMID 7;
BA_ "SignalLongName" SG_ 2158919680 ODDMI_DispMID "Open Display Interface Dynamic Data Multi Request IPC : Display Mask Id";
BA_ "VNSigAllNodes" SG_ 2158919680 ODDMI_DispMID 1;
BA_ "GenSigSendType" SG_ 2158919680 ODDMI_DataID2Vld 10;
BA_ "VNSigInfotainment" SG_ 2158919680 ODDMI_DataID2Vld 1;
BA_ "SignalType" SG_ 2158919680 ODDMI_DataID2Vld "BLN";
BA_ "PacketOrder" SG_ 2158919680 ODDMI_DataID2Vld 5;
BA_ "SignalLongName" SG_ 2158919680 ODDMI_DataID2Vld "Open Display Interface Dynamic Data Multi Request IPC : Data ID Two Valid";
BA_ "VNSigAllNodes" SG_ 2158919680 ODDMI_DataID2Vld 1;
BA_ "GenSigDeltaValue" SG_ 2158919680 ODDMI_DataID2 1;
BA_ "GenSigSendType" SG_ 2158919680 ODDMI_DataID2 12;
BA_ "VNSigInfotainment" SG_ 2158919680 ODDMI_DataID2 1;
BA_ "SignalType" SG_ 2158919680 ODDMI_DataID2 "UNM";
BA_ "PacketOrder" SG_ 2158919680 ODDMI_DataID2 9;
BA_ "SignalLongName" SG_ 2158919680 ODDMI_DataID2 "Open Display Interface Dynamic Data Multi Request IPC : Data ID Two";
BA_ "VNSigAllNodes" SG_ 2158919680 ODDMI_DataID2 1;
BA_ "GenSigSendType" SG_ 2158919680 ODDMI_DataID3Vld 10;
BA_ "VNSigInfotainment" SG_ 2158919680 ODDMI_DataID3Vld 1;
BA_ "SignalType" SG_ 2158919680 ODDMI_DataID3Vld "BLN";
BA_ "PacketOrder" SG_ 2158919680 ODDMI_DataID3Vld 4;
BA_ "SignalLongName" SG_ 2158919680 ODDMI_DataID3Vld "Open Display Interface Dynamic Data Multi Request IPC : Data ID Three Valid";
BA_ "VNSigAllNodes" SG_ 2158919680 ODDMI_DataID3Vld 1;
BA_ "GenSigSendType" SG_ 2158919680 ODDMI_DataID3 12;
BA_ "VNSigInfotainment" SG_ 2158919680 ODDMI_DataID3 1;
BA_ "SignalType" SG_ 2158919680 ODDMI_DataID3 "UNM";
BA_ "PacketOrder" SG_ 2158919680 ODDMI_DataID3 10;
BA_ "SignalLongName" SG_ 2158919680 ODDMI_DataID3 "Open Display Interface Dynamic Data Multi Request IPC : Data ID Three";
BA_ "VNSigAllNodes" SG_ 2158919680 ODDMI_DataID3 1;
BA_ "GenSigDeltaValue" SG_ 2158919680 ODDMI_DataID1 1;
BA_ "GenSigSendType" SG_ 2158919680 ODDMI_DataID1 12;
BA_ "VNSigInfotainment" SG_ 2158919680 ODDMI_DataID1 1;
BA_ "SignalType" SG_ 2158919680 ODDMI_DataID1 "UNM";
BA_ "PacketOrder" SG_ 2158919680 ODDMI_DataID1 8;
BA_ "SignalLongName" SG_ 2158919680 ODDMI_DataID1 "Open Display Interface Dynamic Data Multi Request IPC : Data ID One";
BA_ "VNSigAllNodes" SG_ 2158919680 ODDMI_DataID1 1;
BA_ "GenSigSendType" SG_ 2158919680 ODDMI_DataID4Vld 10;
BA_ "VNSigInfotainment" SG_ 2158919680 ODDMI_DataID4Vld 1;
BA_ "SignalType" SG_ 2158919680 ODDMI_DataID4Vld "BLN";
BA_ "PacketOrder" SG_ 2158919680 ODDMI_DataID4Vld 3;
BA_ "SignalLongName" SG_ 2158919680 ODDMI_DataID4Vld "Open Display Interface Dynamic Data Multi Request IPC : Data ID Four Valid";
BA_ "VNSigAllNodes" SG_ 2158919680 ODDMI_DataID4Vld 1;
BA_ "GenSigDeltaValue" SG_ 2158919680 ODDMI_DataID4 1;
BA_ "GenSigSendType" SG_ 2158919680 ODDMI_DataID4 12;
BA_ "VNSigInfotainment" SG_ 2158919680 ODDMI_DataID4 1;
BA_ "SignalType" SG_ 2158919680 ODDMI_DataID4 "UNM";
BA_ "PacketOrder" SG_ 2158919680 ODDMI_DataID4 11;
BA_ "SignalLongName" SG_ 2158919680 ODDMI_DataID4 "Open Display Interface Dynamic Data Multi Request IPC : Data ID Four";
BA_ "VNSigAllNodes" SG_ 2158919680 ODDMI_DataID4 1;
BA_ "GenSigSendType" SG_ 2158919680 ODDMI_DataID5Vld 10;
BA_ "VNSigInfotainment" SG_ 2158919680 ODDMI_DataID5Vld 1;
BA_ "SignalType" SG_ 2158919680 ODDMI_DataID5Vld "BLN";
BA_ "PacketOrder" SG_ 2158919680 ODDMI_DataID5Vld 2;
BA_ "SignalLongName" SG_ 2158919680 ODDMI_DataID5Vld "Open Display Interface Dynamic Data Multi Request IPC : Data ID Five Valid";
BA_ "VNSigAllNodes" SG_ 2158919680 ODDMI_DataID5Vld 1;
BA_ "GenSigDeltaValue" SG_ 2158919680 ODDMI_DataID5 1;
BA_ "GenSigSendType" SG_ 2158919680 ODDMI_DataID5 12;
BA_ "VNSigInfotainment" SG_ 2158919680 ODDMI_DataID5 1;
BA_ "SignalType" SG_ 2158919680 ODDMI_DataID5 "UNM";
BA_ "PacketOrder" SG_ 2158919680 ODDMI_DataID5 12;
BA_ "SignalLongName" SG_ 2158919680 ODDMI_DataID5 "Open Display Interface Dynamic Data Multi Request IPC : Data ID Five";
BA_ "VNSigAllNodes" SG_ 2158919680 ODDMI_DataID5 1;
BA_ "GenSigSendType" SG_ 2151825408 OtsAirTmpV 10;
BA_ "SignalType" SG_ 2151825408 OtsAirTmpV "ENM";
BA_ "SignalLongName" SG_ 2151825408 OtsAirTmpV "Outside Air Temperature Validity";
BA_ "VNSigAllNodes" SG_ 2151825408 OtsAirTmpV 1;
BA_ "GenSigDeltaValue" SG_ 2151825408 OtsAirTmp 1;
BA_ "GenSigSendType" SG_ 2151825408 OtsAirTmp 12;
BA_ "GenSigSendOnInit" SG_ 2151825408 OtsAirTmp 1;
BA_ "SignalType" SG_ 2151825408 OtsAirTmp "UNM";
BA_ "SignalLongName" SG_ 2151825408 OtsAirTmp "Outside Air Temperature";
BA_ "VNSigAllNodes" SG_ 2151825408 OtsAirTmp 1;
BA_ "GenSigSendType" SG_ 2151825408 OtsAirTmpCrValV 10;
BA_ "VNSigInfotainment" SG_ 2151825408 OtsAirTmpCrValV 1;
BA_ "SignalType" SG_ 2151825408 OtsAirTmpCrValV "ENM";
BA_ "SignalLongName" SG_ 2151825408 OtsAirTmpCrValV "Outside Air Temperature Corrected Value Validity";
BA_ "VNSigAllNodes" SG_ 2151825408 OtsAirTmpCrValV 1;
BA_ "GenSigDeltaValue" SG_ 2151825408 OtsAirTmpCrVal 1;
BA_ "GenSigSendType" SG_ 2151825408 OtsAirTmpCrVal 12;
BA_ "GenSigSendOnInit" SG_ 2151825408 OtsAirTmpCrVal 1;
BA_ "VNSigInfotainment" SG_ 2151825408 OtsAirTmpCrVal 1;
BA_ "SignalType" SG_ 2151825408 OtsAirTmpCrVal "UNM";
BA_ "SignalLongName" SG_ 2151825408 OtsAirTmpCrVal "Outside Air Temperature Corrected Value";
BA_ "VNSigAllNodes" SG_ 2151825408 OtsAirTmpCrVal 1;
BA_ "GenSigSendType" SG_ 2151825408 OtsAirTmpCrValMsk 10;
BA_ "SignalType" SG_ 2151825408 OtsAirTmpCrValMsk "ENM";
BA_ "SignalLongName" SG_ 2151825408 OtsAirTmpCrValMsk "Outside Air Temperature Corrected Value Mask";
BA_ "VNSigAllNodes" SG_ 2151825408 OtsAirTmpCrValMsk 1;
BA_ "GenSigSendType" SG_ 2151153664 RrWndDfgOn 10;
BA_ "GenSigSendOnInit" SG_ 2151153664 RrWndDfgOn 1;
BA_ "SignalType" SG_ 2151153664 RrWndDfgOn "BLN";
BA_ "SignalLongName" SG_ 2151153664 RrWndDfgOn "Rear Window Defog On";
BA_ "VNSigAllNodes" SG_ 2151153664 RrWndDfgOn 1;
BA_ "GenSigSendType" SG_ 2151170048 RrEndCrrStat 10;
BA_ "SignalType" SG_ 2151170048 RrEndCrrStat "ENM";
BA_ "SignalLongName" SG_ 2151170048 RrEndCrrStat "Rear End Carrier Status";
BA_ "VNSigAllNodes" SG_ 2151170048 RrEndCrrStat 1;
BA_ "GenSigSendType" SG_ 2151170048 RRPrkLmpFld 10;
BA_ "SignalType" SG_ 2151170048 RRPrkLmpFld "BLN";
BA_ "SignalLongName" SG_ 2151170048 RRPrkLmpFld "Rear Right Park Lamp Failed";
BA_ "VNSigAllNodes" SG_ 2151170048 RRPrkLmpFld 1;
BA_ "GenSigSendType" SG_ 2151170048 RLftPrkLmpFld 10;
BA_ "SignalType" SG_ 2151170048 RLftPrkLmpFld "BLN";
BA_ "SignalLongName" SG_ 2151170048 RLftPrkLmpFld "Rear Left Park Lamp Failed";
BA_ "VNSigAllNodes" SG_ 2151170048 RLftPrkLmpFld 1;
BA_ "GenSigSendType" SG_ 2151170048 DisRrPrmryLmps 10;
BA_ "SignalType" SG_ 2151170048 DisRrPrmryLmps "BLN";
BA_ "SignalLongName" SG_ 2151170048 DisRrPrmryLmps "Disable Rear Primary Lamps";
BA_ "VNSigAllNodes" SG_ 2151170048 DisRrPrmryLmps 1;
BA_ "GenSigSendType" SG_ 2151170048 TrlrTlLtFld 10;
BA_ "SignalType" SG_ 2151170048 TrlrTlLtFld "BLN";
BA_ "SignalLongName" SG_ 2151170048 TrlrTlLtFld "Trailer Tail Light Failed";
BA_ "VNSigAllNodes" SG_ 2151170048 TrlrTlLtFld 1;
BA_ "GenSigSendType" SG_ 2151170048 TrlrRvsLtFld 10;
BA_ "SignalType" SG_ 2151170048 TrlrRvsLtFld "BLN";
BA_ "SignalLongName" SG_ 2151170048 TrlrRvsLtFld "Trailer Reverse Light Failed";
BA_ "VNSigAllNodes" SG_ 2151170048 TrlrRvsLtFld 1;
BA_ "GenSigSendType" SG_ 2151170048 TrlrFgLtFld 10;
BA_ "SignalType" SG_ 2151170048 TrlrFgLtFld "BLN";
BA_ "SignalLongName" SG_ 2151170048 TrlrFgLtFld "Trailer Fog Light Failed";
BA_ "VNSigAllNodes" SG_ 2151170048 TrlrFgLtFld 1;
BA_ "GenSigSendType" SG_ 2151170048 TrlrBrkLtFld 10;
BA_ "SignalType" SG_ 2151170048 TrlrBrkLtFld "BLN";
BA_ "SignalLongName" SG_ 2151170048 TrlrBrkLtFld "Trailer Brake Light Failed";
BA_ "VNSigAllNodes" SG_ 2151170048 TrlrBrkLtFld 1;
BA_ "GenSigSendType" SG_ 2151170048 TrlrRtTrInLtFld 10;
BA_ "GenSigSendOnInit" SG_ 2151170048 TrlrRtTrInLtFld 1;
BA_ "SignalType" SG_ 2151170048 TrlrRtTrInLtFld "BLN";
BA_ "SignalLongName" SG_ 2151170048 TrlrRtTrInLtFld "Trailer Right Turn Indicator Light Failed";
BA_ "VNSigAllNodes" SG_ 2151170048 TrlrRtTrInLtFld 1;
BA_ "GenSigSendType" SG_ 2151170048 TrlLfTrInLtFld 10;
BA_ "GenSigSendOnInit" SG_ 2151170048 TrlLfTrInLtFld 1;
BA_ "SignalType" SG_ 2151170048 TrlLfTrInLtFld "BLN";
BA_ "SignalLongName" SG_ 2151170048 TrlLfTrInLtFld "Trailer Left Turn Indicator Light Failed";
BA_ "VNSigAllNodes" SG_ 2151170048 TrlLfTrInLtFld 1;
BA_ "GenSigSendType" SG_ 2151170048 TrlrHtchSwAtv 10;
BA_ "GenSigSendOnInit" SG_ 2151170048 TrlrHtchSwAtv 2;
BA_ "VNSigParkedVehicle" SG_ 2151170048 TrlrHtchSwAtv 1;
BA_ "SignalType" SG_ 2151170048 TrlrHtchSwAtv "BLN";
BA_ "SignalLongName" SG_ 2151170048 TrlrHtchSwAtv "Trailer Hitch Switch Active";
BA_ "VNSigAllNodes" SG_ 2151170048 TrlrHtchSwAtv 1;
BA_ "GenSigSendType" SG_ 2151170048 RtSecTrnIndFld 10;
BA_ "SignalType" SG_ 2151170048 RtSecTrnIndFld "BLN";
BA_ "SignalLongName" SG_ 2151170048 RtSecTrnIndFld "Right Secondary Turn Indicator Failed";
BA_ "VNSigAllNodes" SG_ 2151170048 RtSecTrnIndFld 1;
BA_ "GenSigSendType" SG_ 2151170048 TrlrFgLtPrs 10;
BA_ "SignalType" SG_ 2151170048 TrlrFgLtPrs "BLN";
BA_ "SignalLongName" SG_ 2151170048 TrlrFgLtPrs "Trailer Fog Light Present";
BA_ "VNSigAllNodes" SG_ 2151170048 TrlrFgLtPrs 1;
BA_ "GenSigSendType" SG_ 2151170048 LftSecTrnIndFld 10;
BA_ "SignalType" SG_ 2151170048 LftSecTrnIndFld "BLN";
BA_ "SignalLongName" SG_ 2151170048 LftSecTrnIndFld "Left Secondary Turn Indicator Failed";
BA_ "VNSigAllNodes" SG_ 2151170048 LftSecTrnIndFld 1;
BA_ "GenSigSendType" SG_ 2151841792 WSWprAct 10;
BA_ "SignalType" SG_ 2151841792 WSWprAct "BLN";
BA_ "SignalLongName" SG_ 2151841792 WSWprAct "Windshield Wiper Active";
BA_ "VNSigAllNodes" SG_ 2151841792 WSWprAct 1;
BA_ "GenSigSendType" SG_ 2151841792 RnSnsOffIO 10;
BA_ "GenSigSendOnInit" SG_ 2151841792 RnSnsOffIO 2;
BA_ "SignalType" SG_ 2151841792 RnSnsOffIO "BLN";
BA_ "SignalLongName" SG_ 2151841792 RnSnsOffIO "Rain Sensor Off Indication On";
BA_ "VNSigAllNodes" SG_ 2151841792 RnSnsOffIO 1;
BA_ "GenSigSendType" SG_ 2151841792 RnSnsActIO 10;
BA_ "SignalType" SG_ 2151841792 RnSnsActIO "BLN";
BA_ "SignalLongName" SG_ 2151841792 RnSnsActIO "Rain Sensor Active Indication On";
BA_ "VNSigAllNodes" SG_ 2151841792 RnSnsActIO 1;
BA_ "GenSigSendType" SG_ 2151841792 TurnWprIntIO 10;
BA_ "SignalType" SG_ 2151841792 TurnWprIntIO "BLN";
BA_ "SignalLongName" SG_ 2151841792 TurnWprIntIO "Turn Wiper Control To Intermittent First Indication On";
BA_ "VNSigAllNodes" SG_ 2151841792 TurnWprIntIO 1;
BA_ "GenSigSendType" SG_ 2154995712 HVHtrFldIO 10;
BA_ "SignalType" SG_ 2154995712 HVHtrFldIO "BLN";
BA_ "SignalLongName" SG_ 2154995712 HVHtrFldIO "High Voltage Heater Failed Indication On";
BA_ "VNSigAllNodes" SG_ 2154995712 HVHtrFldIO 1;
BA_ "GenSigSendType" SG_ 2154995712 HVHtrOvrTmpIndOn 10;
BA_ "SignalType" SG_ 2154995712 HVHtrOvrTmpIndOn "BLN";
BA_ "SignalLongName" SG_ 2154995712 HVHtrOvrTmpIndOn "High Voltage Heater Over Temperature Indication On";
BA_ "VNSigAllNodes" SG_ 2154995712 HVHtrOvrTmpIndOn 1;
BA_ "GenSigSendType" SG_ 2154094592 IntDimSeldClrTypStVal 10;
BA_ "GenSigSendOnInit" SG_ 2154094592 IntDimSeldClrTypStVal 1;
BA_ "SignalType" SG_ 2154094592 IntDimSeldClrTypStVal "ENM";
BA_ "SignalLongName" SG_ 2154094592 IntDimSeldClrTypStVal "Interior Dimming Selected Color Type Setting Value";
BA_ "VNSigAllNodes" SG_ 2154094592 IntDimSeldClrTypStVal 1;
BA_ "GenSigSendType" SG_ 2154094592 IntDimSeldAnmTypStVal 10;
BA_ "GenSigSendOnInit" SG_ 2154094592 IntDimSeldAnmTypStVal 1;
BA_ "SignalType" SG_ 2154094592 IntDimSeldAnmTypStVal "ENM";
BA_ "SignalLongName" SG_ 2154094592 IntDimSeldAnmTypStVal "Interior Dimming Selected Animation Type Setting Value";
BA_ "VNSigAllNodes" SG_ 2154094592 IntDimSeldAnmTypStVal 1;
BA_ "GenSigSendType" SG_ 2154094592 IDCTA_ClrTyp30Avl 10;
BA_ "GenSigSendOnInit" SG_ 2154094592 IDCTA_ClrTyp30Avl 1;
BA_ "PacketOrder" SG_ 2154094592 IDCTA_ClrTyp30Avl 31;
BA_ "SignalType" SG_ 2154094592 IDCTA_ClrTyp30Avl "BLN";
BA_ "SignalLongName" SG_ 2154094592 IDCTA_ClrTyp30Avl "Interior Dimming Color Type Available : Color Type 30 Available";
BA_ "VNSigAllNodes" SG_ 2154094592 IDCTA_ClrTyp30Avl 1;
BA_ "GenSigSendType" SG_ 2154094592 IDCTA_ClrTyp29Avl 10;
BA_ "GenSigSendOnInit" SG_ 2154094592 IDCTA_ClrTyp29Avl 1;
BA_ "PacketOrder" SG_ 2154094592 IDCTA_ClrTyp29Avl 30;
BA_ "SignalType" SG_ 2154094592 IDCTA_ClrTyp29Avl "BLN";
BA_ "SignalLongName" SG_ 2154094592 IDCTA_ClrTyp29Avl "Interior Dimming Color Type Available : Color Type 29 Available";
BA_ "VNSigAllNodes" SG_ 2154094592 IDCTA_ClrTyp29Avl 1;
BA_ "GenSigSendType" SG_ 2154094592 IDCTA_ClrTyp28Avl 10;
BA_ "GenSigSendOnInit" SG_ 2154094592 IDCTA_ClrTyp28Avl 1;
BA_ "PacketOrder" SG_ 2154094592 IDCTA_ClrTyp28Avl 29;
BA_ "SignalType" SG_ 2154094592 IDCTA_ClrTyp28Avl "BLN";
BA_ "SignalLongName" SG_ 2154094592 IDCTA_ClrTyp28Avl "Interior Dimming Color Type Available : Color Type 28 Available";
BA_ "VNSigAllNodes" SG_ 2154094592 IDCTA_ClrTyp28Avl 1;
BA_ "GenSigSendType" SG_ 2154094592 IDCTA_ClrTyp27Avl 10;
BA_ "GenSigSendOnInit" SG_ 2154094592 IDCTA_ClrTyp27Avl 1;
BA_ "PacketOrder" SG_ 2154094592 IDCTA_ClrTyp27Avl 28;
BA_ "SignalType" SG_ 2154094592 IDCTA_ClrTyp27Avl "BLN";
BA_ "SignalLongName" SG_ 2154094592 IDCTA_ClrTyp27Avl "Interior Dimming Color Type Available : Color Type 27 Available";
BA_ "VNSigAllNodes" SG_ 2154094592 IDCTA_ClrTyp27Avl 1;
BA_ "GenSigSendType" SG_ 2154094592 IDCTA_ClrTyp26Avl 10;
BA_ "GenSigSendOnInit" SG_ 2154094592 IDCTA_ClrTyp26Avl 1;
BA_ "PacketOrder" SG_ 2154094592 IDCTA_ClrTyp26Avl 27;
BA_ "SignalType" SG_ 2154094592 IDCTA_ClrTyp26Avl "BLN";
BA_ "SignalLongName" SG_ 2154094592 IDCTA_ClrTyp26Avl "Interior Dimming Color Type Available : Color Type 26 Available";
BA_ "VNSigAllNodes" SG_ 2154094592 IDCTA_ClrTyp26Avl 1;
BA_ "GenSigSendType" SG_ 2154094592 IDCTA_ClrTyp25Avl 10;
BA_ "GenSigSendOnInit" SG_ 2154094592 IDCTA_ClrTyp25Avl 1;
BA_ "PacketOrder" SG_ 2154094592 IDCTA_ClrTyp25Avl 26;
BA_ "SignalType" SG_ 2154094592 IDCTA_ClrTyp25Avl "BLN";
BA_ "SignalLongName" SG_ 2154094592 IDCTA_ClrTyp25Avl "Interior Dimming Color Type Available : Color Type 25 Available";
BA_ "VNSigAllNodes" SG_ 2154094592 IDCTA_ClrTyp25Avl 1;
BA_ "GenSigSendType" SG_ 2154094592 IDCTA_ClrTyp24Avl 10;
BA_ "GenSigSendOnInit" SG_ 2154094592 IDCTA_ClrTyp24Avl 1;
BA_ "PacketOrder" SG_ 2154094592 IDCTA_ClrTyp24Avl 25;
BA_ "SignalType" SG_ 2154094592 IDCTA_ClrTyp24Avl "BLN";
BA_ "SignalLongName" SG_ 2154094592 IDCTA_ClrTyp24Avl "Interior Dimming Color Type Available : Color Type 24 Available";
BA_ "VNSigAllNodes" SG_ 2154094592 IDCTA_ClrTyp24Avl 1;
BA_ "GenSigSendType" SG_ 2154094592 IDCTA_ClrTyp23Avl 10;
BA_ "GenSigSendOnInit" SG_ 2154094592 IDCTA_ClrTyp23Avl 1;
BA_ "PacketOrder" SG_ 2154094592 IDCTA_ClrTyp23Avl 24;
BA_ "SignalType" SG_ 2154094592 IDCTA_ClrTyp23Avl "BLN";
BA_ "SignalLongName" SG_ 2154094592 IDCTA_ClrTyp23Avl "Interior Dimming Color Type Available : Color Type 23 Available";
BA_ "VNSigAllNodes" SG_ 2154094592 IDCTA_ClrTyp23Avl 1;
BA_ "GenSigSendType" SG_ 2154094592 IDCTA_ClrTyp22Avl 10;
BA_ "GenSigSendOnInit" SG_ 2154094592 IDCTA_ClrTyp22Avl 1;
BA_ "PacketOrder" SG_ 2154094592 IDCTA_ClrTyp22Avl 23;
BA_ "SignalType" SG_ 2154094592 IDCTA_ClrTyp22Avl "BLN";
BA_ "SignalLongName" SG_ 2154094592 IDCTA_ClrTyp22Avl "Interior Dimming Color Type Available : Color Type 22 Available";
BA_ "VNSigAllNodes" SG_ 2154094592 IDCTA_ClrTyp22Avl 1;
BA_ "GenSigSendType" SG_ 2154094592 IDCTA_ClrTyp21Avl 10;
BA_ "GenSigSendOnInit" SG_ 2154094592 IDCTA_ClrTyp21Avl 1;
BA_ "PacketOrder" SG_ 2154094592 IDCTA_ClrTyp21Avl 22;
BA_ "SignalType" SG_ 2154094592 IDCTA_ClrTyp21Avl "BLN";
BA_ "SignalLongName" SG_ 2154094592 IDCTA_ClrTyp21Avl "Interior Dimming Color Type Available : Color Type 21 Available";
BA_ "VNSigAllNodes" SG_ 2154094592 IDCTA_ClrTyp21Avl 1;
BA_ "GenSigSendType" SG_ 2154094592 IDCTA_ClrTyp20Avl 10;
BA_ "GenSigSendOnInit" SG_ 2154094592 IDCTA_ClrTyp20Avl 1;
BA_ "PacketOrder" SG_ 2154094592 IDCTA_ClrTyp20Avl 21;
BA_ "SignalType" SG_ 2154094592 IDCTA_ClrTyp20Avl "BLN";
BA_ "SignalLongName" SG_ 2154094592 IDCTA_ClrTyp20Avl "Interior Dimming Color Type Available : Color Type 20 Available";
BA_ "VNSigAllNodes" SG_ 2154094592 IDCTA_ClrTyp20Avl 1;
BA_ "GenSigSendType" SG_ 2154094592 IDCTA_ClrTyp19Avl 10;
BA_ "GenSigSendOnInit" SG_ 2154094592 IDCTA_ClrTyp19Avl 1;
BA_ "PacketOrder" SG_ 2154094592 IDCTA_ClrTyp19Avl 20;
BA_ "SignalType" SG_ 2154094592 IDCTA_ClrTyp19Avl "BLN";
BA_ "SignalLongName" SG_ 2154094592 IDCTA_ClrTyp19Avl "Interior Dimming Color Type Available : Color Type 19 Available";
BA_ "VNSigAllNodes" SG_ 2154094592 IDCTA_ClrTyp19Avl 1;
BA_ "GenSigSendType" SG_ 2154094592 IDCTA_ClrTyp18Avl 10;
BA_ "GenSigSendOnInit" SG_ 2154094592 IDCTA_ClrTyp18Avl 1;
BA_ "PacketOrder" SG_ 2154094592 IDCTA_ClrTyp18Avl 19;
BA_ "SignalType" SG_ 2154094592 IDCTA_ClrTyp18Avl "BLN";
BA_ "SignalLongName" SG_ 2154094592 IDCTA_ClrTyp18Avl "Interior Dimming Color Type Available : Color Type 18 Available";
BA_ "VNSigAllNodes" SG_ 2154094592 IDCTA_ClrTyp18Avl 1;
BA_ "GenSigSendType" SG_ 2154094592 IDCTA_ClrTyp17Avl 10;
BA_ "GenSigSendOnInit" SG_ 2154094592 IDCTA_ClrTyp17Avl 1;
BA_ "PacketOrder" SG_ 2154094592 IDCTA_ClrTyp17Avl 18;
BA_ "SignalType" SG_ 2154094592 IDCTA_ClrTyp17Avl "BLN";
BA_ "SignalLongName" SG_ 2154094592 IDCTA_ClrTyp17Avl "Interior Dimming Color Type Available : Color Type 17 Available";
BA_ "VNSigAllNodes" SG_ 2154094592 IDCTA_ClrTyp17Avl 1;
BA_ "GenSigSendType" SG_ 2154094592 IDCTA_ClrTyp16Avl 10;
BA_ "GenSigSendOnInit" SG_ 2154094592 IDCTA_ClrTyp16Avl 1;
BA_ "PacketOrder" SG_ 2154094592 IDCTA_ClrTyp16Avl 17;
BA_ "SignalType" SG_ 2154094592 IDCTA_ClrTyp16Avl "BLN";
BA_ "SignalLongName" SG_ 2154094592 IDCTA_ClrTyp16Avl "Interior Dimming Color Type Available : Color Type 16 Available";
BA_ "VNSigAllNodes" SG_ 2154094592 IDCTA_ClrTyp16Avl 1;
BA_ "GenSigSendType" SG_ 2154094592 IDCTA_ClrTyp15Avl 10;
BA_ "GenSigSendOnInit" SG_ 2154094592 IDCTA_ClrTyp15Avl 1;
BA_ "PacketOrder" SG_ 2154094592 IDCTA_ClrTyp15Avl 16;
BA_ "SignalType" SG_ 2154094592 IDCTA_ClrTyp15Avl "BLN";
BA_ "SignalLongName" SG_ 2154094592 IDCTA_ClrTyp15Avl "Interior Dimming Color Type Available : Color Type 15 Available";
BA_ "VNSigAllNodes" SG_ 2154094592 IDCTA_ClrTyp15Avl 1;
BA_ "GenSigSendType" SG_ 2154094592 IDCTA_ClrTyp14Avl 10;
BA_ "GenSigSendOnInit" SG_ 2154094592 IDCTA_ClrTyp14Avl 1;
BA_ "PacketOrder" SG_ 2154094592 IDCTA_ClrTyp14Avl 15;
BA_ "SignalType" SG_ 2154094592 IDCTA_ClrTyp14Avl "BLN";
BA_ "SignalLongName" SG_ 2154094592 IDCTA_ClrTyp14Avl "Interior Dimming Color Type Available : Color Type 14 Available";
BA_ "VNSigAllNodes" SG_ 2154094592 IDCTA_ClrTyp14Avl 1;
BA_ "GenSigSendType" SG_ 2154094592 IDCTA_ClrTyp13Avl 10;
BA_ "GenSigSendOnInit" SG_ 2154094592 IDCTA_ClrTyp13Avl 1;
BA_ "PacketOrder" SG_ 2154094592 IDCTA_ClrTyp13Avl 14;
BA_ "SignalType" SG_ 2154094592 IDCTA_ClrTyp13Avl "BLN";
BA_ "SignalLongName" SG_ 2154094592 IDCTA_ClrTyp13Avl "Interior Dimming Color Type Available : Color Type 13 Available";
BA_ "VNSigAllNodes" SG_ 2154094592 IDCTA_ClrTyp13Avl 1;
BA_ "GenSigSendType" SG_ 2154094592 IDCTA_ClrTyp12Avl 10;
BA_ "GenSigSendOnInit" SG_ 2154094592 IDCTA_ClrTyp12Avl 1;
BA_ "PacketOrder" SG_ 2154094592 IDCTA_ClrTyp12Avl 13;
BA_ "SignalType" SG_ 2154094592 IDCTA_ClrTyp12Avl "BLN";
BA_ "SignalLongName" SG_ 2154094592 IDCTA_ClrTyp12Avl "Interior Dimming Color Type Available : Color Type 12 Available";
BA_ "VNSigAllNodes" SG_ 2154094592 IDCTA_ClrTyp12Avl 1;
BA_ "GenSigSendType" SG_ 2154094592 IDCTA_ClrTyp11Avl 10;
BA_ "GenSigSendOnInit" SG_ 2154094592 IDCTA_ClrTyp11Avl 1;
BA_ "PacketOrder" SG_ 2154094592 IDCTA_ClrTyp11Avl 12;
BA_ "SignalType" SG_ 2154094592 IDCTA_ClrTyp11Avl "BLN";
BA_ "SignalLongName" SG_ 2154094592 IDCTA_ClrTyp11Avl "Interior Dimming Color Type Available : Color Type 11 Available";
BA_ "VNSigAllNodes" SG_ 2154094592 IDCTA_ClrTyp11Avl 1;
BA_ "GenSigSendType" SG_ 2154094592 IDCTA_ClrTyp10Avl 10;
BA_ "GenSigSendOnInit" SG_ 2154094592 IDCTA_ClrTyp10Avl 1;
BA_ "PacketOrder" SG_ 2154094592 IDCTA_ClrTyp10Avl 11;
BA_ "SignalType" SG_ 2154094592 IDCTA_ClrTyp10Avl "BLN";
BA_ "SignalLongName" SG_ 2154094592 IDCTA_ClrTyp10Avl "Interior Dimming Color Type Available : Color Type 10 Available";
BA_ "VNSigAllNodes" SG_ 2154094592 IDCTA_ClrTyp10Avl 1;
BA_ "GenSigSendType" SG_ 2154094592 IDCTA_ClrTyp9Avl 10;
BA_ "GenSigSendOnInit" SG_ 2154094592 IDCTA_ClrTyp9Avl 1;
BA_ "PacketOrder" SG_ 2154094592 IDCTA_ClrTyp9Avl 10;
BA_ "SignalType" SG_ 2154094592 IDCTA_ClrTyp9Avl "BLN";
BA_ "SignalLongName" SG_ 2154094592 IDCTA_ClrTyp9Avl "Interior Dimming Color Type Available : Color Type 9 Available";
BA_ "VNSigAllNodes" SG_ 2154094592 IDCTA_ClrTyp9Avl 1;
BA_ "GenSigSendType" SG_ 2154094592 IDCTA_ClrTyp8Avl 10;
BA_ "GenSigSendOnInit" SG_ 2154094592 IDCTA_ClrTyp8Avl 1;
BA_ "PacketOrder" SG_ 2154094592 IDCTA_ClrTyp8Avl 9;
BA_ "SignalType" SG_ 2154094592 IDCTA_ClrTyp8Avl "BLN";
BA_ "SignalLongName" SG_ 2154094592 IDCTA_ClrTyp8Avl "Interior Dimming Color Type Available : Color Type 8 Available";
BA_ "VNSigAllNodes" SG_ 2154094592 IDCTA_ClrTyp8Avl 1;
BA_ "GenSigSendType" SG_ 2154094592 IDCTA_ClrTyp7Avl 10;
BA_ "GenSigSendOnInit" SG_ 2154094592 IDCTA_ClrTyp7Avl 1;
BA_ "PacketOrder" SG_ 2154094592 IDCTA_ClrTyp7Avl 8;
BA_ "SignalType" SG_ 2154094592 IDCTA_ClrTyp7Avl "BLN";
BA_ "SignalLongName" SG_ 2154094592 IDCTA_ClrTyp7Avl "Interior Dimming Color Type Available : Color Type 7 Available";
BA_ "VNSigAllNodes" SG_ 2154094592 IDCTA_ClrTyp7Avl 1;
BA_ "GenSigSendType" SG_ 2154094592 IDCTA_ClrTyp6Avl 10;
BA_ "GenSigSendOnInit" SG_ 2154094592 IDCTA_ClrTyp6Avl 1;
BA_ "PacketOrder" SG_ 2154094592 IDCTA_ClrTyp6Avl 7;
BA_ "SignalType" SG_ 2154094592 IDCTA_ClrTyp6Avl "BLN";
BA_ "SignalLongName" SG_ 2154094592 IDCTA_ClrTyp6Avl "Interior Dimming Color Type Available : Color Type 6 Available";
BA_ "VNSigAllNodes" SG_ 2154094592 IDCTA_ClrTyp6Avl 1;
BA_ "GenSigSendType" SG_ 2154094592 IDCTA_ClrTyp5Avl 10;
BA_ "GenSigSendOnInit" SG_ 2154094592 IDCTA_ClrTyp5Avl 1;
BA_ "PacketOrder" SG_ 2154094592 IDCTA_ClrTyp5Avl 6;
BA_ "SignalType" SG_ 2154094592 IDCTA_ClrTyp5Avl "BLN";
BA_ "SignalLongName" SG_ 2154094592 IDCTA_ClrTyp5Avl "Interior Dimming Color Type Available : Color Type 5 Available";
BA_ "VNSigAllNodes" SG_ 2154094592 IDCTA_ClrTyp5Avl 1;
BA_ "GenSigSendType" SG_ 2154094592 IDCTA_ClrTyp4Avl 10;
BA_ "GenSigSendOnInit" SG_ 2154094592 IDCTA_ClrTyp4Avl 1;
BA_ "PacketOrder" SG_ 2154094592 IDCTA_ClrTyp4Avl 5;
BA_ "SignalType" SG_ 2154094592 IDCTA_ClrTyp4Avl "BLN";
BA_ "SignalLongName" SG_ 2154094592 IDCTA_ClrTyp4Avl "Interior Dimming Color Type Available : Color Type 4 Available";
BA_ "VNSigAllNodes" SG_ 2154094592 IDCTA_ClrTyp4Avl 1;
BA_ "GenSigSendType" SG_ 2154094592 IDCTA_ClrTyp3Avl 10;
BA_ "GenSigSendOnInit" SG_ 2154094592 IDCTA_ClrTyp3Avl 1;
BA_ "PacketOrder" SG_ 2154094592 IDCTA_ClrTyp3Avl 4;
BA_ "SignalType" SG_ 2154094592 IDCTA_ClrTyp3Avl "BLN";
BA_ "SignalLongName" SG_ 2154094592 IDCTA_ClrTyp3Avl "Interior Dimming Color Type Available : Color Type 3 Available";
BA_ "VNSigAllNodes" SG_ 2154094592 IDCTA_ClrTyp3Avl 1;
BA_ "GenSigSendType" SG_ 2154094592 IDCTA_ClrTyp2Avl 10;
BA_ "GenSigSendOnInit" SG_ 2154094592 IDCTA_ClrTyp2Avl 1;
BA_ "PacketOrder" SG_ 2154094592 IDCTA_ClrTyp2Avl 3;
BA_ "SignalType" SG_ 2154094592 IDCTA_ClrTyp2Avl "BLN";
BA_ "SignalLongName" SG_ 2154094592 IDCTA_ClrTyp2Avl "Interior Dimming Color Type Available : Color Type 2 Available";
BA_ "VNSigAllNodes" SG_ 2154094592 IDCTA_ClrTyp2Avl 1;
BA_ "GenSigSendType" SG_ 2154094592 IDCTA_ClrTyp1Avl 10;
BA_ "GenSigSendOnInit" SG_ 2154094592 IDCTA_ClrTyp1Avl 1;
BA_ "PacketOrder" SG_ 2154094592 IDCTA_ClrTyp1Avl 2;
BA_ "SignalType" SG_ 2154094592 IDCTA_ClrTyp1Avl "BLN";
BA_ "SignalLongName" SG_ 2154094592 IDCTA_ClrTyp1Avl "Interior Dimming Color Type Available : Color Type 1 Available";
BA_ "VNSigAllNodes" SG_ 2154094592 IDCTA_ClrTyp1Avl 1;
BA_ "GenSigSendType" SG_ 2154094592 IDCTA_OffAvl 10;
BA_ "GenSigSendOnInit" SG_ 2154094592 IDCTA_OffAvl 1;
BA_ "PacketOrder" SG_ 2154094592 IDCTA_OffAvl 1;
BA_ "SignalType" SG_ 2154094592 IDCTA_OffAvl "BLN";
BA_ "SignalLongName" SG_ 2154094592 IDCTA_OffAvl "Interior Dimming Color Type Available : Off Available";
BA_ "VNSigAllNodes" SG_ 2154094592 IDCTA_OffAvl 1;
BA_ "GenSigSendType" SG_ 2154094592 IDATA_AnmTyp14Avl 10;
BA_ "GenSigSendOnInit" SG_ 2154094592 IDATA_AnmTyp14Avl 1;
BA_ "SignalType" SG_ 2154094592 IDATA_AnmTyp14Avl "BLN";
BA_ "PacketOrder" SG_ 2154094592 IDATA_AnmTyp14Avl 15;
BA_ "SignalLongName" SG_ 2154094592 IDATA_AnmTyp14Avl "Interior Dimming Animation Type Available : Animation Type 14 Available";
BA_ "VNSigAllNodes" SG_ 2154094592 IDATA_AnmTyp14Avl 1;
BA_ "GenSigSendType" SG_ 2154094592 IDATA_AnmTyp13Avl 10;
BA_ "GenSigSendOnInit" SG_ 2154094592 IDATA_AnmTyp13Avl 1;
BA_ "SignalType" SG_ 2154094592 IDATA_AnmTyp13Avl "BLN";
BA_ "PacketOrder" SG_ 2154094592 IDATA_AnmTyp13Avl 14;
BA_ "SignalLongName" SG_ 2154094592 IDATA_AnmTyp13Avl "Interior Dimming Animation Type Available : Animation Type 13 Available";
BA_ "VNSigAllNodes" SG_ 2154094592 IDATA_AnmTyp13Avl 1;
BA_ "GenSigSendType" SG_ 2154094592 IDATA_AnmTyp12Avl 10;
BA_ "GenSigSendOnInit" SG_ 2154094592 IDATA_AnmTyp12Avl 1;
BA_ "SignalType" SG_ 2154094592 IDATA_AnmTyp12Avl "BLN";
BA_ "PacketOrder" SG_ 2154094592 IDATA_AnmTyp12Avl 13;
BA_ "SignalLongName" SG_ 2154094592 IDATA_AnmTyp12Avl "Interior Dimming Animation Type Available : Animation Type 12 Available";
BA_ "VNSigAllNodes" SG_ 2154094592 IDATA_AnmTyp12Avl 1;
BA_ "GenSigSendType" SG_ 2154094592 IDATA_AnmTyp11Avl 10;
BA_ "GenSigSendOnInit" SG_ 2154094592 IDATA_AnmTyp11Avl 1;
BA_ "SignalType" SG_ 2154094592 IDATA_AnmTyp11Avl "BLN";
BA_ "PacketOrder" SG_ 2154094592 IDATA_AnmTyp11Avl 12;
BA_ "SignalLongName" SG_ 2154094592 IDATA_AnmTyp11Avl "Interior Dimming Animation Type Available : Animation Type 11 Available";
BA_ "VNSigAllNodes" SG_ 2154094592 IDATA_AnmTyp11Avl 1;
BA_ "GenSigSendType" SG_ 2154094592 IDATA_AnmTyp10Avl 10;
BA_ "GenSigSendOnInit" SG_ 2154094592 IDATA_AnmTyp10Avl 1;
BA_ "SignalType" SG_ 2154094592 IDATA_AnmTyp10Avl "BLN";
BA_ "PacketOrder" SG_ 2154094592 IDATA_AnmTyp10Avl 11;
BA_ "SignalLongName" SG_ 2154094592 IDATA_AnmTyp10Avl "Interior Dimming Animation Type Available : Animation Type 10 Available";
BA_ "VNSigAllNodes" SG_ 2154094592 IDATA_AnmTyp10Avl 1;
BA_ "GenSigSendType" SG_ 2154094592 IDATA_AnmTyp9Avl 10;
BA_ "GenSigSendOnInit" SG_ 2154094592 IDATA_AnmTyp9Avl 1;
BA_ "SignalType" SG_ 2154094592 IDATA_AnmTyp9Avl "BLN";
BA_ "PacketOrder" SG_ 2154094592 IDATA_AnmTyp9Avl 10;
BA_ "SignalLongName" SG_ 2154094592 IDATA_AnmTyp9Avl "Interior Dimming Animation Type Available : Animation Type 9 Available";
BA_ "VNSigAllNodes" SG_ 2154094592 IDATA_AnmTyp9Avl 1;
BA_ "GenSigSendType" SG_ 2154094592 IDATA_AnmTyp8Avl 10;
BA_ "GenSigSendOnInit" SG_ 2154094592 IDATA_AnmTyp8Avl 1;
BA_ "SignalType" SG_ 2154094592 IDATA_AnmTyp8Avl "BLN";
BA_ "PacketOrder" SG_ 2154094592 IDATA_AnmTyp8Avl 9;
BA_ "SignalLongName" SG_ 2154094592 IDATA_AnmTyp8Avl "Interior Dimming Animation Type Available : Animation Type 8 Available";
BA_ "VNSigAllNodes" SG_ 2154094592 IDATA_AnmTyp8Avl 1;
BA_ "GenSigSendType" SG_ 2154094592 IDATA_AnmTyp7Avl 10;
BA_ "GenSigSendOnInit" SG_ 2154094592 IDATA_AnmTyp7Avl 1;
BA_ "SignalType" SG_ 2154094592 IDATA_AnmTyp7Avl "BLN";
BA_ "PacketOrder" SG_ 2154094592 IDATA_AnmTyp7Avl 8;
BA_ "SignalLongName" SG_ 2154094592 IDATA_AnmTyp7Avl "Interior Dimming Animation Type Available : Animation Type 7 Available";
BA_ "VNSigAllNodes" SG_ 2154094592 IDATA_AnmTyp7Avl 1;
BA_ "GenSigSendType" SG_ 2154094592 IDATA_AnmTyp6Avl 10;
BA_ "GenSigSendOnInit" SG_ 2154094592 IDATA_AnmTyp6Avl 1;
BA_ "SignalType" SG_ 2154094592 IDATA_AnmTyp6Avl "BLN";
BA_ "PacketOrder" SG_ 2154094592 IDATA_AnmTyp6Avl 7;
BA_ "SignalLongName" SG_ 2154094592 IDATA_AnmTyp6Avl "Interior Dimming Animation Type Available : Animation Type 6 Available";
BA_ "VNSigAllNodes" SG_ 2154094592 IDATA_AnmTyp6Avl 1;
BA_ "GenSigSendType" SG_ 2154094592 IDATA_AnmTyp5Avl 10;
BA_ "GenSigSendOnInit" SG_ 2154094592 IDATA_AnmTyp5Avl 1;
BA_ "SignalType" SG_ 2154094592 IDATA_AnmTyp5Avl "BLN";
BA_ "PacketOrder" SG_ 2154094592 IDATA_AnmTyp5Avl 6;
BA_ "SignalLongName" SG_ 2154094592 IDATA_AnmTyp5Avl "Interior Dimming Animation Type Available : Animation Type 5 Available";
BA_ "VNSigAllNodes" SG_ 2154094592 IDATA_AnmTyp5Avl 1;
BA_ "GenSigSendType" SG_ 2154094592 IDATA_AnmTyp4Avl 10;
BA_ "GenSigSendOnInit" SG_ 2154094592 IDATA_AnmTyp4Avl 1;
BA_ "SignalType" SG_ 2154094592 IDATA_AnmTyp4Avl "BLN";
BA_ "PacketOrder" SG_ 2154094592 IDATA_AnmTyp4Avl 5;
BA_ "SignalLongName" SG_ 2154094592 IDATA_AnmTyp4Avl "Interior Dimming Animation Type Available : Animation Type 4 Available";
BA_ "VNSigAllNodes" SG_ 2154094592 IDATA_AnmTyp4Avl 1;
BA_ "GenSigSendType" SG_ 2154094592 IDATA_AnmTyp3Avl 10;
BA_ "GenSigSendOnInit" SG_ 2154094592 IDATA_AnmTyp3Avl 1;
BA_ "SignalType" SG_ 2154094592 IDATA_AnmTyp3Avl "BLN";
BA_ "PacketOrder" SG_ 2154094592 IDATA_AnmTyp3Avl 4;
BA_ "SignalLongName" SG_ 2154094592 IDATA_AnmTyp3Avl "Interior Dimming Animation Type Available : Animation Type 3 Available";
BA_ "VNSigAllNodes" SG_ 2154094592 IDATA_AnmTyp3Avl 1;
BA_ "GenSigSendType" SG_ 2154094592 IDATA_AnmTyp2Avl 10;
BA_ "GenSigSendOnInit" SG_ 2154094592 IDATA_AnmTyp2Avl 1;
BA_ "SignalType" SG_ 2154094592 IDATA_AnmTyp2Avl "BLN";
BA_ "PacketOrder" SG_ 2154094592 IDATA_AnmTyp2Avl 3;
BA_ "SignalLongName" SG_ 2154094592 IDATA_AnmTyp2Avl "Interior Dimming Animation Type Available : Animation Type 2 Available";
BA_ "VNSigAllNodes" SG_ 2154094592 IDATA_AnmTyp2Avl 1;
BA_ "GenSigSendType" SG_ 2154094592 IDATA_AnmTyp1Avl 10;
BA_ "GenSigSendOnInit" SG_ 2154094592 IDATA_AnmTyp1Avl 1;
BA_ "SignalType" SG_ 2154094592 IDATA_AnmTyp1Avl "BLN";
BA_ "PacketOrder" SG_ 2154094592 IDATA_AnmTyp1Avl 2;
BA_ "SignalLongName" SG_ 2154094592 IDATA_AnmTyp1Avl "Interior Dimming Animation Type Available : Animation Type 1 Available";
BA_ "VNSigAllNodes" SG_ 2154094592 IDATA_AnmTyp1Avl 1;
BA_ "GenSigSendType" SG_ 2154094592 IDATA_OffAvl 10;
BA_ "GenSigSendOnInit" SG_ 2154094592 IDATA_OffAvl 1;
BA_ "SignalType" SG_ 2154094592 IDATA_OffAvl "BLN";
BA_ "PacketOrder" SG_ 2154094592 IDATA_OffAvl 1;
BA_ "SignalLongName" SG_ 2154094592 IDATA_OffAvl "Interior Dimming Animation Type Available : Off Available";
BA_ "VNSigAllNodes" SG_ 2154094592 IDATA_OffAvl 1;
BA_ "GenSigSendType" SG_ 2154094592 AdjPdlMotInhbtd 10;
BA_ "SignalType" SG_ 2154094592 AdjPdlMotInhbtd "BLN";
BA_ "SignalLongName" SG_ 2154094592 AdjPdlMotInhbtd "Adjustable Pedal Motion Inhibited";
BA_ "VNSigAllNodes" SG_ 2154094592 AdjPdlMotInhbtd 1;
BA_REL_ "GenSigRxStartValue" BU_SG_REL_ BCM_LS SG_ 2151063552 InftnOprAlwd "False";
BA_REL_ "GenSigSuprvResp" BU_SG_REL_ BCM_LS SG_ 2151063552 InftnOprAlwd 1;
BA_REL_ "GenSigSuprvResp" BU_SG_REL_ MCTM_LS SG_ 2151063552 InftnOprAlwd 1;
BA_REL_ "GenSigSuprvResp" BU_SG_REL_ BCM_LS SG_ 2151063552 ValetMdAct 1;
BA_REL_ "GenSigSuprvResp" BU_SG_REL_ BCM_LS SG_ 2151063552 ValetMdAct 1;
BA_REL_ "GenSigSuprvResp" BU_SG_REL_ BCM_LS SG_ 2151063552 ValetMdAct 1;
BA_REL_ "GenSigSuprvResp" BU_SG_REL_ BCM_LS SG_ 2151063552 ValetMdAct 1;
BA_REL_ "GenSigRxStartValue" BU_SG_REL_ BCM_LS SG_ 2151063552 ValetMdAct "False";
BA_REL_ "GenSigSuprvResp" BU_SG_REL_ BCM_LS SG_ 2151063552 ValetMdAct 1;
BA_REL_ "GenSigSuprvResp" BU_SG_REL_ BCM_LS SG_ 2151063552 ValetMdAct 1;
BA_REL_ "GenSigSuprvResp" BU_SG_REL_ UPA_LS SG_ 2151718912 ChmAct 1;
BA_REL_ "GenSigRxStartValue" BU_SG_REL_ TIM_LS SG_ 2151718912 ChmAct "0";
BA_REL_ "GenSigRxStartValue" BU_SG_REL_ SDM_PR_LS SG_ 2151718912 ChmAct "0";
BA_REL_ "GenSigSuprvResp" BU_SG_REL_ SDM_PR_LS SG_ 2151718912 ChmAct 1;
BA_REL_ "GenSigSuprvResp" BU_SG_REL_ MCTM_LS SG_ 2151718912 ChmAct 1;
BA_REL_ "GenSigRxStartValue" BU_SG_REL_ BCM_LS SG_ 2151718912 ChmAct "False";
BA_REL_ "GenSigSuprvResp" BU_SG_REL_ BCM_LS SG_ 2151718912 ChmAct 1;
BA_REL_ "GenSigSuprvResp" BU_SG_REL_ BCM_LS SG_ 2151718912 ChmAct 1;
BA_REL_ "GenSigSuprvResp" BU_SG_REL_ BCM_LS SG_ 2155479040 DrvStyPerfMdCsStReq 1;
BA_REL_ "GenSigSuprvResp" BU_SG_REL_ BCM_LS SG_ 2155479040 PsngStPerfMdCsStReq 1;
BA_REL_ "GenSigSuprvResp" BU_SG_REL_ BCM_LS SG_ 2155479040 DrvrStPerfMdCsStReq 1;
BA_REL_ "GenSigSuprvResp" BU_SG_REL_ BCM_LS SG_ 2155479040 ACCPerfMdCsStReq 1;
BA_REL_ "GenSigSuprvResp" BU_SG_REL_ BCM_LS SG_ 2155479040 PedFrndlyAlrtCsStReq 1;
BA_REL_ "GenSigSuprvResp" BU_SG_REL_ VICM_LS SG_ 2155479040 RstrCustFctrDef 1;
BA_REL_ "GenSigSuprvResp" BU_SG_REL_ BCM_LS SG_ 2155421696 PsvEntAprchDrctn 1;
BA_REL_ "GenSigSuprvResp" BU_SG_REL_ BCM_LS SG_ 2155421696 PsvEntApprchDtcd 1;
BA_REL_ "GenSigSuprvResp" BU_SG_REL_ BCM_LS SG_ 2155421696 PsvEntApprchCnfgReq 1;
BA_REL_ "GenSigSuprvResp" BU_SG_REL_ BCM_LS SG_ 2155421696 PsvEntChlng 1;
BA_REL_ "GenSigSuprvResp" BU_SG_REL_ PEPS_LS SG_ 2155413504 PsvLckngReqd 1;
BA_REL_ "GenSigSuprvResp" BU_SG_REL_ PEPS_LS SG_ 2155413504 PsvApprchVehId 1;
BA_REL_ "GenSigRxStartValue" BU_SG_REL_ MCTM_LS SG_ 2159026176 ODD_InvldData "0";
BA_REL_ "GenSigRxStartValue" BU_SG_REL_ MCTM_LS SG_ 2159026176 ODD_FUCID "0";
BA_REL_ "GenSigRxStartValue" BU_SG_REL_ MCTM_LS SG_ 2159026176 ODD_DataVal "0";
BA_REL_ "GenSigRxStartValue" BU_SG_REL_ MCTM_LS SG_ 2159026176 ODD_DataType "0";
BA_REL_ "GenSigRxStartValue" BU_SG_REL_ MCTM_LS SG_ 2159026176 ODD_DataId "0";
BA_REL_ "GenSigRxStartValue" BU_SG_REL_ MCTM_LS SG_ 2158936064 ODIEDD_Data18Value "0";
BA_REL_ "GenSigRxStartValue" BU_SG_REL_ MCTM_LS SG_ 2158936064 ODIEDD_Data17Value "0";
BA_REL_ "GenSigRxStartValue" BU_SG_REL_ MCTM_LS SG_ 2158936064 ODIEDD_Data16Value "0";
BA_REL_ "GenSigRxStartValue" BU_SG_REL_ MCTM_LS SG_ 2158936064 ODIEDD_Data15Value "0";
BA_REL_ "GenSigRxStartValue" BU_SG_REL_ MCTM_LS SG_ 2158936064 ODIEDD_Data14Value "0";
BA_REL_ "GenSigRxStartValue" BU_SG_REL_ MCTM_LS SG_ 2158936064 ODIEDD_Data13Value "0";
BA_REL_ "GenSigRxStartValue" BU_SG_REL_ MCTM_LS SG_ 2158936064 ODIEDD_Data12Value "0";
BA_REL_ "GenSigRxStartValue" BU_SG_REL_ MCTM_LS SG_ 2158936064 ODIEDD_Data11Value "0";
BA_REL_ "GenSigRxStartValue" BU_SG_REL_ MCTM_LS SG_ 2158936064 ODIEDD_Data10Value "0";
BA_REL_ "GenSigRxStartValue" BU_SG_REL_ MCTM_LS SG_ 2158936064 ODIEDD_Data9Value "0";
BA_REL_ "GenSigRxStartValue" BU_SG_REL_ MCTM_LS SG_ 2158936064 ODIEDD_Data8Value "0";
BA_REL_ "GenSigRxStartValue" BU_SG_REL_ MCTM_LS SG_ 2158936064 ODIEDD_Data7Value "0";
BA_REL_ "GenSigRxStartValue" BU_SG_REL_ MCTM_LS SG_ 2158936064 ODIEDD_Data6Value "0";
BA_REL_ "GenSigRxStartValue" BU_SG_REL_ MCTM_LS SG_ 2158936064 ODIEDD_Data5Value "0";
BA_REL_ "GenSigRxStartValue" BU_SG_REL_ MCTM_LS SG_ 2158936064 ODIEDD_Data4Value "0";
BA_REL_ "GenSigRxStartValue" BU_SG_REL_ MCTM_LS SG_ 2158936064 ODIEDD_Data3Value "0";
BA_REL_ "GenSigRxStartValue" BU_SG_REL_ MCTM_LS SG_ 2158936064 ODIEDD_Data2Value "0";
BA_REL_ "GenSigRxStartValue" BU_SG_REL_ MCTM_LS SG_ 2158936064 ODIEDD_Data1Value "0";
BA_REL_ "GenSigRxStartValue" BU_SG_REL_ MCTM_LS SG_ 2158936064 ODIEDD_FUCID "0";
BA_REL_ "GenSigSuprvResp" BU_SG_REL_ EOCM2cp_K2_LS SG_ 2158845952 ODIAC_FUCID 1;
BA_REL_ "GenSigSuprvResp" BU_SG_REL_ UPA_LS SG_ 2158845952 ODIAC_FUCID 1;
BA_REL_ "GenSigSuprvResp" BU_SG_REL_ EOCM2cp_K2_LS SG_ 2158845952 ODIAC_DspMID 1;
BA_REL_ "GenSigSuprvResp" BU_SG_REL_ UPA_LS SG_ 2158845952 ODIAC_DspMID 1;
BA_REL_ "GenSigSuprvResp" BU_SG_REL_ EOCM2cp_K2_LS SG_ 2158845952 ODIAC_DaTy 1;
BA_REL_ "GenSigSuprvResp" BU_SG_REL_ UPA_LS SG_ 2158845952 ODIAC_DaTy 1;
BA_REL_ "GenSigSuprvResp" BU_SG_REL_ EOCM2cp_K2_LS SG_ 2158845952 ODIAC_ActnVal 1;
BA_REL_ "GenSigSuprvResp" BU_SG_REL_ UPA_LS SG_ 2158845952 ODIAC_ActnVal 1;
BA_REL_ "GenSigSuprvResp" BU_SG_REL_ EOCM2cp_K2_LS SG_ 2158845952 ODIAC_ActnID 1;
BA_REL_ "GenSigSuprvResp" BU_SG_REL_ UPA_LS SG_ 2158845952 ODIAC_ActnID 1;
BA_REL_ "GenSigSuprvResp" BU_SG_REL_ UPA_LS SG_ 2151366656 PrkBrkSwAtv 1;
BA_REL_ "GenSigSuprvResp" BU_SG_REL_ UPA_LS SG_ 2149842944 IMUProtLonAcc 1;
BA_REL_ "GenSigSuprvResp" BU_SG_REL_ SDM_PR_LS SG_ 2149842944 VehStabEnhmntStat 1;
BA_REL_ "GenSigSuprvResp" BU_SG_REL_ SDM_PR_LS SG_ 2149842944 StrWhAng 1;
BA_REL_ "GenSigVDAFailComment" BU_SG_REL_ UPA_LS SG_ 2149842944 StrWhAng "StWhAnVDA";
BA_REL_ "GenSigVDAFailResp" BU_SG_REL_ UPA_LS SG_ 2149842944 StrWhAng 1;
BA_REL_ "GenSigSuprvResp" BU_SG_REL_ UPA_LS SG_ 2149842944 StrWhAng 1;
BA_REL_ "GenSigSuprvResp" BU_SG_REL_ BCM_LS SG_ 2151940096 EstIntHorzDshSrfTmp 1;
BA_REL_ "GenSigSuprvResp" BU_SG_REL_ BCM_LS SG_ 2152464384 SrvcLnKpAstSysIO 1;
BA_REL_ "GenSigSuprvResp" BU_SG_REL_ BCM_LS SG_ 2152464384 LKAIC_AdbWngLn 1;
BA_REL_ "GenSigSuprvResp" BU_SG_REL_ BCM_LS SG_ 2152464384 LKAIC_Ind2 1;
BA_REL_ "GenSigSuprvResp" BU_SG_REL_ BCM_LS SG_ 2152464384 LKAIC_Ind1 1;
BA_REL_ "GenSigSuprvResp" BU_SG_REL_ BCM_LS SG_ 2152464384 LKAIC_IndReq 1;
BA_REL_ "GenSigSuprvResp" BU_SG_REL_ BCM_LS SG_ 2152464384 SrvcLaneDepWrnSysIO 1;
BA_REL_ "GenSigSuprvResp" BU_SG_REL_ BCM_LS SG_ 2152464384 LDWIC_LnDepWAWLn 1;
BA_REL_ "GenSigSuprvResp" BU_SG_REL_ BCM_LS SG_ 2152464384 LDWIC_Ind2 1;
BA_REL_ "GenSigSuprvResp" BU_SG_REL_ BCM_LS SG_ 2152464384 LDWIC_Ind1 1;
BA_REL_ "GenSigSuprvResp" BU_SG_REL_ BCM_LS SG_ 2152464384 LDWIC_IndReq 1;
BA_REL_ "GenSigSuprvResp" BU_SG_REL_ ECC_LS SG_ 2154962944 PassHCSMInd3 1;
BA_REL_ "GenSigSuprvResp" BU_SG_REL_ ECC_LS SG_ 2154962944 PassHCSMInd2 1;
BA_REL_ "GenSigSuprvResp" BU_SG_REL_ ECC_LS SG_ 2154962944 PassHCSMInd1 1;
BA_REL_ "GenSigSuprvResp" BU_SG_REL_ ECC_LS SG_ 2154962944 PassHCSMIndReq 1;
BA_REL_ "GenSigSuprvResp" BU_SG_REL_ ECC_LS SG_ 2154962944 PassHCSLSeatLev5 1;
BA_REL_ "GenSigSuprvResp" BU_SG_REL_ ECC_LS SG_ 2154962944 PassHCSLSeatLev4 1;
BA_REL_ "GenSigSuprvResp" BU_SG_REL_ ECC_LS SG_ 2154962944 PassHCSLSeatLev3 1;
BA_REL_ "GenSigSuprvResp" BU_SG_REL_ ECC_LS SG_ 2154962944 PassHCSLSeatLev2 1;
BA_REL_ "GenSigSuprvResp" BU_SG_REL_ ECC_LS SG_ 2154962944 PassHCSLSeatLev1 1;
BA_REL_ "GenSigSuprvResp" BU_SG_REL_ ECC_LS SG_ 2154962944 PassHCSLIndReq 1;
BA_REL_ "GenSigSuprvResp" BU_SG_REL_ ECC_LS SG_ 2154962944 DrvHCSMInd1 1;
BA_REL_ "GenSigSuprvResp" BU_SG_REL_ ECC_LS SG_ 2154962944 DrvHCSMIndReq 1;
BA_REL_ "GenSigSuprvResp" BU_SG_REL_ ECC_LS SG_ 2154962944 DrvHCSMInd3 1;
BA_REL_ "GenSigSuprvResp" BU_SG_REL_ ECC_LS SG_ 2154962944 DrvHCSMInd2 1;
BA_REL_ "GenSigSuprvResp" BU_SG_REL_ ECC_LS SG_ 2154962944 DrvHCSLSeatLev5 1;
BA_REL_ "GenSigSuprvResp" BU_SG_REL_ ECC_LS SG_ 2154962944 DrvHCSLSeatLev4 1;
BA_REL_ "GenSigSuprvResp" BU_SG_REL_ ECC_LS SG_ 2154962944 DrvHCSLSeatLev3 1;
BA_REL_ "GenSigSuprvResp" BU_SG_REL_ ECC_LS SG_ 2154962944 DrvHCSLSeatLev2 1;
BA_REL_ "GenSigSuprvResp" BU_SG_REL_ ECC_LS SG_ 2154962944 DrvHCSLSeatLev1 1;
BA_REL_ "GenSigSuprvResp" BU_SG_REL_ ECC_LS SG_ 2154962944 DrvHCSLIndReq 1;
BA_REL_ "GenSigSuprvResp" BU_SG_REL_ VICM_LS SG_ 2154643456 HtrCoreInltClntTmpCalc 1;
BA_REL_ "GenSigSuprvResp" BU_SG_REL_ VICM_LS SG_ 2154643456 CCClntCrcFlwRtReq 1;
BA_REL_ "GenSigSuprvResp" BU_SG_REL_ EOCM2cp_K2_LS SG_ 2154905600 DrvSeatPrsMemID 1;
BA_REL_ "GenSigSuprvResp" BU_SG_REL_ EOCM2cp_K2_LS SG_ 2154905600 DrId 1;
BA_REL_ "GenSigSuprvResp" BU_SG_REL_ VICM_LS SG_ 2154954752 ClmtHtPwrRqd 1;
BA_REL_ "GenSigVDAFailComment" BU_SG_REL_ UPA_LS SG_ 2149752832 ElecPrkBrkStat "Park Brake Virtual Device Availability";
BA_REL_ "GenSigVDAFailResp" BU_SG_REL_ UPA_LS SG_ 2149752832 ElecPrkBrkStat 1;
BA_REL_ "GenSigSuprvResp" BU_SG_REL_ UPA_LS SG_ 2149752832 ElecPrkBrkStat 1;
BA_REL_ "GenSigSuprvResp" BU_SG_REL_ SDM_PR_LS SG_ 2149752832 ABSAtv 1;
BA_REL_ "GenSigSuprvResp" BU_SG_REL_ SDM_PR_LS SG_ 2149752832 BrkSysVDA 1;
BA_REL_ "GenSigSuprvResp" BU_SG_REL_ EOCM2cp_K2_LS SG_ 2158911488 ODDMC_ReqType 1;
BA_REL_ "GenSigSuprvResp" BU_SG_REL_ UPA_LS SG_ 2158911488 ODDMC_ReqType 1;
BA_REL_ "GenSigSuprvResp" BU_SG_REL_ EOCM2cp_K2_LS SG_ 2158911488 ODDMC_DispMID 1;
BA_REL_ "GenSigSuprvResp" BU_SG_REL_ UPA_LS SG_ 2158911488 ODDMC_DispMID 1;
BA_REL_ "GenSigSuprvResp" BU_SG_REL_ EOCM2cp_K2_LS SG_ 2158911488 ODDMC_DataID2Vld 1;
BA_REL_ "GenSigSuprvResp" BU_SG_REL_ UPA_LS SG_ 2158911488 ODDMC_DataID2Vld 1;
BA_REL_ "GenSigSuprvResp" BU_SG_REL_ EOCM2cp_K2_LS SG_ 2158911488 ODDMC_DataID2 1;
BA_REL_ "GenSigSuprvResp" BU_SG_REL_ UPA_LS SG_ 2158911488 ODDMC_DataID2 1;
BA_REL_ "GenSigSuprvResp" BU_SG_REL_ EOCM2cp_K2_LS SG_ 2158911488 ODDMC_DataID3Vld 1;
BA_REL_ "GenSigSuprvResp" BU_SG_REL_ UPA_LS SG_ 2158911488 ODDMC_DataID3Vld 1;
BA_REL_ "GenSigSuprvResp" BU_SG_REL_ EOCM2cp_K2_LS SG_ 2158911488 ODDMC_DataID3 1;
BA_REL_ "GenSigSuprvResp" BU_SG_REL_ UPA_LS SG_ 2158911488 ODDMC_DataID3 1;
BA_REL_ "GenSigSuprvResp" BU_SG_REL_ EOCM2cp_K2_LS SG_ 2158911488 ODDMC_DataID1 1;
BA_REL_ "GenSigSuprvResp" BU_SG_REL_ UPA_LS SG_ 2158911488 ODDMC_DataID1 1;
BA_REL_ "GenSigSuprvResp" BU_SG_REL_ EOCM2cp_K2_LS SG_ 2158911488 ODDMC_DataID4Vld 1;
BA_REL_ "GenSigSuprvResp" BU_SG_REL_ UPA_LS SG_ 2158911488 ODDMC_DataID4Vld 1;
BA_REL_ "GenSigSuprvResp" BU_SG_REL_ EOCM2cp_K2_LS SG_ 2158911488 ODDMC_DataID4 1;
BA_REL_ "GenSigSuprvResp" BU_SG_REL_ UPA_LS SG_ 2158911488 ODDMC_DataID4 1;
BA_REL_ "GenSigSuprvResp" BU_SG_REL_ EOCM2cp_K2_LS SG_ 2158911488 ODDMC_DataID5Vld 1;
BA_REL_ "GenSigSuprvResp" BU_SG_REL_ UPA_LS SG_ 2158911488 ODDMC_DataID5Vld 1;
BA_REL_ "GenSigSuprvResp" BU_SG_REL_ EOCM2cp_K2_LS SG_ 2158911488 ODDMC_DataID5 1;
BA_REL_ "GenSigSuprvResp" BU_SG_REL_ UPA_LS SG_ 2158911488 ODDMC_DataID5 1;
BA_REL_ "GenSigSuprvResp" BU_SG_REL_ EOCM2cp_K2_LS SG_ 2158911488 ODDMC_FUCID 1;
BA_REL_ "GenSigSuprvResp" BU_SG_REL_ UPA_LS SG_ 2158911488 ODDMC_FUCID 1;
BA_REL_ "GenSigSuprvResp" BU_SG_REL_ EOCM2cp_K2_LS SG_ 2158919680 ODDMI_ReqType 1;
BA_REL_ "GenSigSuprvResp" BU_SG_REL_ UPA_LS SG_ 2158919680 ODDMI_ReqType 1;
BA_REL_ "GenSigSuprvResp" BU_SG_REL_ EOCM2cp_K2_LS SG_ 2158919680 ODDMI_FUCID 1;
BA_REL_ "GenSigSuprvResp" BU_SG_REL_ UPA_LS SG_ 2158919680 ODDMI_FUCID 1;
BA_REL_ "GenSigSuprvResp" BU_SG_REL_ EOCM2cp_K2_LS SG_ 2158919680 ODDMI_DispMID 1;
BA_REL_ "GenSigSuprvResp" BU_SG_REL_ UPA_LS SG_ 2158919680 ODDMI_DispMID 1;
BA_REL_ "GenSigSuprvResp" BU_SG_REL_ EOCM2cp_K2_LS SG_ 2158919680 ODDMI_DataID2Vld 1;
BA_REL_ "GenSigSuprvResp" BU_SG_REL_ UPA_LS SG_ 2158919680 ODDMI_DataID2Vld 1;
BA_REL_ "GenSigSuprvResp" BU_SG_REL_ EOCM2cp_K2_LS SG_ 2158919680 ODDMI_DataID2 1;
BA_REL_ "GenSigSuprvResp" BU_SG_REL_ UPA_LS SG_ 2158919680 ODDMI_DataID2 1;
BA_REL_ "GenSigSuprvResp" BU_SG_REL_ EOCM2cp_K2_LS SG_ 2158919680 ODDMI_DataID3Vld 1;
BA_REL_ "GenSigSuprvResp" BU_SG_REL_ UPA_LS SG_ 2158919680 ODDMI_DataID3Vld 1;
BA_REL_ "GenSigSuprvResp" BU_SG_REL_ EOCM2cp_K2_LS SG_ 2158919680 ODDMI_DataID3 1;
BA_REL_ "GenSigSuprvResp" BU_SG_REL_ UPA_LS SG_ 2158919680 ODDMI_DataID3 1;
BA_REL_ "GenSigSuprvResp" BU_SG_REL_ EOCM2cp_K2_LS SG_ 2158919680 ODDMI_DataID1 1;
BA_REL_ "GenSigSuprvResp" BU_SG_REL_ UPA_LS SG_ 2158919680 ODDMI_DataID1 1;
BA_REL_ "GenSigSuprvResp" BU_SG_REL_ EOCM2cp_K2_LS SG_ 2158919680 ODDMI_DataID4Vld 1;
BA_REL_ "GenSigSuprvResp" BU_SG_REL_ UPA_LS SG_ 2158919680 ODDMI_DataID4Vld 1;
BA_REL_ "GenSigSuprvResp" BU_SG_REL_ EOCM2cp_K2_LS SG_ 2158919680 ODDMI_DataID4 1;
BA_REL_ "GenSigSuprvResp" BU_SG_REL_ UPA_LS SG_ 2158919680 ODDMI_DataID4 1;
BA_REL_ "GenSigSuprvResp" BU_SG_REL_ EOCM2cp_K2_LS SG_ 2158919680 ODDMI_DataID5Vld 1;
BA_REL_ "GenSigSuprvResp" BU_SG_REL_ UPA_LS SG_ 2158919680 ODDMI_DataID5Vld 1;
BA_REL_ "GenSigSuprvResp" BU_SG_REL_ EOCM2cp_K2_LS SG_ 2158919680 ODDMI_DataID5 1;
BA_REL_ "GenSigSuprvResp" BU_SG_REL_ UPA_LS SG_ 2158919680 ODDMI_DataID5 1;
BA_REL_ "GenSigSuprvResp" BU_SG_REL_ MCTM_LS SG_ 2151825408 OtsAirTmp 1;
BA_REL_ "GenSigVBitResp" BU_SG_REL_ EOCM2cp_K2_LS SG_ 2151825408 OtsAirTmp 1;
BA_REL_ "GenSigSuprvResp" BU_SG_REL_ EOCM2cp_K2_LS SG_ 2151825408 OtsAirTmp 1;
BA_REL_ "GenSigVBitResp" BU_SG_REL_ EOCM2cp_K1_LS SG_ 2151825408 OtsAirTmp 1;
BA_REL_ "GenSigSuprvResp" BU_SG_REL_ EOCM2cp_K1_LS SG_ 2151825408 OtsAirTmp 1;
BA_REL_ "GenSigVBitResp" BU_SG_REL_ UPA_LS SG_ 2151825408 OtsAirTmp 1;
BA_REL_ "GenSigSuprvResp" BU_SG_REL_ UPA_LS SG_ 2151825408 OtsAirTmp 1;
BA_REL_ "GenSigVBitResp" BU_SG_REL_ MCTM_LS SG_ 2151825408 OtsAirTmpCrVal 1;
BA_REL_ "GenSigSuprvResp" BU_SG_REL_ MCTM_LS SG_ 2151825408 OtsAirTmpCrVal 1;
BA_REL_ "GenSigVBitResp" BU_SG_REL_ EOCM2cp_K2_LS SG_ 2151825408 OtsAirTmpCrVal 1;
BA_REL_ "GenSigSuprvResp" BU_SG_REL_ EOCM2cp_K2_LS SG_ 2151825408 OtsAirTmpCrVal 1;
BA_REL_ "GenSigVBitResp" BU_SG_REL_ EOCM2cp_K1_LS SG_ 2151825408 OtsAirTmpCrVal 1;
BA_REL_ "GenSigSuprvResp" BU_SG_REL_ EOCM2cp_K1_LS SG_ 2151825408 OtsAirTmpCrVal 1;
BA_REL_ "GenSigSuprvResp" BU_SG_REL_ SDM_PR_LS SG_ 2151825408 OtsAirTmpCrVal 1;
BA_REL_ "GenSigVBitResp" BU_SG_REL_ BCM_LS SG_ 2151825408 OtsAirTmpCrVal 1;
BA_REL_ "GenSigSuprvResp" BU_SG_REL_ BCM_LS SG_ 2151825408 OtsAirTmpCrVal 1;
BA_REL_ "GenSigVBitResp" BU_SG_REL_ BCM_LS SG_ 2151825408 OtsAirTmpCrVal 1;
BA_REL_ "GenSigSuprvResp" BU_SG_REL_ BCM_LS SG_ 2151825408 OtsAirTmpCrVal 1;
BA_REL_ "GenSigSuprvResp" BU_SG_REL_ UPA_LS SG_ 2151825408 OtsAirTmpCrVal 1;
BA_REL_ "GenSigSuprvResp" BU_SG_REL_ UPA_LS SG_ 2151170048 RrEndCrrStat 1;
BA_REL_ "GenSigRxStartValue" BU_SG_REL_ BCM_LS SG_ 2151170048 RrEndCrrStat "0";
BA_REL_ "GenSigRxStartValue" BU_SG_REL_ BCM_LS SG_ 2151170048 DisRrPrmryLmps "False";
BA_REL_ "GenSigRxStartValue" BU_SG_REL_ BCM_LS SG_ 2151170048 TrlrRtTrInLtFld "False";
BA_REL_ "GenSigRxStartValue" BU_SG_REL_ BCM_LS SG_ 2151170048 TrlLfTrInLtFld "False";
BA_REL_ "GenSigSuprvResp" BU_SG_REL_ UPA_LS SG_ 2151170048 TrlrHtchSwAtv 1;
BA_REL_ "GenSigRxStartValue" BU_SG_REL_ BCM_LS SG_ 2151170048 TrlrHtchSwAtv "False";
BA_REL_ "GenSigSuprvResp" BU_SG_REL_ BCM_LS SG_ 2151170048 TrlrHtchSwAtv 1;
BA_REL_ "GenSigRxStartValue" BU_SG_REL_ BCM_LS SG_ 2151170048 RtSecTrnIndFld "False";
BA_REL_ "GenSigRxStartValue" BU_SG_REL_ BCM_LS SG_ 2151170048 TrlrFgLtPrs "False";
BA_REL_ "GenSigRxStartValue" BU_SG_REL_ BCM_LS SG_ 2151170048 LftSecTrnIndFld "False";
BA_REL_ "GenSigSuprvResp" BU_SG_REL_ EOCM2cp_K2_LS SG_ 2151841792 WSWprAct 1;
BA_REL_ "GenSigSuprvResp" BU_SG_REL_ EOCM2cp_K2_LS SG_ 2151841792 RnSnsOffIO 1;
BA_REL_ "GenSigSuprvResp" BU_SG_REL_ EOCM2cp_K2_LS SG_ 2151841792 RnSnsActIO 1;
BA_REL_ "GenSigSuprvResp" BU_SG_REL_ EOCM2cp_K2_LS SG_ 2151841792 TurnWprIntIO 1;
VAL_ 2153955328 EngOffTmExtRngV 1 "Invalid" 0 "Valid" ;
VAL_ 2153955328 ElpsdTimeCntRstOcc 1 "true" 0 "false" ;
VAL_ 2151063552 TrfRdsdInfCsStReq 7 "Reserved5" 6 "Reserved4" 5 "Reserved3" 4 "Reserved2" 3 "Reserved1" 2 "On" 1 "Off" 0 "No Action" ;
VAL_ 2151063552 IntrStopAlrtCsSetReq 7 "Reserved4" 6 "Reserved3" 5 "Reserved2" 4 "Reserved1" 3 "Alert and Brake" 2 "Alert " 1 "Off" 0 "No Action" ;
VAL_ 2151063552 CntdVehBrAltCsStReq 7 "Reserved5" 6 "Reserved4" 5 "Reserved3" 4 "Reserved2" 3 "Reserved1" 2 "On" 1 "Off" 0 "No Action" ;
VAL_ 2151063552 ICSTS_TchPrxmty 2 "Touch" 1 "Near" 0 "Far" ;
VAL_ 2151063552 TrgdVidRecSwAct 1 "true" 0 "false" ;
VAL_ 2151063552 RrPedDetCstStReq 7 "Reserved3" 6 "Reserved2" 5 "Reserved1" 4 "Alert and Brake" 3 "Alert" 2 "On" 1 "Off" 0 "No Action" ;
VAL_ 2151063552 RRStStatDispAct 1 "true" 0 "false" ;
VAL_ 2151063552 LRStStatDispAct 1 "true" 0 "false" ;
VAL_ 2151063552 CamVideoICSDispAct 1 "true" 0 "false" ;
VAL_ 2151063552 Frnt360CamSwAct 1 "true" 0 "false" ;
VAL_ 2151063552 InftnOprAlwd 1 "true" 0 "false" ;
VAL_ 2151063552 ValetMdAct 1 "true" 0 "false" ;
VAL_ 2157985792 FobProgEvntRqd 1 "true" 0 "false" ;
VAL_ 2151284736 PrkAstOprtrDsrdStat_1D0 0 "Off" 1 "On" 2 "Tow Bar Attached" ;
VAL_ 2151284736 TnDrvPrkAstOffUnbIO 1 "true" 0 "false" ;
VAL_ 2151284736 PrkAstFld 1 "true" 0 "false" ;
VAL_ 2151284736 PrkAstSnsDistrbdIO 1 "true" 0 "false" ;
VAL_ 2151284736 PrkAsstDisablIO 1 "true" 0 "false" ;
VAL_ 2151284736 PrkAstSnrsBlk 1 "true" 0 "false" ;
VAL_ 2151284736 PrkAsstClnPrkAstIO 1 "true" 0 "false" ;
VAL_ 2151718912 ChmVolSt 0 "Normal" 1 "Loud" ;
VAL_ 2151718912 ChmAct 1 "true" 0 "false" ;
VAL_ 2155479040 DrvStyPerfMdCsStReq 7 "Performance Mode 7" 6 "Performance Mode 6" 5 "Performance Mode 5" 4 "Performance Mode 4" 3 "Performance Mode 3" 2 "Performance Mode 2" 1 "Performance Mode 1" 0 "No Action" ;
VAL_ 2155479040 PsngStPerfMdCsStReq 7 "Auto" 6 "Performance Mode 6" 5 "Performance Mode 5" 4 "Performance Mode 4" 3 "Performance Mode 3" 2 "Performance Mode 2" 1 "Performance Mode 1" 0 "No Action" ;
VAL_ 2155479040 DrvrStPerfMdCsStReq 7 "Auto" 6 "Performance Mode 6" 5 "Performance Mode 5" 4 "Performance Mode 4" 3 "Performance Mode 3" 2 "Performance Mode 2" 1 "Performance Mode 1" 0 "No Action" ;
VAL_ 2155479040 ACCPerfMdCsStReq 7 "Auto" 6 "Performance Mode 6" 5 "Performance Mode 5" 4 "Performance Mode 4" 3 "Performance Mode 3" 2 "Performance Mode 2" 1 "Performance Mode 1" 0 "No Action" ;
VAL_ 2155479040 ElvtdIdlCstStReq 0 "No Action" 1 "Off" 2 "On" ;
VAL_ 2155479040 PedFrndlyAlrtCsStReq 0 "No Action" 1 "Off" 2 "On" ;
VAL_ 2155479040 SndPerfMdCsStRq 0 "No Action" 1 "Performance Mode 1" 2 "Performance Mode 2" 3 "Performance Mode 3" 4 "Performance Mode 4" 5 "Performance Mode 5" 6 "Performance Mode 6" 7 "Auto" ;
VAL_ 2155479040 DispPerfMdCsStRq 0 "No Action" 1 "Performance Mode 1" 2 "Performance Mode 2" 3 "Performance Mode 3" 4 "Performance Mode 4" 5 "Performance Mode 5" 6 "Performance Mode 6" 7 "Auto" ;
VAL_ 2155479040 SusCustStngReq 4 "Performance Mode 4" 3 "Performance Mode 3" 2 "Performance Mode 2" 1 "Performance Mode 1" 0 "No Action" 7 "Auto" 6 "Performance Mode 6" 5 "Performance Mode 5" ;
VAL_ 2155479040 StrCustStngReq 4 "Performance Mode 4" 3 "Performance Mode 3" 2 "Performance Mode 2" 1 "Performance Mode 1" 0 "No Action" 7 "Auto" 6 "Performance Mode 6" 5 "Performance Mode 5" ;
VAL_ 2155479040 RstrCustFctrDef 1 "Restore Defaults" 0 "No Action" ;
VAL_ 2155479040 DrvlnCustStngReq 4 "Performance Mode 4" 3 "Performance Mode 3" 2 "Performance Mode 2" 1 "Performance Mode 1" 0 "No Action" 7 "Auto" 6 "Performance Mode 6" 5 "Performance Mode 5" ;
VAL_ 2151383040 TreInfMonSysRstReq 1 "true" 0 "false" ;
VAL_ 2155421696 PsvEntAprchDrctn 0 "Driver" 1 "Co-Driver" 2 "Front" 3 "Rear" ;
VAL_ 2155421696 PsvEntApprchDtcd 1 "true" 0 "false" ;
VAL_ 2155421696 PsvEntApprchCnfgReq 0 "Level 0" 1 "Level 1" 2 "Level 2" 3 "Level 3" 4 "Level 4" 5 "Level 5" 6 "Level 6" 7 "Level 7" ;
VAL_ 2155421696 ServKylsStSysIO 1 "true" 0 "false" ;
VAL_ 2155413504 PsvLckngReqd 1 "true" 0 "false" ;
VAL_ 2155413504 DrvrDrKeyCylUlkSwAct 1 "true" 0 "false" ;
VAL_ 2155413504 DrvrDrKeyCylUlkSwActV 1 "Invalid" 0 "Valid" ;
VAL_ 2159026176 ODD_InvldData 1 "true" 0 "false" ;
VAL_ 2159026176 ODD_DataType 21 "Bitmap" 20 "DecimalShort" 19 "HoursOfDay" 18 "Character" 17 "Fuel Consumption Inverted" 16 "Fuel Consumption" 15 "Pressure" 14 "Temperature" 13 "Volume" 12 "DistanceShort" 11 "DistanceLong" 10 "BitmapId" 9 "TextId" 8 "Pictogram" 7 "List " 6 "Date" 5 "Time " 4 "Decimal" 3 "EnumerationValue" 2 "Integer" 1 "String" 0 "Speed" ;
VAL_ 2158845952 ODIAC_DspMID 128 "Reserved" 64 "Reserved" 32 "OTIM" 16 "RearDisplayTwo" 8 "RearDisplayOne" 4 "AuxIP" 2 "CenterStack" 1 "IPC" ;
VAL_ 2158845952 ODIAC_DaTy 21 "Bitmap" 20 "DecimalShort" 19 "HoursOfDay" 18 "Character" 17 "Fuel Consumption Inverted" 16 "Fuel Consumption" 15 "Pressure" 14 "Temperature" 13 "Volume" 12 "DistanceShort" 11 "DistanceLong" 10 "BitmapId" 9 "TextId" 8 "Pictogram" 7 "List " 6 "Date" 5 "Time " 4 "Decimal" 3 "EnumerationValue" 2 "Integer" 1 "String" 0 "Speed" ;
VAL_ 2151366656 PrkBrkSwAtv 1 "true" 0 "false" ;
VAL_ 2149842944 IMUProtLonAccV 1 "Invalid" 0 "Valid" ;
VAL_ 2149842944 VSELatAccV 1 "Invalid" 0 "Valid" ;
VAL_ 2149842944 StrWhAngV 1 "Invalid" 0 "Valid" ;
VAL_ 2149842944 TCSysAtv 1 "true" 0 "false" ;
VAL_ 2149842944 BrkSysAutBrkFld 1 "true" 0 "false" ;
VAL_ 2149842944 StrWhlAngSenCalStat 2 "Calibrated" 1 "Estimated" 0 "Unknown" ;
VAL_ 2149842944 VehStabEnhmntStat 4 "Not Ready" 3 "Warming Up" 2 "Fault" 1 "Active" 0 "Inactive" ;
VAL_ 2149842944 VehStabEnhmntMd 2 "Competitive" 1 "Normal" 0 "Off" ;
VAL_ 2149842944 VSEAct 1 "true" 0 "false" ;
VAL_ 2149842944 TCSysOpStat 2 "Fault" 1 "Active" 0 "Inactive" ;
VAL_ 2149842944 TCSysOpMd 2 "Off Road" 1 "Normal" 0 "Off" ;
VAL_ 2149842944 StWhAnVDA 1 "VirtualDeviceAvailable" 0 "VirtualDeviceUnavailable" ;
VAL_ 2151940096 EstIntHorzDshSrfTmpM 1 "Use Data" 0 "Don't Use Data" ;
VAL_ 2151940096 EstIntRfSrfcTmpV 1 "Invalid" 0 "Valid" ;
VAL_ 2151940096 EstBulkIntAirTmpV 1 "Invalid" 0 "Valid" ;
VAL_ 2151940096 HLOCCstCurrSetVal 3 "On Open Only" 2 "On" 1 "Off" 0 "No Action" ;
VAL_ 2151940096 A2ERRAlrmReq 2 "Cancel Alarm" 1 "Set Alarm" 0 "No Action" ;
VAL_ 2150645760 EnvIdRspSt1 3 "Environment_id_request" 2 "Incorrect_immo_id" 1 "Info_valid" 0 "No_info" ;
VAL_ 2152464384 RtLnDepWrnSt 3 "Service Alignment" 2 "Right Lane Alert" 1 "Right Lane Ready to Assist" 0 "Right Lane Not Ready to Assist" ;
VAL_ 2152464384 LftLnDepWrnSt 3 "Service Alignment" 2 "Left Lane Alert" 1 "Left Lane Ready to Assist" 0 "Left Lane Not Ready to Assist" ;
VAL_ 2152464384 TnDrvLDWOffUnbIO 1 "true" 0 "false" ;
VAL_ 2152464384 SrvcLnKpAstSysIO 1 "true" 0 "false" ;
VAL_ 2152464384 HndsOffStrWhlDtIO 1 "true" 0 "false" ;
VAL_ 2152464384 LnKpAstDisbldIO 1 "true" 0 "false" ;
VAL_ 2152464384 LKAIC_AdbWngLn 0 "Off" 1 "Left Front Speaker" 2 "Right Front Speaker" ;
VAL_ 2152464384 LKAIC_Ind2 1 "true" 0 "false" ;
VAL_ 2152464384 LKAIC_Ind1 1 "true" 0 "false" ;
VAL_ 2152464384 LKAIC_IndReq 0 "Off" 1 "Continuous Indication" 2 "Flash Rate #1 Indication" ;
VAL_ 2152464384 SrvcLaneDepWrnSysIO 1 "true" 0 "false" ;
VAL_ 2152464384 LDWIC_LnDepWAWLn 2 "Right Front Speaker" 1 "Left Front Speaker" 0 "Off" ;
VAL_ 2152464384 LDWIC_Ind2 1 "true" 0 "false" ;
VAL_ 2152464384 LDWIC_Ind1 1 "true" 0 "false" ;
VAL_ 2152464384 LDWIC_IndReq 2 "Flash Rate #1 Indication" 1 "Continuous Indication" 0 "Off" ;
VAL_ 2152464384 LaneDepWrnDisbldIO 1 "true" 0 "false" ;
VAL_ 2154971136 PassHCSeatSw3Act 1 "true" 0 "false" ;
VAL_ 2154971136 PassHCSeatSw2Act 1 "true" 0 "false" ;
VAL_ 2154971136 PassHCSeatSw1Act 1 "true" 0 "false" ;
VAL_ 2154971136 DrvHCSeatSw3Act 1 "true" 0 "false" ;
VAL_ 2154971136 DrvHCSeatSw2Act 1 "true" 0 "false" ;
VAL_ 2154971136 DrvHCSeatSw1Act 1 "true" 0 "false" ;
VAL_ 2154962944 PassHCSMInd3 1 "true" 0 "false" ;
VAL_ 2154962944 PassHCSMInd2 1 "true" 0 "false" ;
VAL_ 2154962944 PassHCSMInd1 1 "true" 0 "false" ;
VAL_ 2154962944 PassHCSMIndReq 3 "Flash Rate #2 Indication" 2 "Flash Rate #1 Indication" 1 "Continuous Indication" 0 "Off" ;
VAL_ 2154962944 PassHCSLSeatLev5 1 "true" 0 "false" ;
VAL_ 2154962944 PassHCSLSeatLev4 1 "true" 0 "false" ;
VAL_ 2154962944 PassHCSLSeatLev3 1 "true" 0 "false" ;
VAL_ 2154962944 PassHCSLSeatLev2 1 "true" 0 "false" ;
VAL_ 2154962944 PassHCSLSeatLev1 1 "true" 0 "false" ;
VAL_ 2154962944 PassHCSLIndReq 3 "Flash Rate #2 Indication" 2 "Flash Rate #1 Indication" 1 "Continuous Indication" 0 "Off" ;
VAL_ 2154962944 DrvHCSMInd1 1 "true" 0 "false" ;
VAL_ 2154962944 DrvHCSMIndReq 3 "Flash Rate #2 Indication" 2 "Flash Rate #1 Indication" 1 "Continuous Indication" 0 "Off" ;
VAL_ 2154962944 DrvHCSMInd3 1 "true" 0 "false" ;
VAL_ 2154962944 DrvHCSMInd2 1 "true" 0 "false" ;
VAL_ 2154962944 DrvHCSLSeatLev5 1 "true" 0 "false" ;
VAL_ 2154962944 DrvHCSLSeatLev4 1 "true" 0 "false" ;
VAL_ 2154962944 DrvHCSLSeatLev3 1 "true" 0 "false" ;
VAL_ 2154962944 DrvHCSLSeatLev2 1 "true" 0 "false" ;
VAL_ 2154962944 DrvHCSLSeatLev1 1 "true" 0 "false" ;
VAL_ 2154962944 DrvHCSLIndReq 3 "Flash Rate #2 Indication" 2 "Flash Rate #1 Indication" 1 "Continuous Indication" 0 "Off" ;
VAL_ 2156232704 ACSAlarm9 2 "Expired" 1 "Active" 0 "Inactive" ;
VAL_ 2156232704 ACSAlarm8 2 "Expired" 1 "Active" 0 "Inactive" ;
VAL_ 2156232704 ACSAlarm7 2 "Expired" 1 "Active" 0 "Inactive" ;
VAL_ 2156232704 ACSAlarm6 2 "Expired" 1 "Active" 0 "Inactive" ;
VAL_ 2156232704 ACSAlarm5 2 "Expired" 1 "Active" 0 "Inactive" ;
VAL_ 2156232704 ACSAlarm4 2 "Expired" 1 "Active" 0 "Inactive" ;
VAL_ 2156232704 ACSAlarm3 2 "Expired" 1 "Active" 0 "Inactive" ;
VAL_ 2156232704 ACSAlarm2 2 "Expired" 1 "Active" 0 "Inactive" ;
VAL_ 2156232704 ACSAlarm15 2 "Expired" 1 "Active" 0 "Inactive" ;
VAL_ 2156232704 ACSAlarm14 2 "Expired" 1 "Active" 0 "Inactive" ;
VAL_ 2156232704 ACSAlarm13 2 "Expired" 1 "Active" 0 "Inactive" ;
VAL_ 2156232704 ACSAlarm12 2 "Expired" 1 "Active" 0 "Inactive" ;
VAL_ 2156232704 ACSAlarm11 2 "Expired" 1 "Active" 0 "Inactive" ;
VAL_ 2156232704 ACSAlarm10 2 "Expired" 1 "Active" 0 "Inactive" ;
VAL_ 2156232704 ACSAlarm1 2 "Expired" 1 "Active" 0 "Inactive" ;
VAL_ 2156232704 ACSAlarm0 2 "Expired" 1 "Active" 0 "Inactive" ;
VAL_ 2154987520 WrlsChrgSysChrgStat 0 "WCS Not Present" 1 "Charging Inactive" 2 "Charging Active" 3 "Charging Complete" ;
VAL_ 2154987520 HdStV 1 "Invalid" 0 "Valid" ;
VAL_ 2154987520 HdSt 2 "Open" 1 "Ajar" 0 "Closed" ;
VAL_ 2154840064 CmpsZnNvrSet 1 "true" 0 "false" ;
VAL_ 2154840064 CmpsSatrtd 1 "true" 0 "false" ;
VAL_ 2154840064 CmpsDecZone 15 "Zone 15" 14 "Zone 14" 13 "Zone 13" 12 "Zone 12" 11 "Zone 11" 10 "Zone 10" 9 "Zone 9" 8 "Zone 8" 7 "Zone 7" 6 "Zone 6" 5 "Zone 5" 4 "Zone 4" 3 "Zone 3" 2 "Zone 2" 1 "Zone 1" 0 "Unknown" ;
VAL_ 2154840064 CmpsOctHdingDataSrc 1 "Calculated Value" 0 "Stored Value" ;
VAL_ 2154840064 CmpsOctHding 7 "NW (North West)" 6 "W (West)" 5 "SW (South West)" 4 "S (South)" 3 "SE (South East)" 2 "E (East)" 1 "NE (North East)" 0 "N (North)" ;
VAL_ 2154840064 CmpsModManCalInPrc 1 "true" 0 "false" ;
VAL_ 2154840064 CmpsModFltPrs 1 "true" 0 "false" ;
VAL_ 2154676224 CmpsModSlfTstReq 1 "Initiate Self Test" 0 "No Action" ;
VAL_ 2154676224 CmpsModManCalReq 1 "Calibrate Sensor" 0 "No Action" ;
VAL_ 2154676224 CmpsDecZonSetReq 1 "Set New Zone" 0 "No Request" ;
VAL_ 2154676224 CmpsDecZonCmndVal 15 "Zone 15" 14 "Zone 14" 13 "Zone 13" 12 "Zone 12" 11 "Zone 11" 10 "Zone 10" 9 "Zone 9" 8 "Zone 8" 7 "Zone 7" 6 "Zone 6" 5 "Zone 5" 4 "Zone 4" 3 "Zone 3" 2 "Zone 2" 1 "Zone 1" 0 "Unknown" ;
VAL_ 2154643456 HtrCoreInltClntTmpCalcV 1 "Invalid" 0 "Valid" ;
VAL_ 2154643456 AuxHtrAtv 1 "true" 0 "false" ;
VAL_ 2154905600 DrvSeatPrsMemID 0 "Memory #1" 1 "Memory #2" 2 "Memory #3" 3 "Memory #4" 4 "Memory #5" 5 "Memory #6" 6 "Memory #7" 7 "Unknown" ;
VAL_ 2154905600 DrId 7 "Unknown" 6 "Driver #7" 5 "Driver #6" 4 "Driver #5" 3 "Driver #4" 2 "Driver #3" 1 "Driver #2" 0 "Driver #1" ;
VAL_ 2154954752 HtdStWhlCmd 3 "High" 2 "Medium" 1 "Low" 0 "Off" ;
VAL_ 2154954752 HtdStWhlCtrlSrc 1 "Remote Switch Control" 0 "Local Switch Control" ;
VAL_ 2154954752 HtdStWhlInd 3 "High" 2 "Medium" 1 "Low" 0 "Off" ;
VAL_ 2154954752 ClmtHtPwrRqd 1 "true" 0 "false" ;
VAL_ 2149752832 HlStrAssActIO 1 "true" 0 "false" ;
VAL_ 2149752832 GNCustSetngAvlbl 1 "true" 0 "false" ;
VAL_ 2149752832 GNCustCrntStngVal 0 "No Action" 1 "Off" 2 "On" ;
VAL_ 2149752832 ColPrSysStngAvl 1 "true" 0 "false" ;
VAL_ 2149752832 ColPrSysCrntStng 4 "Alert and Brake and Steer" 0 "No Action" 1 "Off" 2 "Alert" 3 "Alert and Brake" ;
VAL_ 2149752832 ElecPrkBrkStat 2 "Fault" 1 "Applied" 0 "Released" ;
VAL_ 2149752832 EBDFailed 1 "true" 0 "false" ;
VAL_ 2149752832 ABSAtv 1 "true" 0 "false" ;
VAL_ 2149752832 PowStVDA 1 "VirtualDeviceAvailable" 0 "VirtualDeviceUnavailable" ;
VAL_ 2149752832 RrDrCntVDA 1 "VirtualDeviceAvailable" 0 "VirtualDeviceUnavailable" ;
VAL_ 2149752832 SprTireSt 2 "Spare Detected" 1 "No Spare Detected" 0 "Undetermined" ;
VAL_ 2149752832 BrkSysVDA 1 "VirtualDeviceAvailable" 0 "VirtualDeviceUnavailable" ;
VAL_ 2149752832 IntBrkAssPreFilReq 1 "true" 0 "false" ;
VAL_ 2149752832 EPBSysDspMsgReq 7 "Message #7" 6 "Message #6" 5 "Message #5" 4 "Message #4" 3 "Message #3" 2 "Message #2" 1 "Message #1" 0 "Off" ;
VAL_ 2149752832 EPBSysAudWarnReq 2 "Warning #2" 1 "Warning #1" 0 "Off" ;
VAL_ 2149752832 BksOvht 1 "true" 0 "false" ;
VAL_ 2149752832 BrkSysRedBrkTlltlReq 1 "true" 0 "false" ;
VAL_ 2149752832 HalfSysFail 1 "true" 0 "false" ;
VAL_ 2149752832 PrkBrkVDA 1 "VirtualDeviceAvailable" 0 "VirtualDeviceUnavailable" ;
VAL_ 2151514112 EngOilLfRstRq 1 "true" 0 "false" ;
VAL_ 2158911488 ODDMC_ReqType 0 "Subscribe: FU sends DynData back and then on change) " 1 "Unsubscribe: cancel previous Subscribe" ;
VAL_ 2158911488 ODDMC_DispMID 128 "Reserved" 64 "Reserved" 32 "OTIM" 16 "RearDisplayTwo" 8 "RearDisplayOne" 4 "AuxIP" 2 "CenterStack" 1 "IPC" ;
VAL_ 2158911488 ODDMC_DataID2Vld 1 "true" 0 "false" ;
VAL_ 2158911488 ODDMC_DataID3Vld 1 "true" 0 "false" ;
VAL_ 2158911488 ODDMC_DataID4Vld 1 "true" 0 "false" ;
VAL_ 2158911488 ODDMC_DataID5Vld 1 "true" 0 "false" ;
VAL_ 2158919680 ODDMI_ReqType 0 "Subscribe: FU sends DynData back and then on change) " 1 "Unsubscribe: cancel previous Subscribe" ;
VAL_ 2158919680 ODDMI_DispMID 128 "Reserved" 64 "Reserved" 32 "OTIM" 16 "RearDisplayTwo" 8 "RearDisplayOne" 4 "AuxIP" 2 "CenterStack" 1 "IPC" ;
VAL_ 2158919680 ODDMI_DataID2Vld 1 "true" 0 "false" ;
VAL_ 2158919680 ODDMI_DataID3Vld 1 "true" 0 "false" ;
VAL_ 2158919680 ODDMI_DataID4Vld 1 "true" 0 "false" ;
VAL_ 2158919680 ODDMI_DataID5Vld 1 "true" 0 "false" ;
VAL_ 2151825408 OtsAirTmpV 1 "Invalid" 0 "Valid" ;
VAL_ 2151825408 OtsAirTmpCrValV 1 "Invalid" 0 "Valid" ;
VAL_ 2151825408 OtsAirTmpCrValMsk 1 "Use Data" 0 "Don't Use Data" ;
VAL_ 2151153664 RrWndDfgOn 1 "true" 0 "false" ;
VAL_ 2151170048 RrEndCrrStat 0 "Not Extended" 1 "Extended" ;
VAL_ 2151170048 RRPrkLmpFld 1 "true" 0 "false" ;
VAL_ 2151170048 RLftPrkLmpFld 1 "true" 0 "false" ;
VAL_ 2151170048 DisRrPrmryLmps 1 "true" 0 "false" ;
VAL_ 2151170048 TrlrTlLtFld 1 "true" 0 "false" ;
VAL_ 2151170048 TrlrRvsLtFld 1 "true" 0 "false" ;
VAL_ 2151170048 TrlrFgLtFld 1 "true" 0 "false" ;
VAL_ 2151170048 TrlrBrkLtFld 1 "true" 0 "false" ;
VAL_ 2151170048 TrlrRtTrInLtFld 1 "true" 0 "false" ;
VAL_ 2151170048 TrlLfTrInLtFld 1 "true" 0 "false" ;
VAL_ 2151170048 TrlrHtchSwAtv 1 "true" 0 "false" ;
VAL_ 2151170048 RtSecTrnIndFld 1 "true" 0 "false" ;
VAL_ 2151170048 TrlrFgLtPrs 1 "true" 0 "false" ;
VAL_ 2151170048 LftSecTrnIndFld 1 "true" 0 "false" ;
VAL_ 2151841792 WSWprAct 1 "true" 0 "false" ;
VAL_ 2151841792 RnSnsOffIO 1 "true" 0 "false" ;
VAL_ 2151841792 RnSnsActIO 1 "true" 0 "false" ;
VAL_ 2151841792 TurnWprIntIO 1 "true" 0 "false" ;
VAL_ 2154995712 HVHtrFldIO 1 "true" 0 "false" ;
VAL_ 2154995712 HVHtrOvrTmpIndOn 1 "true" 0 "false" ;
VAL_ 2154094592 IntDimSeldClrTypStVal 31 "Color Type 30" 30 "Color Type 29" 29 "Color Type 28" 28 "Color Type 27" 27 "Color Type 26" 26 "Color Type 25" 25 "Color Type 24" 24 "Color Type 23" 23 "Color Type 22" 22 "Color Type 21" 21 "Color Type 20" 20 "Color Type 19" 19 "Color Type 18" 18 "Color Type 17" 17 "Color Type 16" 16 "Color Type 15" 15 "Color Type 14" 14 "Color Type 13" 13 "Color Type 12" 12 "Color Type 11" 11 "Color Type 10" 10 "Color Type 9" 9 "Color Type 8" 8 "Color Type 7" 7 "Color Type 6" 6 "Color Type 5" 5 "Color Type 4" 4 "Color Type 3" 3 "Color Type 2" 2 "Color Type 1" 1 "Off" 0 "No Action" ;
VAL_ 2154094592 IntDimSeldAnmTypStVal 15 "Animation Type 14" 14 "Animation Type 13" 13 "Animation Type 12" 12 "Animation Type 11" 11 "Animation Type 10" 10 "Animation Type 9" 9 "Animation Type 8" 8 "Animation Type 7" 7 "Animation Type 6" 6 "Animation Type 5" 5 "Animation Type 4" 4 "Animation Type 3" 3 "Animation Type 2" 2 "Animation Type 1" 1 "Off" 0 "No Action" ;
VAL_ 2154094592 IDCTA_ClrTyp30Avl 1 "true" 0 "false" ;
VAL_ 2154094592 IDCTA_ClrTyp29Avl 1 "true" 0 "false" ;
VAL_ 2154094592 IDCTA_ClrTyp28Avl 1 "true" 0 "false" ;
VAL_ 2154094592 IDCTA_ClrTyp27Avl 1 "true" 0 "false" ;
VAL_ 2154094592 IDCTA_ClrTyp26Avl 1 "true" 0 "false" ;
VAL_ 2154094592 IDCTA_ClrTyp25Avl 1 "true" 0 "false" ;
VAL_ 2154094592 IDCTA_ClrTyp24Avl 1 "true" 0 "false" ;
VAL_ 2154094592 IDCTA_ClrTyp23Avl 1 "true" 0 "false" ;
VAL_ 2154094592 IDCTA_ClrTyp22Avl 1 "true" 0 "false" ;
VAL_ 2154094592 IDCTA_ClrTyp21Avl 1 "true" 0 "false" ;
VAL_ 2154094592 IDCTA_ClrTyp20Avl 1 "true" 0 "false" ;
VAL_ 2154094592 IDCTA_ClrTyp19Avl 1 "true" 0 "false" ;
VAL_ 2154094592 IDCTA_ClrTyp18Avl 1 "true" 0 "false" ;
VAL_ 2154094592 IDCTA_ClrTyp17Avl 1 "true" 0 "false" ;
VAL_ 2154094592 IDCTA_ClrTyp16Avl 1 "true" 0 "false" ;
VAL_ 2154094592 IDCTA_ClrTyp15Avl 1 "true" 0 "false" ;
VAL_ 2154094592 IDCTA_ClrTyp14Avl 1 "true" 0 "false" ;
VAL_ 2154094592 IDCTA_ClrTyp13Avl 1 "true" 0 "false" ;
VAL_ 2154094592 IDCTA_ClrTyp12Avl 1 "true" 0 "false" ;
VAL_ 2154094592 IDCTA_ClrTyp11Avl 1 "true" 0 "false" ;
VAL_ 2154094592 IDCTA_ClrTyp10Avl 1 "true" 0 "false" ;
VAL_ 2154094592 IDCTA_ClrTyp9Avl 1 "true" 0 "false" ;
VAL_ 2154094592 IDCTA_ClrTyp8Avl 1 "true" 0 "false" ;
VAL_ 2154094592 IDCTA_ClrTyp7Avl 1 "true" 0 "false" ;
VAL_ 2154094592 IDCTA_ClrTyp6Avl 1 "true" 0 "false" ;
VAL_ 2154094592 IDCTA_ClrTyp5Avl 1 "true" 0 "false" ;
VAL_ 2154094592 IDCTA_ClrTyp4Avl 1 "true" 0 "false" ;
VAL_ 2154094592 IDCTA_ClrTyp3Avl 1 "true" 0 "false" ;
VAL_ 2154094592 IDCTA_ClrTyp2Avl 1 "true" 0 "false" ;
VAL_ 2154094592 IDCTA_ClrTyp1Avl 1 "true" 0 "false" ;
VAL_ 2154094592 IDCTA_OffAvl 1 "true" 0 "false" ;
VAL_ 2154094592 IDATA_AnmTyp14Avl 1 "true" 0 "false" ;
VAL_ 2154094592 IDATA_AnmTyp13Avl 1 "true" 0 "false" ;
VAL_ 2154094592 IDATA_AnmTyp12Avl 1 "true" 0 "false" ;
VAL_ 2154094592 IDATA_AnmTyp11Avl 1 "true" 0 "false" ;
VAL_ 2154094592 IDATA_AnmTyp10Avl 1 "true" 0 "false" ;
VAL_ 2154094592 IDATA_AnmTyp9Avl 1 "true" 0 "false" ;
VAL_ 2154094592 IDATA_AnmTyp8Avl 1 "true" 0 "false" ;
VAL_ 2154094592 IDATA_AnmTyp7Avl 1 "true" 0 "false" ;
VAL_ 2154094592 IDATA_AnmTyp6Avl 1 "true" 0 "false" ;
VAL_ 2154094592 IDATA_AnmTyp5Avl 1 "true" 0 "false" ;
VAL_ 2154094592 IDATA_AnmTyp4Avl 1 "true" 0 "false" ;
VAL_ 2154094592 IDATA_AnmTyp3Avl 1 "true" 0 "false" ;
VAL_ 2154094592 IDATA_AnmTyp2Avl 1 "true" 0 "false" ;
VAL_ 2154094592 IDATA_AnmTyp1Avl 1 "true" 0 "false" ;
VAL_ 2154094592 IDATA_OffAvl 1 "true" 0 "false" ;
VAL_ 2154094592 AdjPdlMotInhbtd 1 "true" 0 "false" ;
SIG_GROUP_ 2151063552 ICSTchStat 1 : ICSTS_Y1TchCrdnt ICSTS_X1TchCrdnt ICSTS_TchPrxmty;
SIG_GROUP_ 2159026176 ODIDynData 1 : ODD_InvldData ODD_FUCID ODD_DataVal ODD_DataType ODD_DataId;
SIG_GROUP_ 2158936064 ODIEnmDynData 1 : ODIEDD_Data18Value ODIEDD_Data17Value ODIEDD_Data16Value ODIEDD_Data15Value ODIEDD_Data14Value ODIEDD_Data13Value ODIEDD_Data12Value ODIEDD_Data11Value ODIEDD_Data10Value ODIEDD_Data9Value ODIEDD_Data8Value ODIEDD_Data7Value ODIEDD_Data6Value ODIEDD_Data5Value ODIEDD_Data4Value ODIEDD_Data3Value ODIEDD_Data2Value ODIEDD_Data1Value ODIEDD_FUCID;
SIG_GROUP_ 2158845952 ODIActn_CntrStck 1 : ODIAC_FUCID ODIAC_DspMID ODIAC_DaTy ODIAC_ActnVal ODIAC_ActnID;
SIG_GROUP_ 2151940096 Alrm2ExtRngReq 1 : A2ERRAlrmTime A2ERRAlrmReq;
SIG_GROUP_ 2152464384 LnKpAstIndCntrl 1 : LKAIC_AdbWngLn LKAIC_Ind2 LKAIC_Ind1 LKAIC_IndReq;
SIG_GROUP_ 2152464384 LaneDepWrnIndCntrl 1 : LDWIC_LnDepWAWLn LDWIC_Ind2 LDWIC_Ind1 LDWIC_IndReq;
SIG_GROUP_ 2154962944 PassHCSModeIndCtrl 1 : PassHCSMInd3 PassHCSMInd2 PassHCSMInd1 PassHCSMIndReq;
SIG_GROUP_ 2154962944 PassHCSeatLevIndCtrl 1 : PassHCSLSeatLev5 PassHCSLSeatLev4 PassHCSLSeatLev3 PassHCSLSeatLev2 PassHCSLSeatLev1 PassHCSLIndReq;
SIG_GROUP_ 2154962944 DrvHCSModeIndCtrl 1 : DrvHCSMInd1 DrvHCSMIndReq DrvHCSMInd3 DrvHCSMInd2;
SIG_GROUP_ 2154962944 DrvHCSLevIndCtrl 1 : DrvHCSLSeatLev5 DrvHCSLSeatLev4 DrvHCSLSeatLev3 DrvHCSLSeatLev2 DrvHCSLSeatLev1 DrvHCSLIndReq;
SIG_GROUP_ 2156232704 AlrmClkStat 1 : ACSAlarm9 ACSAlarm8 ACSAlarm7 ACSAlarm6 ACSAlarm5 ACSAlarm4 ACSAlarm3 ACSAlarm2 ACSAlarm15 ACSAlarm14 ACSAlarm13 ACSAlarm12 ACSAlarm11 ACSAlarm10 ACSAlarm1 ACSAlarm0;
SIG_GROUP_ 2158911488 ODIDynDataMltRq_CntrStck 1 : ODDMC_ReqType ODDMC_DispMID ODDMC_DataID2Vld ODDMC_DataID2 ODDMC_DataID3Vld ODDMC_DataID3 ODDMC_DataID1 ODDMC_DataID4Vld ODDMC_DataID4 ODDMC_DataID5Vld ODDMC_DataID5 ODDMC_FUCID;
SIG_GROUP_ 2158919680 ODIDynDataMltRq_IPC 1 : ODDMI_ReqType ODDMI_FUCID ODDMI_DispMID ODDMI_DataID2Vld ODDMI_DataID2 ODDMI_DataID3Vld ODDMI_DataID3 ODDMI_DataID1 ODDMI_DataID4Vld ODDMI_DataID4 ODDMI_DataID5Vld ODDMI_DataID5;
SIG_GROUP_ 2154094592 IntDimClrTypAvl 1 : IDCTA_ClrTyp30Avl IDCTA_ClrTyp29Avl IDCTA_ClrTyp28Avl IDCTA_ClrTyp27Avl IDCTA_ClrTyp26Avl IDCTA_ClrTyp25Avl IDCTA_ClrTyp24Avl IDCTA_ClrTyp23Avl IDCTA_ClrTyp22Avl IDCTA_ClrTyp21Avl IDCTA_ClrTyp20Avl IDCTA_ClrTyp19Avl IDCTA_ClrTyp18Avl IDCTA_ClrTyp17Avl IDCTA_ClrTyp16Avl IDCTA_ClrTyp15Avl IDCTA_ClrTyp14Avl IDCTA_ClrTyp13Avl IDCTA_ClrTyp12Avl IDCTA_ClrTyp11Avl IDCTA_ClrTyp10Avl IDCTA_ClrTyp9Avl IDCTA_ClrTyp8Avl IDCTA_ClrTyp7Avl IDCTA_ClrTyp6Avl IDCTA_ClrTyp5Avl IDCTA_ClrTyp4Avl IDCTA_ClrTyp3Avl IDCTA_ClrTyp2Avl IDCTA_ClrTyp1Avl IDCTA_OffAvl;
SIG_GROUP_ 2154094592 IntDimAnmTypAvl 1 : IDATA_AnmTyp14Avl IDATA_AnmTyp13Avl IDATA_AnmTyp12Avl IDATA_AnmTyp11Avl IDATA_AnmTyp10Avl IDATA_AnmTyp9Avl IDATA_AnmTyp8Avl IDATA_AnmTyp7Avl IDATA_AnmTyp6Avl IDATA_AnmTyp5Avl IDATA_AnmTyp4Avl IDATA_AnmTyp3Avl IDATA_AnmTyp2Avl IDATA_AnmTyp1Avl IDATA_OffAvl;
